VERSION ""

NS_ :

BS_:

BU_: SVB1 Tester Gateway CDS1 CDS2 ADV IRC AVP AVM PDC ADB1 ADB2 HDMAP DSM Fradar LCDA1 LCDA2

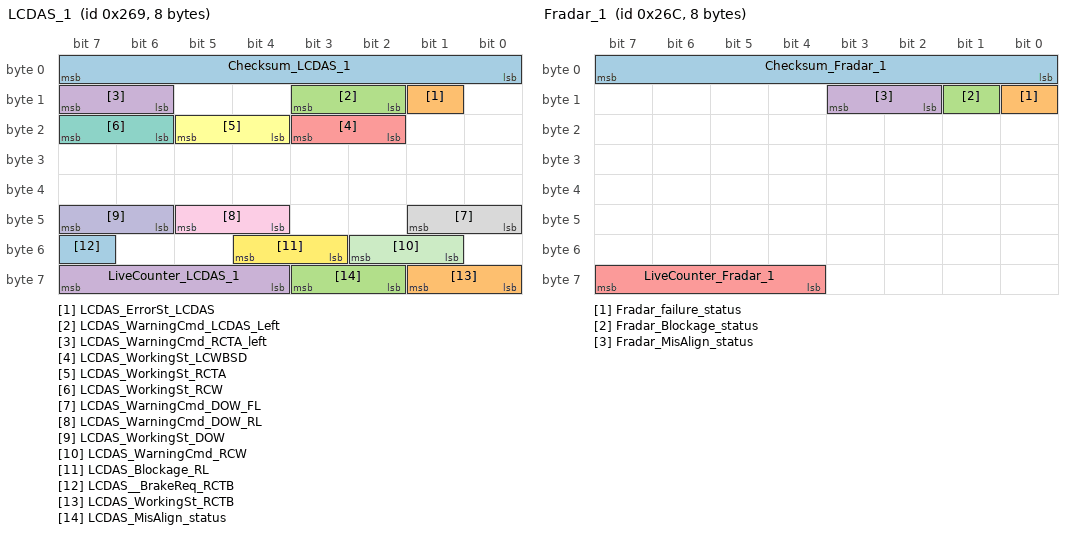
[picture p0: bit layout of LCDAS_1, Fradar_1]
BO_ 617 LCDAS_1: 8 CDS1
 SG_ Checksum_LCDAS_1 : 0|8@1+ (1,0) [0|255] ""  Gateway,ADV,LCDA1
 SG_ LCDAS_ErrorSt_LCDAS : 9|1@1+ (1,0) [0|1] ""  ADV
 SG_ LCDAS_WarningCmd_LCDAS_Left : 10|2@1+ (1,0) [0|3] ""  LCDA1
 SG_ LCDAS_WarningCmd_RCTA_left : 14|2@1+ (1,0) [0|3] ""  LCDA1
 SG_ LCDAS_WorkingSt_LCWBSD : 18|2@1+ (1,0) [0|3] ""  LCDA1
 SG_ LCDAS_WorkingSt_RCTA : 20|2@1+ (1,0) [0|3] ""  LCDA1
 SG_ LCDAS_WorkingSt_RCW : 22|2@1+ (1,0) [0|3] ""  LCDA1
 SG_ LCDAS_WarningCmd_DOW_FL : 40|2@1+ (1,0) [0|3] ""  LCDA1
 SG_ LCDAS_WarningCmd_DOW_RL : 44|2@1+ (1,0) [0|3] ""  LCDA1
 SG_ LCDAS_WorkingSt_DOW : 46|2@1+ (1,0) [0|3] ""  LCDA1
 SG_ LCDAS_WarningCmd_RCW : 49|2@1+ (1,0) [0|3] ""  LCDA1
 SG_ LCDAS_Blockage_RL : 51|2@1+ (1,0) [0|1] ""  Gateway,ADV
 SG_ LCDAS__BrakeReq_RCTB : 55|1@1+ (1,0) [0|1] ""  ADV,LCDA1
 SG_ LCDAS_WorkingSt_RCTB : 56|2@1+ (1,0) [0|3] ""  LCDA1
 SG_ LCDAS_MisAlign_status : 58|2@1+ (1,0) [0|3] ""  ADV
 SG_ LiveCounter_LCDAS_1 : 60|4@1+ (1,0) [0|15] "Pulse"  Gateway,ADV,LCDA1

BO_ 620 Fradar_1: 8 Fradar
 SG_ Checksum_Fradar_1 : 0|8@1+ (1,0) [0|255] ""  Gateway,AVP
 SG_ Fradar_failure_status : 8|1@1+ (1,0) [0|1] ""  AVP
 SG_ Fradar_Blockage_status : 9|1@1+ (1,0) [0|1] ""  Gateway,AVP
 SG_ Fradar_MisAlign_status : 10|2@1+ (1,0) [0|3] ""  AVP
 SG_ LiveCounter_Fradar_1 : 60|4@1+ (1,0) [0|15] ""  Gateway,AVP

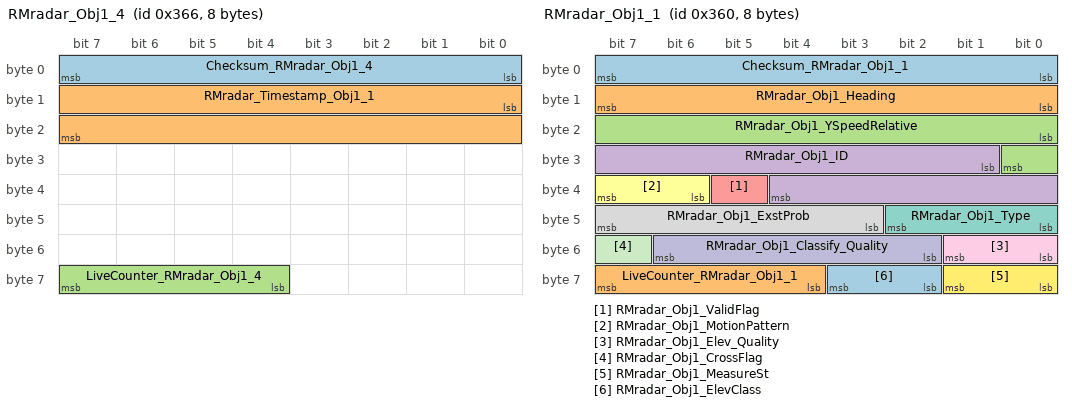
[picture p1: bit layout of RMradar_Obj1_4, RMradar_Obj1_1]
BO_ 870 RMradar_Obj1_4: 8 LCDA1
 SG_ Checksum_RMradar_Obj1_4 : 0|8@1+ (1,0) [0|255] ""  ADV
 SG_ RMradar_Timestamp_Obj1_1 : 8|16@1+ (0.1,0) [0|6553.5] "ms"  ADV
 SG_ LiveCounter_RMradar_Obj1_4 : 60|4@1+ (1,0) [0|15] ""  ADV

BO_ 864 RMradar_Obj1_1: 8 LCDA1
 SG_ Checksum_RMradar_Obj1_1 : 0|8@1+ (1,0) [0|255] ""  ADV
 SG_ RMradar_Obj1_Heading : 8|8@1+ (2.88,-180) [-180|554.4] "°„"  ADV
 SG_ RMradar_Obj1_YSpeedRelative : 16|9@1+ (0.2,-50) [-50|52.2] "m/s"  ADV
 SG_ RMradar_Obj1_ID : 25|12@1+ (1,0) [0|4095] ""  ADV
 SG_ RMradar_Obj1_ValidFlag : 37|1@1+ (1,0) [0|1] ""  ADV
 SG_ RMradar_Obj1_MotionPattern : 38|2@1+ (1,0) [0|3] ""  ADV
 SG_ RMradar_Obj1_Type : 40|3@1+ (1,0) [0|7] ""  ADV
 SG_ RMradar_Obj1_ExstProb : 43|5@1+ (5,0) [0|155] "%"  ADV
 SG_ RMradar_Obj1_Elev_Quality : 48|2@1+ (1,0) [0|3] ""  ADV
 SG_ RMradar_Obj1_Classify_Quality : 50|5@1+ (5,0) [0|155] "%"  ADV
 SG_ RMradar_Obj1_CrossFlag : 55|1@1+ (1,0) [0|1] ""  ADV
 SG_ RMradar_Obj1_MeasureSt : 56|2@1+ (1,0) [0|3] ""  ADV
 SG_ RMradar_Obj1_ElevClass : 58|2@1+ (1,0) [0|3] ""  ADV
 SG_ LiveCounter_RMradar_Obj1_1 : 60|4@1+ (1,0) [0|15] ""  ADV

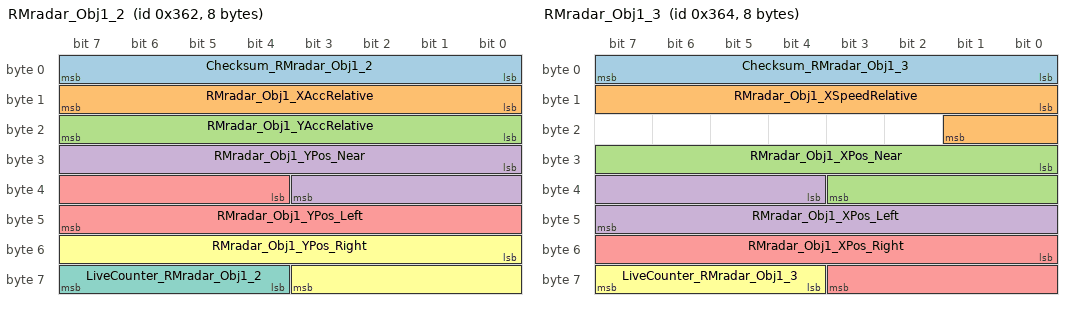
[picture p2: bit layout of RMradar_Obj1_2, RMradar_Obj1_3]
BO_ 866 RMradar_Obj1_2: 8 LCDA1
 SG_ Checksum_RMradar_Obj1_2 : 0|8@1+ (1,0) [0|255] ""  ADV
 SG_ RMradar_Obj1_XAccRelative : 8|8@1+ (0.2,-25.3) [-25.3|25.7] "m/s2"  ADV
 SG_ RMradar_Obj1_YAccRelative : 16|8@1+ (0.2,-25.3) [-25.3|25.7] "m/s2"  ADV
 SG_ RMradar_Obj1_YPos_Near : 24|12@1+ (0.05,-100) [-100|104.75] "m"  ADV
 SG_ RMradar_Obj1_YPos_Left : 36|12@1+ (0.05,-100) [-100|104.75] "m"  ADV
 SG_ RMradar_Obj1_YPos_Right : 48|12@1+ (0.05,-100) [-100|104.75] "m"  ADV
 SG_ LiveCounter_RMradar_Obj1_2 : 60|4@1+ (1,0) [0|15] ""  ADV

BO_ 868 RMradar_Obj1_3: 8 LCDA1
 SG_ Checksum_RMradar_Obj1_3 : 0|8@1+ (1,0) [0|255] ""  ADV
 SG_ RMradar_Obj1_XSpeedRelative : 8|10@1+ (0.2,-80) [-80|124.6] "m/s"  ADV
 SG_ RMradar_Obj1_XPos_Near : 24|12@1+ (0.05,-100) [-100|104.75] "m"  ADV
 SG_ RMradar_Obj1_XPos_Left : 36|12@1+ (0.05,-100) [-100|104.75] "m"  ADV
 SG_ RMradar_Obj1_XPos_Right : 48|12@1+ (0.05,-100) [-100|104.75] "m"  ADV
 SG_ LiveCounter_RMradar_Obj1_3 : 60|4@1+ (1,0) [0|15] ""  ADV

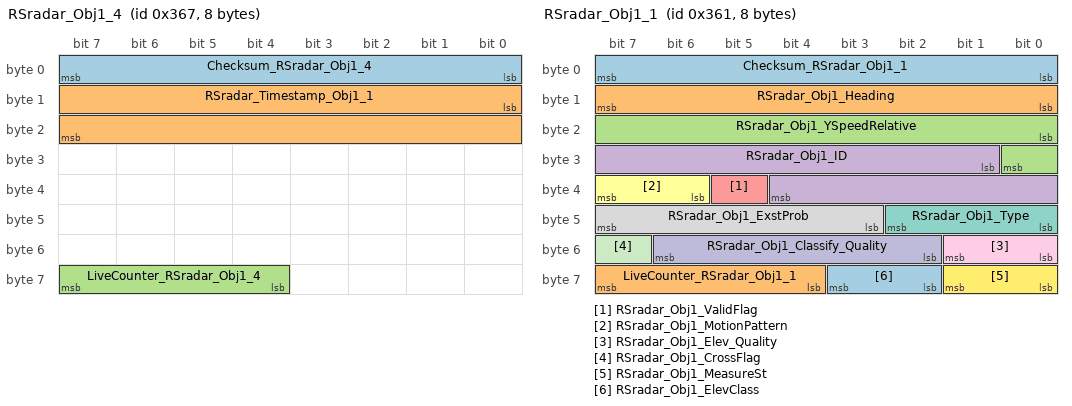
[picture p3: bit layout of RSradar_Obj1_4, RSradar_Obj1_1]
BO_ 871 RSradar_Obj1_4: 8 LCDA2
 SG_ Checksum_RSradar_Obj1_4 : 0|8@1+ (1,0) [0|255] ""  ADV
 SG_ RSradar_Timestamp_Obj1_1 : 8|16@1+ (0.1,0) [0|6553.5] "ms"  ADV
 SG_ LiveCounter_RSradar_Obj1_4 : 60|4@1+ (1,0) [0|15] ""  ADV

BO_ 865 RSradar_Obj1_1: 8 LCDA2
 SG_ Checksum_RSradar_Obj1_1 : 0|8@1+ (1,0) [0|255] ""  ADV
 SG_ RSradar_Obj1_Heading : 8|8@1+ (2.88,-180) [-180|554.4] "°„"  ADV
 SG_ RSradar_Obj1_YSpeedRelative : 16|9@1+ (0.2,-50) [-50|52.2] "m/s"  ADV
 SG_ RSradar_Obj1_ID : 25|12@1+ (1,0) [0|4095] ""  ADV
 SG_ RSradar_Obj1_ValidFlag : 37|1@1+ (1,0) [0|1] ""  ADV
 SG_ RSradar_Obj1_MotionPattern : 38|2@1+ (1,0) [0|3] ""  ADV
 SG_ RSradar_Obj1_Type : 40|3@1+ (1,0) [0|7] ""  ADV
 SG_ RSradar_Obj1_ExstProb : 43|5@1+ (5,0) [0|155] "%"  ADV
 SG_ RSradar_Obj1_Elev_Quality : 48|2@1+ (1,0) [0|3] ""  ADV
 SG_ RSradar_Obj1_Classify_Quality : 50|5@1+ (5,0) [0|155] "%"  ADV
 SG_ RSradar_Obj1_CrossFlag : 55|1@1+ (1,0) [0|1] ""  ADV
 SG_ RSradar_Obj1_MeasureSt : 56|2@1+ (1,0) [0|3] ""  ADV
 SG_ RSradar_Obj1_ElevClass : 58|2@1+ (1,0) [0|3] ""  ADV
 SG_ LiveCounter_RSradar_Obj1_1 : 60|4@1+ (1,0) [0|15] ""  ADV

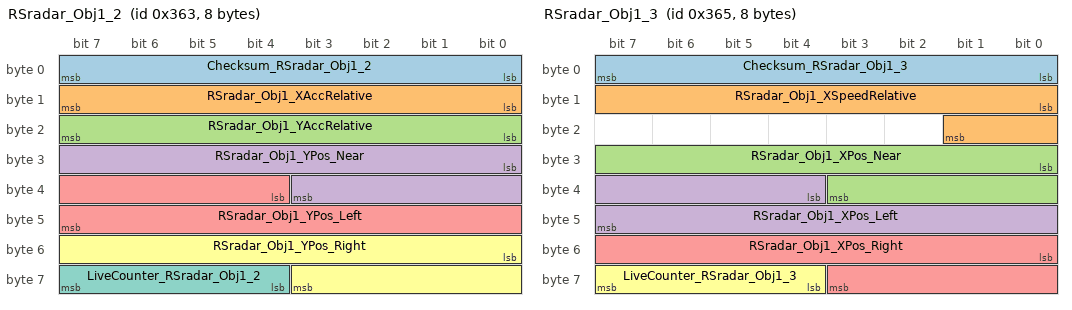
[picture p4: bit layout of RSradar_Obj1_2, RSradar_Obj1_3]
BO_ 867 RSradar_Obj1_2: 8 LCDA2
 SG_ Checksum_RSradar_Obj1_2 : 0|8@1+ (1,0) [0|255] ""  ADV
 SG_ RSradar_Obj1_XAccRelative : 8|8@1+ (0.2,-25.3) [-25.3|25.7] "m/s2"  ADV
 SG_ RSradar_Obj1_YAccRelative : 16|8@1+ (0.2,-25.3) [-25.3|25.7] "m/s2"  ADV
 SG_ RSradar_Obj1_YPos_Near : 24|12@1+ (0.05,-100) [-100|104.75] "m"  ADV
 SG_ RSradar_Obj1_YPos_Left : 36|12@1+ (0.05,-100) [-100|104.75] "m"  ADV
 SG_ RSradar_Obj1_YPos_Right : 48|12@1+ (0.05,-100) [-100|104.75] "m"  ADV
 SG_ LiveCounter_RSradar_Obj1_2 : 60|4@1+ (1,0) [0|15] ""  ADV

BO_ 869 RSradar_Obj1_3: 8 LCDA2
 SG_ Checksum_RSradar_Obj1_3 : 0|8@1+ (1,0) [0|255] ""  ADV
 SG_ RSradar_Obj1_XSpeedRelative : 8|10@1+ (0.2,-80) [-80|124.6] "m/s"  ADV
 SG_ RSradar_Obj1_XPos_Near : 24|12@1+ (0.05,-100) [-100|104.75] "m"  ADV
 SG_ RSradar_Obj1_XPos_Left : 36|12@1+ (0.05,-100) [-100|104.75] "m"  ADV
 SG_ RSradar_Obj1_XPos_Right : 48|12@1+ (0.05,-100) [-100|104.75] "m"  ADV
 SG_ LiveCounter_RSradar_Obj1_3 : 60|4@1+ (1,0) [0|15] ""  ADV

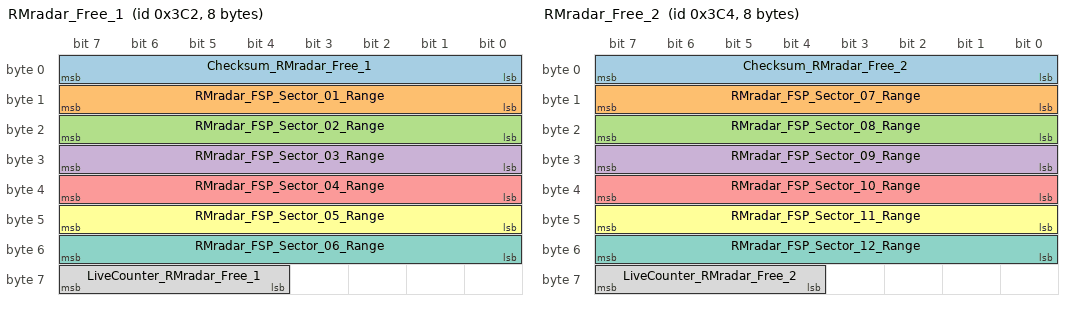
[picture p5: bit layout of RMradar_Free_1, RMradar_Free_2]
BO_ 962 RMradar_Free_1: 8 LCDA1
 SG_ Checksum_RMradar_Free_1 : 0|8@1+ (1,0) [0|255] ""  ADV
 SG_ RMradar_FSP_Sector_01_Range : 8|8@1+ (0.2,0) [0|51] "m"  ADV
 SG_ RMradar_FSP_Sector_02_Range : 16|8@1+ (0.2,0) [0|51] "m"  ADV
 SG_ RMradar_FSP_Sector_03_Range : 24|8@1+ (0.2,0) [0|51] "m"  ADV
 SG_ RMradar_FSP_Sector_04_Range : 32|8@1+ (0.2,0) [0|51] "m"  ADV
 SG_ RMradar_FSP_Sector_05_Range : 40|8@1+ (0.2,0) [0|51] "m"  ADV
 SG_ RMradar_FSP_Sector_06_Range : 48|8@1+ (0.2,0) [0|51] "m"  ADV
 SG_ LiveCounter_RMradar_Free_1 : 60|4@1+ (1,0) [0|15] ""  ADV

BO_ 964 RMradar_Free_2: 8 LCDA1
 SG_ Checksum_RMradar_Free_2 : 0|8@1+ (1,0) [0|255] ""  ADV
 SG_ RMradar_FSP_Sector_07_Range : 8|8@1+ (0.2,0) [0|51] "m"  ADV
 SG_ RMradar_FSP_Sector_08_Range : 16|8@1+ (0.2,0) [0|51] "m"  ADV
 SG_ RMradar_FSP_Sector_09_Range : 24|8@1+ (0.2,0) [0|51] "m"  ADV
 SG_ RMradar_FSP_Sector_10_Range : 32|8@1+ (0.2,0) [0|51] "m"  ADV
 SG_ RMradar_FSP_Sector_11_Range : 40|8@1+ (0.2,0) [0|51] "m"  ADV
 SG_ RMradar_FSP_Sector_12_Range : 48|8@1+ (0.2,0) [0|51] "m"  ADV
 SG_ LiveCounter_RMradar_Free_2 : 60|4@1+ (1,0) [0|15] ""  ADV

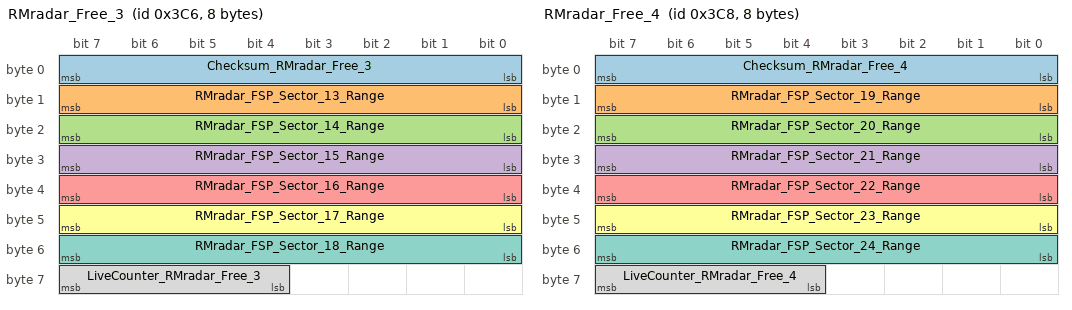
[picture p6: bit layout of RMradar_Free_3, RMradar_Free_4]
BO_ 966 RMradar_Free_3: 8 LCDA1
 SG_ Checksum_RMradar_Free_3 : 0|8@1+ (1,0) [0|255] ""  ADV
 SG_ RMradar_FSP_Sector_13_Range : 8|8@1+ (0.2,0) [0|51] "m"  ADV
 SG_ RMradar_FSP_Sector_14_Range : 16|8@1+ (0.2,0) [0|51] "m"  ADV
 SG_ RMradar_FSP_Sector_15_Range : 24|8@1+ (0.2,0) [0|51] "m"  ADV
 SG_ RMradar_FSP_Sector_16_Range : 32|8@1+ (0.2,0) [0|51] "m"  ADV
 SG_ RMradar_FSP_Sector_17_Range : 40|8@1+ (0.2,0) [0|51] "m"  ADV
 SG_ RMradar_FSP_Sector_18_Range : 48|8@1+ (0.2,0) [0|51] "m"  ADV
 SG_ LiveCounter_RMradar_Free_3 : 60|4@1+ (1,0) [0|15] ""  ADV

BO_ 968 RMradar_Free_4: 8 LCDA1
 SG_ Checksum_RMradar_Free_4 : 0|8@1+ (1,0) [0|255] ""  ADV
 SG_ RMradar_FSP_Sector_19_Range : 8|8@1+ (0.2,0) [0|51] "m"  ADV
 SG_ RMradar_FSP_Sector_20_Range : 16|8@1+ (0.2,0) [0|51] "m"  ADV
 SG_ RMradar_FSP_Sector_21_Range : 24|8@1+ (0.2,0) [0|51] "m"  ADV
 SG_ RMradar_FSP_Sector_22_Range : 32|8@1+ (0.2,0) [0|51] "m"  ADV
 SG_ RMradar_FSP_Sector_23_Range : 40|8@1+ (0.2,0) [0|51] "m"  ADV
 SG_ RMradar_FSP_Sector_24_Range : 48|8@1+ (0.2,0) [0|51] "m"  ADV
 SG_ LiveCounter_RMradar_Free_4 : 60|4@1+ (1,0) [0|15] ""  ADV

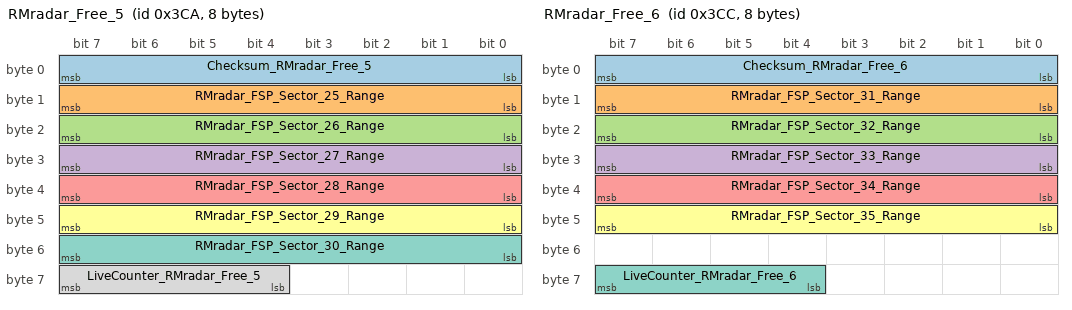
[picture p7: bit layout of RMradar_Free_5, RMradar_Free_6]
BO_ 970 RMradar_Free_5: 8 LCDA1
 SG_ Checksum_RMradar_Free_5 : 0|8@1+ (1,0) [0|255] ""  ADV
 SG_ RMradar_FSP_Sector_25_Range : 8|8@1+ (0.2,0) [0|51] "m"  ADV
 SG_ RMradar_FSP_Sector_26_Range : 16|8@1+ (0.2,0) [0|51] "m"  ADV
 SG_ RMradar_FSP_Sector_27_Range : 24|8@1+ (0.2,0) [0|51] "m"  ADV
 SG_ RMradar_FSP_Sector_28_Range : 32|8@1+ (0.2,0) [0|51] "m"  ADV
 SG_ RMradar_FSP_Sector_29_Range : 40|8@1+ (0.2,0) [0|51] "m"  ADV
 SG_ RMradar_FSP_Sector_30_Range : 48|8@1+ (0.2,0) [0|51] "m"  ADV
 SG_ LiveCounter_RMradar_Free_5 : 60|4@1+ (1,0) [0|15] ""  ADV

BO_ 972 RMradar_Free_6: 8 LCDA1
 SG_ Checksum_RMradar_Free_6 : 0|8@1+ (1,0) [0|255] ""  ADV
 SG_ RMradar_FSP_Sector_31_Range : 8|8@1+ (0.2,0) [0|51] "m"  ADV
 SG_ RMradar_FSP_Sector_32_Range : 16|8@1+ (0.2,0) [0|51] "m"  ADV
 SG_ RMradar_FSP_Sector_33_Range : 24|8@1+ (0.2,0) [0|51] "m"  ADV
 SG_ RMradar_FSP_Sector_34_Range : 32|8@1+ (0.2,0) [0|51] "m"  ADV
 SG_ RMradar_FSP_Sector_35_Range : 40|8@1+ (0.2,0) [0|51] "m"  ADV
 SG_ LiveCounter_RMradar_Free_6 : 60|4@1+ (1,0) [0|15] ""  ADV

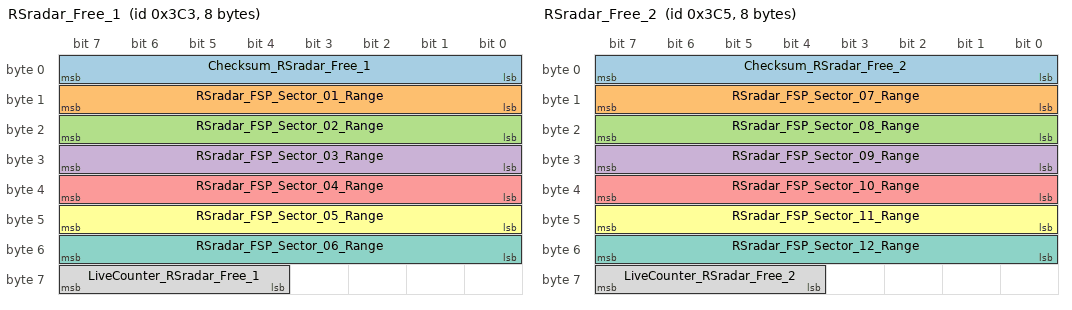
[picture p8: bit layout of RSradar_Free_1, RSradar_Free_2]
BO_ 963 RSradar_Free_1: 8 LCDA2
 SG_ Checksum_RSradar_Free_1 : 0|8@1+ (1,0) [0|255] ""  ADV
 SG_ RSradar_FSP_Sector_01_Range : 8|8@1+ (0.2,0) [0|51] "m"  ADV
 SG_ RSradar_FSP_Sector_02_Range : 16|8@1+ (0.2,0) [0|51] "m"  ADV
 SG_ RSradar_FSP_Sector_03_Range : 24|8@1+ (0.2,0) [0|51] "m"  ADV
 SG_ RSradar_FSP_Sector_04_Range : 32|8@1+ (0.2,0) [0|51] "m"  ADV
 SG_ RSradar_FSP_Sector_05_Range : 40|8@1+ (0.2,0) [0|51] "m"  ADV
 SG_ RSradar_FSP_Sector_06_Range : 48|8@1+ (0.2,0) [0|51] "m"  ADV
 SG_ LiveCounter_RSradar_Free_1 : 60|4@1+ (1,0) [0|15] ""  ADV

BO_ 965 RSradar_Free_2: 8 LCDA2
 SG_ Checksum_RSradar_Free_2 : 0|8@1+ (1,0) [0|255] ""  ADV
 SG_ RSradar_FSP_Sector_07_Range : 8|8@1+ (0.2,0) [0|51] "m"  ADV
 SG_ RSradar_FSP_Sector_08_Range : 16|8@1+ (0.2,0) [0|51] "m"  ADV
 SG_ RSradar_FSP_Sector_09_Range : 24|8@1+ (0.2,0) [0|51] "m"  ADV
 SG_ RSradar_FSP_Sector_10_Range : 32|8@1+ (0.2,0) [0|51] "m"  ADV
 SG_ RSradar_FSP_Sector_11_Range : 40|8@1+ (0.2,0) [0|51] "m"  ADV
 SG_ RSradar_FSP_Sector_12_Range : 48|8@1+ (0.2,0) [0|51] "m"  ADV
 SG_ LiveCounter_RSradar_Free_2 : 60|4@1+ (1,0) [0|15] ""  ADV

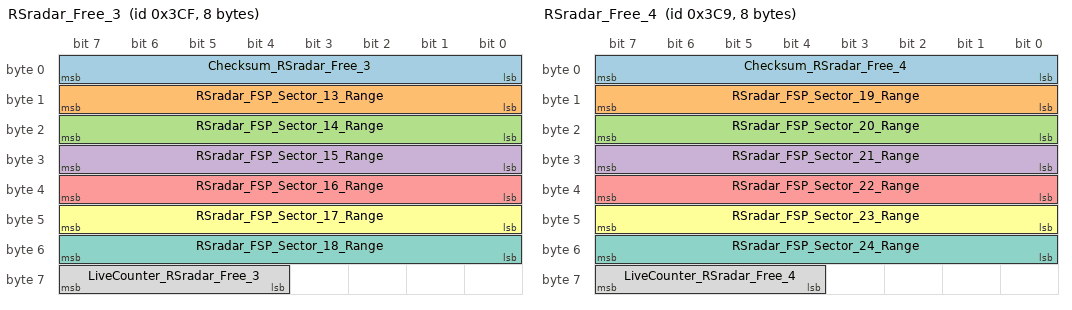
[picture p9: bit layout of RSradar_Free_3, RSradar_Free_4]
BO_ 975 RSradar_Free_3: 8 LCDA2
 SG_ Checksum_RSradar_Free_3 : 0|8@1+ (1,0) [0|255] ""  ADV
 SG_ RSradar_FSP_Sector_13_Range : 8|8@1+ (0.2,0) [0|51] "m"  ADV
 SG_ RSradar_FSP_Sector_14_Range : 16|8@1+ (0.2,0) [0|51] "m"  ADV
 SG_ RSradar_FSP_Sector_15_Range : 24|8@1+ (0.2,0) [0|51] "m"  ADV
 SG_ RSradar_FSP_Sector_16_Range : 32|8@1+ (0.2,0) [0|51] "m"  ADV
 SG_ RSradar_FSP_Sector_17_Range : 40|8@1+ (0.2,0) [0|51] "m"  ADV
 SG_ RSradar_FSP_Sector_18_Range : 48|8@1+ (0.2,0) [0|51] "m"  ADV
 SG_ LiveCounter_RSradar_Free_3 : 60|4@1+ (1,0) [0|15] ""  ADV

BO_ 969 RSradar_Free_4: 8 LCDA2
 SG_ Checksum_RSradar_Free_4 : 0|8@1+ (1,0) [0|255] ""  ADV
 SG_ RSradar_FSP_Sector_19_Range : 8|8@1+ (0.2,0) [0|51] "m"  ADV
 SG_ RSradar_FSP_Sector_20_Range : 16|8@1+ (0.2,0) [0|51] "m"  ADV
 SG_ RSradar_FSP_Sector_21_Range : 24|8@1+ (0.2,0) [0|51] "m"  ADV
 SG_ RSradar_FSP_Sector_22_Range : 32|8@1+ (0.2,0) [0|51] "m"  ADV
 SG_ RSradar_FSP_Sector_23_Range : 40|8@1+ (0.2,0) [0|51] "m"  ADV
 SG_ RSradar_FSP_Sector_24_Range : 48|8@1+ (0.2,0) [0|51] "m"  ADV
 SG_ LiveCounter_RSradar_Free_4 : 60|4@1+ (1,0) [0|15] ""  ADV

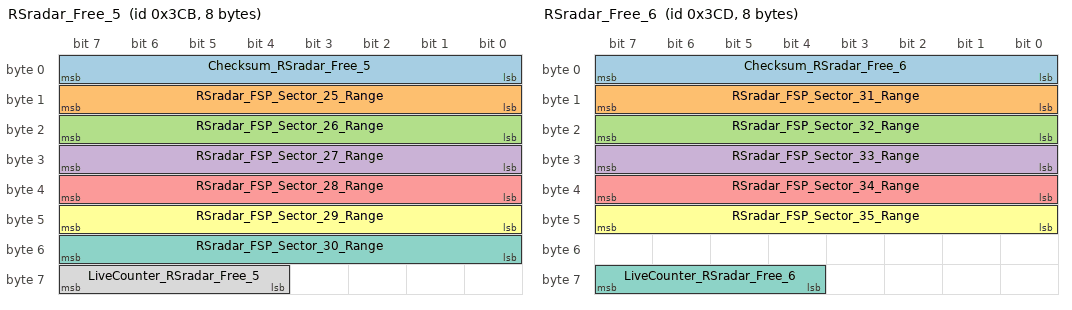
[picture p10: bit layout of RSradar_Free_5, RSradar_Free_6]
BO_ 971 RSradar_Free_5: 8 LCDA2
 SG_ Checksum_RSradar_Free_5 : 0|8@1+ (1,0) [0|255] ""  ADV
 SG_ RSradar_FSP_Sector_25_Range : 8|8@1+ (0.2,0) [0|51] "m"  ADV
 SG_ RSradar_FSP_Sector_26_Range : 16|8@1+ (0.2,0) [0|51] "m"  ADV
 SG_ RSradar_FSP_Sector_27_Range : 24|8@1+ (0.2,0) [0|51] "m"  ADV
 SG_ RSradar_FSP_Sector_28_Range : 32|8@1+ (0.2,0) [0|51] "m"  ADV
 SG_ RSradar_FSP_Sector_29_Range : 40|8@1+ (0.2,0) [0|51] "m"  ADV
 SG_ RSradar_FSP_Sector_30_Range : 48|8@1+ (0.2,0) [0|51] "m"  ADV
 SG_ LiveCounter_RSradar_Free_5 : 60|4@1+ (1,0) [0|15] ""  ADV

BO_ 973 RSradar_Free_6: 8 LCDA2
 SG_ Checksum_RSradar_Free_6 : 0|8@1+ (1,0) [0|255] ""  ADV
 SG_ RSradar_FSP_Sector_31_Range : 8|8@1+ (0.2,0) [0|51] "m"  ADV
 SG_ RSradar_FSP_Sector_32_Range : 16|8@1+ (0.2,0) [0|51] "m"  ADV
 SG_ RSradar_FSP_Sector_33_Range : 24|8@1+ (0.2,0) [0|51] "m"  ADV
 SG_ RSradar_FSP_Sector_34_Range : 32|8@1+ (0.2,0) [0|51] "m"  ADV
 SG_ RSradar_FSP_Sector_35_Range : 40|8@1+ (0.2,0) [0|51] "m"  ADV
 SG_ LiveCounter_RSradar_Free_6 : 60|4@1+ (1,0) [0|15] ""  ADV

BO_ 602 HAD_7: 8 CDS1
 SG_ Checksum_HAD_7 : 0|8@1+ (1,0) [0|255] ""  Gateway
 SG_ HAD_SetMaxVehcleSpeedFunSt : 8|1@1+ (1,0) [0|1] ""  Gateway
 SG_ HAD_MaxVehcleSpeedSetted : 9|5@1+ (5,0) [0|155] "Km/h"  Gateway
 SG_ HAD_ChangeLaneAuto_Feedback : 16|3@1+ (1,0) [0|7] ""  Gateway
 SG_ HAD_RampSt_FR : 23|1@1+ (1,0) [0|1] ""  Gateway
 SG_ HAD_RampSt_FL : 24|1@1+ (1,0) [0|1] ""  Gateway
 SG_ HAD_GeoFenceAway : 25|1@1+ (1,0) [0|1] ""  Gateway
 SG_ HAD_TunnelSt_Ahead : 26|1@1+ (1,0) [0|1] ""  Gateway
 SG_ HAD_TollGateSt_Ahead : 27|1@1+ (1,0) [0|1] ""  Gateway
 SG_ HAD_RoadEnd_Ahead : 28|1@1+ (1,0) [0|1] ""  Gateway
 SG_ HAD_LaneEnd_Ahead : 29|1@1+ (1,0) [0|1] ""  Gateway
 SG_ HAD_Merge_Ahead : 30|1@1+ (1,0) [0|1] ""  Gateway
 SG_ HAD_AccidentsPotencial_Ahead : 31|1@1+ (1,0) [0|1] ""  Gateway
 SG_ HAD_RoadWork_Ahead : 32|1@1+ (1,0) [0|1] ""  Gateway
 SG_ HAD_LaneLineFade_Ahead : 33|1@1+ (1,0) [0|1] ""  Gateway
 SG_ HAD_RockfallPotencial_Ahead : 34|1@1+ (1,0) [0|1] ""  Gateway
 SG_ HAD_LaneLineCaptured_LL : 35|1@1+ (1,0) [0|1] ""  Gateway
 SG_ HAD_LaneLineCaptured_L : 36|1@1+ (1,0) [0|1] ""  Gateway
 SG_ HAD_LaneLineCaptured_RR : 37|1@1+ (1,0) [0|1] ""  Gateway
 SG_ HAD_LaneLineCaptured_R : 38|1@1+ (1,0) [0|1] ""  Gateway
 SG_ HAD_LaneLineType_LL : 40|3@1+ (1,0) [0|7] ""  Gateway
 SG_ HAD_LaneLineType_L : 43|3@1+ (1,0) [0|7] ""  Gateway
 SG_ HAD_LaneLineType_RR : 48|3@1+ (1,0) [0|7] ""  Gateway
 SG_ HAD_LaneLineType_R : 51|3@1+ (1,0) [0|7] ""  Gateway
 SG_ HAD_VehcleStatus_Ego : 56|4@1+ (1,0) [0|15] ""  Gateway
 SG_ LiveCounter_HAD_7 : 60|4@1+ (1,0) [0|15] "Pulse"  Gateway

BO_ 603 HAD_8: 8 CDS1
 SG_ Checksum_HAD_8 : 0|8@1+ (1,0) [0|255] ""  Gateway
 SG_ HAD_VehcleStatus_Front : 8|3@1+ (1,0) [0|7] ""  Gateway
 SG_ HAD_VehcleStatus_Left : 11|3@1+ (1,0) [0|7] ""  Gateway
 SG_ HAD_VehcleStatus_Right : 16|3@1+ (1,0) [0|7] ""  Gateway
 SG_ HAD_VehcleStatus_FR : 19|3@1+ (1,0) [0|7] ""  Gateway
 SG_ HAD_VehcleStatus_FL : 24|3@1+ (1,0) [0|7] ""  Gateway
 SG_ HAD_VehcleStatus_RR : 27|3@1+ (1,0) [0|7] ""  Gateway
 SG_ HAD_VRU_FL : 30|2@1+ (1,0) [0|3] ""  Gateway
 SG_ HAD_VehcleStatus_RL : 32|3@1+ (1,0) [0|7] ""  Gateway
 SG_ HAD_LateralPosition_FrontVehcle : 35|3@1+ (1,0) [0|7] ""  Gateway
 SG_ HAD_VRU_FR : 38|2@1+ (1,0) [0|3] ""  Gateway
 SG_ HAD_LongitudinalPosition_FrontVe : 40|3@1+ (1,0) [0|7] ""  Gateway
 SG_ HAD_LateralPosition_FRVehcle : 43|3@1+ (1,0) [0|7] ""  Gateway
 SG_ HAD_VRU_Front : 46|2@1+ (1,0) [0|3] ""  Gateway
 SG_ HAD_LateralPosition_FLVehcle : 48|3@1+ (1,0) [0|7] ""  Gateway
 SG_ HAD_LateralPosition_LeftVehcle : 51|3@1+ (1,0) [0|7] ""  Gateway
 SG_ HAD_LateralPosition_RightVehcle : 56|3@1+ (1,0) [0|7] ""  Gateway
 SG_ LiveCounter_HAD_8 : 60|4@1+ (1,0) [0|15] "Pulse"  Gateway

BO_ 606 HAD_9: 8 CDS1
 SG_ Checksum_HAD_9 : 0|8@1+ (1,0) [0|255] ""  Gateway
 SG_ HAD_LateralPosition_RLVehcle : 8|3@1+ (1,0) [0|7] ""  Gateway
 SG_ HAD_LateralPosition_RRVehcle : 11|3@1+ (1,0) [0|7] ""  Gateway
 SG_ HAD_FrontVehcle_CIPV : 14|1@1+ (1,0) [0|1] ""  Gateway
 SG_ HAD_FRVehcle_CIPV : 15|1@1+ (1,0) [0|1] ""  Gateway
 SG_ HAD_FLVehcle_CIPV : 16|1@1+ (1,0) [0|1] ""  Gateway
 SG_ HAD_LeftVehcle_CIPV : 17|1@1+ (1,0) [0|1] ""  Gateway
 SG_ HAD_RightVehcle_CIPV : 18|1@1+ (1,0) [0|1] ""  Gateway
 SG_ HAD_RRVehcle_CIPV : 19|1@1+ (1,0) [0|1] ""  Gateway
 SG_ HAD_RLVehcle_CIPV : 20|1@1+ (1,0) [0|1] ""  Gateway
 SG_ HAD_ErrorSt : 21|1@1+ (1,0) [0|1] ""  Gateway
 SG_ HAD_BrakeLightCtrlCmd : 22|1@1+ (1,0) [0|1] ""  Gateway
 SG_ HAD_LaneShap_Ego : 24|3@1+ (1,0) [0|7] ""  Gateway
 SG_ HAD_LaneShap_Left : 27|3@1+ (1,0) [0|7] ""  Gateway
 SG_ HAD_LowBeamReq : 30|2@1+ (1,0) [0|3] ""  Gateway
 SG_ HAD_LaneShap_Right : 32|3@1+ (1,0) [0|7] ""  Gateway
 SG_ HAD_LaneWidth_Ego : 35|3@1+ (1,0) [0|7] ""  Gateway
 SG_ HAD_HighBeamReq : 38|2@1+ (1,0) [0|3] ""  Gateway
 SG_ HAD_LaneWidth_Left : 40|3@1+ (1,0) [0|7] ""  Gateway
 SG_ HAD_LaneWidth_Right : 43|3@1+ (1,0) [0|7] ""  Gateway
 SG_ HAD_AbnormalRoadAttention : 48|4@1+ (1,0) [0|15] ""  Gateway
 SG_ HAD_KeepHandsOnTip : 52|3@1+ (1,0) [0|7] ""  Gateway
 SG_ HAD_ChangeLaneFunctionForbidden : 55|1@1+ (1,0) [0|1] ""  Gateway
 SG_ HAD_ChangeLaneAuto_ConfirmFuncSt : 56|1@1+ (1,0) [0|1] ""  Gateway
 SG_ HAD_DriverViewStatus_L3 : 57|1@1+ (1,0) [0|1] ""  Gateway
 SG_ HAD_DriverHandsOnTip_L3 : 58|1@1+ (1,0) [0|1] ""  Gateway
 SG_ HAD_AccelerationPedalApplied : 59|1@1+ (1,0) [0|1] ""  Gateway
 SG_ LiveCounter_HAD_9 : 60|4@1+ (1,0) [0|15] "Pulse"  Gateway

BO_ 667 HU_10: 8 Gateway
 SG_ Checksum_HU_10 : 0|8@1+ (1,0) [0|255] ""  CDS2,SVB1,CDS1,ADV,PDC,LCDA1,LCDA2
 SG_ HU_HWPTJPReq : 8|2@1+ (1,0) [0|3] ""  CDS2,SVB1,CDS1
 SG_ HU_AVPFunctionReq : 10|2@1+ (1,0) [0|3] ""  CDS2,SVB1,CDS1
 SG_ HU_ChangeLaneAuto_ConfirmFuncReq : 12|2@1+ (1,0) [0|3] ""  CDS2,SVB1,CDS1
 SG_ FCWModeSet : 14|2@1+ (1,0) [0|3] ""  SVB1,CDS1,CDS2
 SG_ HU_ChangeLaneManualFuncReq : 16|2@1+ (1,0) [0|3] ""  CDS2,SVB1,CDS1
 SG_ HU_ChangeLaneAutoFuncReq : 18|2@1+ (1,0) [0|3] ""  CDS2,SVB1,CDS1
 SG_ HU_SetMaxVehcleSpeedFuncReq : 20|2@1+ (1,0) [0|3] ""  CDS2,SVB1,CDS1
 SG_ HU_PDCBuzzerReq : 22|2@1+ (1,0) [0|3] ""  CDS2,CDS1,SVB1,PDC
 SG_ HU_MaxVehcleSpeed_Set : 24|5@1+ (5,40) [40|195] "Km/h"  CDS2,SVB1,CDS1
 SG_ HU_LCDAFunctionReq : 30|2@1+ (1,0) [0|3] ""  CDS2,SVB1,CDS1,ADV,LCDA1,LCDA2
 SG_ HU_RCWFunctionReq : 32|2@1+ (1,0) [0|3] ""  CDS2,SVB1,CDS1,ADV,LCDA1,LCDA2
 SG_ HU_FCTAFunctionReq : 34|2@1+ (1,0) [0|3] ""  CDS2,SVB1,CDS1
 SG_ HU_RCTAFunctionReq : 36|2@1+ (1,0) [0|3] ""  CDS2,SVB1,CDS1,ADV,LCDA1,LCDA2
 SG_ HU_RCTABuzzerWarningFunReq : 38|2@1+ (1,0) [0|3] ""  CDS2,SVB1,CDS1,ADV,LCDA1
 SG_ HU_DOWFunctionReq : 40|2@1+ (1,0) [0|3] ""  CDS2,SVB1,CDS1,ADV,LCDA1,LCDA2
 SG_ HU_FCTBFunctionReq : 42|2@1+ (1,0) [0|3] ""  CDS2,SVB1,CDS1
 SG_ HU_RCTBFunctionReq : 44|2@1+ (1,0) [0|3] ""  CDS2,SVB1,CDS1,ADV,LCDA1,LCDA2
 SG_ HU_DestinationtipReq : 46|2@1+ (1,0) [0|3] ""  CDS2,SVB1,CDS1
 SG_ HU_AEBSensitivitySet : 56|2@1+ (1,0) [0|3] ""  SVB1,CDS1,CDS2
 SG_ HU_SetDestinationFunReq : 58|2@1+ (1,0) [0|3] ""  CDS2,SVB1,CDS1
 SG_ Livecounter_HU_10 : 60|4@1+ (1,0) [0|15] ""  CDS2,SVB1,CDS1,ADV,PDC,LCDA1,LCDA2

BO_ 576 BCM2_1: 8 Gateway
 SG_ PositionLightSt_RL : 0|1@1+ (1,0) [0|1] ""  SVB1,CDS2,CDS1,IRC
 SG_ PositionLightSt_RR : 1|1@1+ (1,0) [0|1] ""  SVB1,CDS2,CDS1,IRC
 SG_ FogLightSt_Rear : 2|1@1+ (1,0) [0|1] ""  SVB1,CDS2,CDS1,IRC
 SG_ FogLightSt_RL : 3|1@1+ (1,0) [0|1] ""  SVB1,CDS2,CDS1,IRC
 SG_ FogLightSt_RR : 4|1@1+ (1,0) [0|1] ""  SVB1,CDS2,CDS1,IRC
 SG_ FoglightFaultSt_Rear : 5|1@1+ (1,0) [0|1] ""  SVB1,CDS2,CDS1,IRC
 SG_ ReverseLightSt : 6|1@1+ (1,0) [0|1] ""  CDS1,SVB1,CDS2,IRC
 SG_ ReverseLightFaultSt : 7|1@1+ (1,0) [0|1] ""  CDS1,SVB1,CDS2,IRC
 SG_ LicenseLightSt : 8|1@1+ (1,0) [0|1] ""  CDS1,SVB1,CDS2,IRC
 SG_ LicenseLightFaultSt : 9|1@1+ (1,0) [0|1] ""  CDS1,SVB1,CDS2,IRC
 SG_ BrakeLightFaultSt_RL : 10|1@1+ (1,0) [0|1] ""  CDS1,SVB1,CDS2,IRC
 SG_ BrakeLightFaultSt_RR : 11|1@1+ (1,0) [0|1] ""  CDS1,SVB1,CDS2,IRC
 SG_ TurnLightFaultSt_RL : 12|1@1+ (1,0) [0|1] ""  SVB1,CDS2,CDS1,IRC
 SG_ TurnLightFaultSt_RR : 13|1@1+ (1,0) [0|1] ""  SVB1,CDS2,CDS1,IRC
 SG_ WashSysSt_Rear : 14|1@1+ (1,0) [0|1] ""  CDS1,SVB1,CDS2
 SG_ RearWindowHeatingStatus : 15|1@1+ (1,0) [0|1] ""  CDS1,SVB1,CDS2
 SG_ WiperSt_Rear : 16|1@1+ (1,0) [0|1] ""  SVB1,CDS2,CDS1,IRC
 SG_ PositionLightFaultSt_Rear : 17|1@1+ (1,0) [0|1] ""  SVB1,CDS2,CDS1,IRC
 SG_ BrakeLightSt_RL : 18|1@1+ (1,0) [0|1] ""  SVB1,CDS2,CDS1,IRC
 SG_ BrakeLightSt_RR : 19|1@1+ (1,0) [0|1] ""  SVB1,CDS2,CDS1,IRC

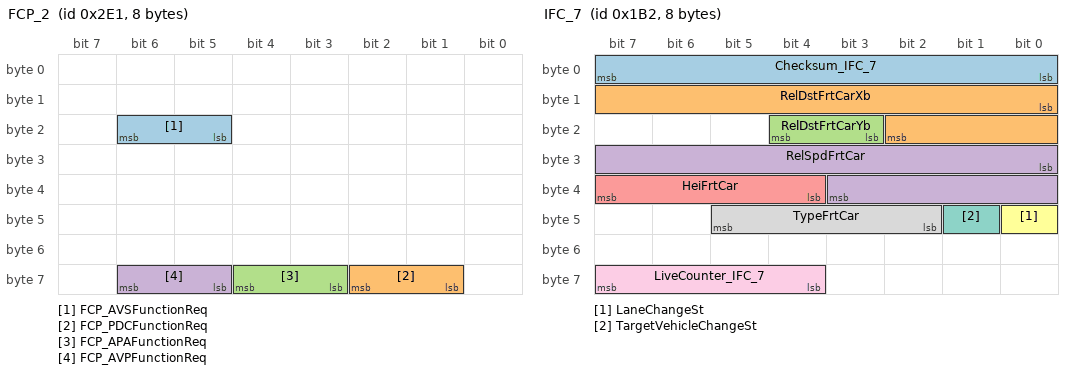
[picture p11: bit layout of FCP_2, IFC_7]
BO_ 737 FCP_2: 8 Gateway
 SG_ FCP_AVSFunctionReq : 21|2@1+ (1,0) [0|3] ""  AVP,AVM
 SG_ FCP_PDCFunctionReq : 57|2@1+ (1,0) [0|3] ""  PDC
 SG_ FCP_APAFunctionReq : 59|2@1+ (1,0) [0|3] ""  ADV
 SG_ FCP_AVPFunctionReq : 61|2@1+ (1,0) [0|3] ""  ADV

BO_ 434 IFC_7: 8 CDS2
 SG_ Checksum_IFC_7 : 0|8@1+ (1,0) [0|255] ""  Gateway
 SG_ RelDstFrtCarXb : 8|11@1+ (0.1,0) [0|204.7] "m"  Gateway
 SG_ RelDstFrtCarYb : 19|2@1+ (0.5,0) [0|1.5] "m"  Gateway
 SG_ RelSpdFrtCar : 24|12@1+ (0.0625,-128) [-128|127.938] "km/h"  Gateway
 SG_ HeiFrtCar : 36|4@1+ (0.5,0) [0|7.5] "m"  Gateway
 SG_ LaneChangeSt : 40|1@1+ (1,0) [0|1] ""  Gateway
 SG_ TargetVehicleChangeSt : 41|1@1+ (1,0) [0|1] ""  Gateway
 SG_ TypeFrtCar : 42|4@1+ (1,0) [0|15] ""  Gateway
 SG_ LiveCounter_IFC_7 : 60|4@1+ (1,0) [0|15] ""  Gateway

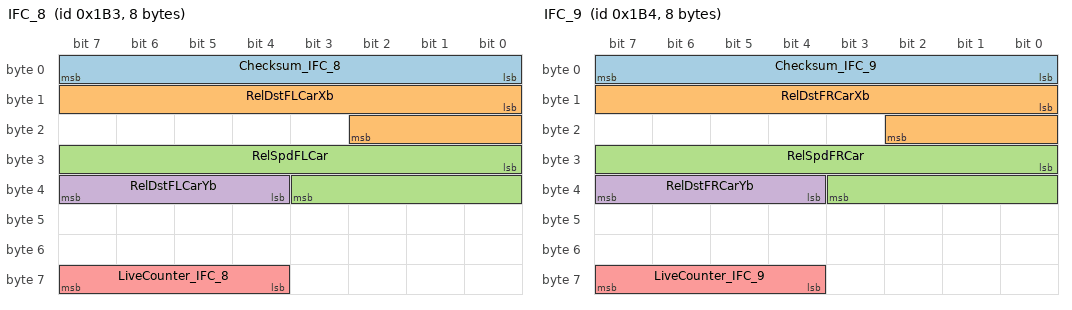
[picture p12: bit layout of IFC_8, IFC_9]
BO_ 435 IFC_8: 8 CDS2
 SG_ Checksum_IFC_8 : 0|8@1+ (1,0) [0|255] ""  Gateway
 SG_ RelDstFLCarXb : 8|11@1+ (0.1,0) [0|204.7] "m"  Gateway
 SG_ RelSpdFLCar : 24|12@1+ (0.0625,-128) [-128|127.938] "km/h"  Gateway
 SG_ RelDstFLCarYb : 36|4@1+ (0.5,0) [0|7.5] "m"  Gateway
 SG_ LiveCounter_IFC_8 : 60|4@1+ (1,0) [0|15] ""  Gateway

BO_ 436 IFC_9: 8 CDS2
 SG_ Checksum_IFC_9 : 0|8@1+ (1,0) [0|255] ""  Gateway
 SG_ RelDstFRCarXb : 8|11@1+ (0.1,0) [0|204.7] "m"  Gateway
 SG_ RelSpdFRCar : 24|12@1+ (0.0625,-128) [-128|127.938] "km/h"  Gateway
 SG_ RelDstFRCarYb : 36|4@1+ (0.5,0) [0|7.5] "m"  Gateway
 SG_ LiveCounter_IFC_9 : 60|4@1+ (1,0) [0|15] ""  Gateway

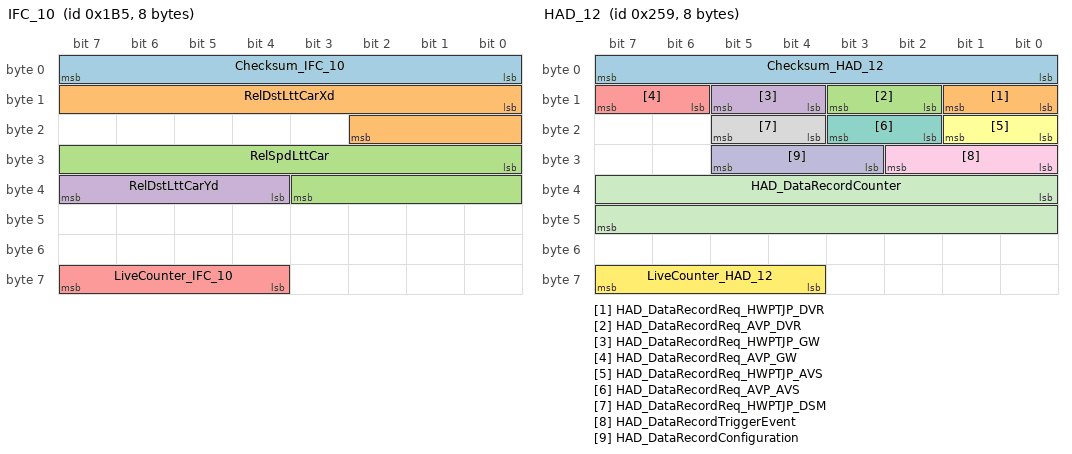
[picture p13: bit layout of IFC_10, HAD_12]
BO_ 437 IFC_10: 8 CDS2
 SG_ Checksum_IFC_10 : 0|8@1+ (1,0) [0|255] ""  Gateway
 SG_ RelDstLttCarXd : 8|11@1+ (0.1,0) [0|204.7] "m"  Gateway
 SG_ RelSpdLttCar : 24|12@1+ (0.0625,-128) [-128|127.938] "km/h"  Gateway
 SG_ RelDstLttCarYd : 36|4@1+ (0.5,0) [0|7.5] "m"  Gateway
 SG_ LiveCounter_IFC_10 : 60|4@1+ (1,0) [0|15] ""  Gateway

BO_ 601 HAD_12: 8 CDS1
 SG_ Checksum_HAD_12 : 0|8@1+ (1,0) [0|255] ""  Gateway,AVP,DSM
 SG_ HAD_DataRecordReq_HWPTJP_DVR : 8|2@1+ (1,0) [0|3] ""  Gateway
 SG_ HAD_DataRecordReq_AVP_DVR : 10|2@1+ (1,0) [0|3] ""  Gateway
 SG_ HAD_DataRecordReq_HWPTJP_GW : 12|2@1+ (1,0) [0|3] ""  Gateway
 SG_ HAD_DataRecordReq_AVP_GW : 14|2@1+ (1,0) [0|3] ""  Gateway
 SG_ HAD_DataRecordReq_HWPTJP_AVS : 16|2@1+ (1,0) [0|3] ""  AVP
 SG_ HAD_DataRecordReq_AVP_AVS : 18|2@1+ (1,0) [0|3] ""  AVP
 SG_ HAD_DataRecordReq_HWPTJP_DSM : 20|2@1+ (1,0) [0|3] ""  DSM
 SG_ HAD_DataRecordTriggerEvent : 24|3@1+ (1,0) [0|7] ""  Gateway,AVP,DSM
 SG_ HAD_DataRecordConfiguration : 27|3@1+ (1,0) [0|7] ""  Gateway
 SG_ HAD_DataRecordCounter : 32|16@1+ (1,0) [0|65535] ""  Gateway,AVP,DSM
 SG_ LiveCounter_HAD_12 : 60|4@1+ (1,0) [0|15] ""  Gateway,AVP,DSM

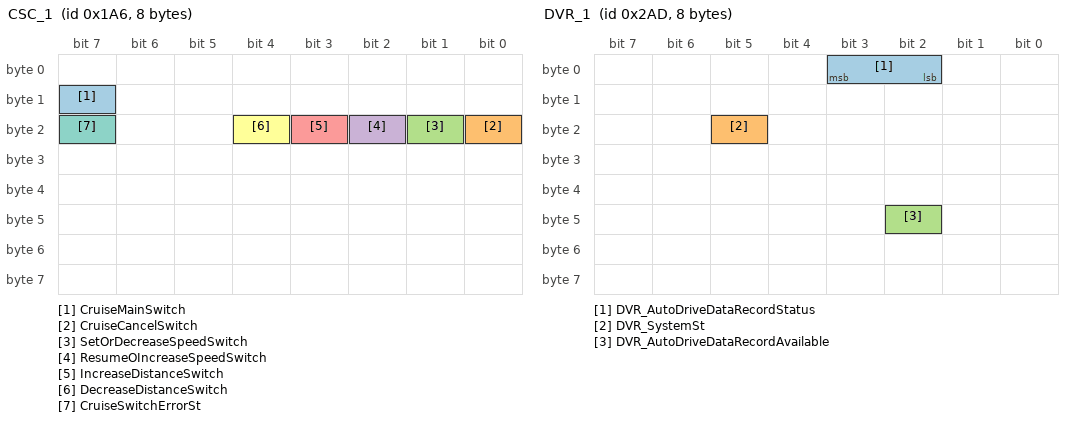
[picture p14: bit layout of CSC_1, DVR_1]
BO_ 422 CSC_1: 8 Gateway
 SG_ CruiseMainSwitch : 15|1@1+ (1,0) [0|1] ""  SVB1,CDS1,CDS2,ADV
 SG_ CruiseCancelSwitch : 16|1@1+ (1,0) [0|1] ""  SVB1,CDS1,CDS2,ADV
 SG_ SetOrDecreaseSpeedSwitch : 17|1@1+ (1,0) [0|1] ""  SVB1,CDS1,CDS2,ADV
 SG_ ResumeOIncreaseSpeedSwitch : 18|1@1+ (1,0) [0|1] ""  SVB1,CDS1,CDS2,ADV
 SG_ IncreaseDistanceSwitch : 19|1@1+ (1,0) [0|1] ""  SVB1,CDS1,CDS2,ADV
 SG_ DecreaseDistanceSwitch : 20|1@1+ (1,0) [0|1] ""  SVB1,CDS1,CDS2,ADV
 SG_ CruiseSwitchErrorSt : 23|1@1+ (1,0) [0|1] ""  SVB1,CDS1,CDS2,ADV

BO_ 520 HCU_2_9: 8 Gateway
 SG_ HCU_BatteryPackSOC : 16|8@1+ (1,0) [0|255] "%"  SVB1,CDS2,CDS1

BO_ 755 BLE_1: 8 Gateway
 SG_ BLEKeyLocation : 24|4@1+ (1,0) [0|15] ""  ADV
 SG_ Livecounter_BLE_1 : 60|4@1+ (1,0) [0|15] "pulse"  ADV

BO_ 685 DVR_1: 8 Gateway
 SG_ DVR_AutoDriveDataRecordStatus : 2|2@1+ (1,0) [0|3] "" Vector__XXX
 SG_ DVR_SystemSt : 21|1@1+ (1,0) [0|1] "" Vector__XXX
 SG_ DVR_AutoDriveDataRecordAvailable : 42|1@1+ (1,0) [0|1] "" Vector__XXX

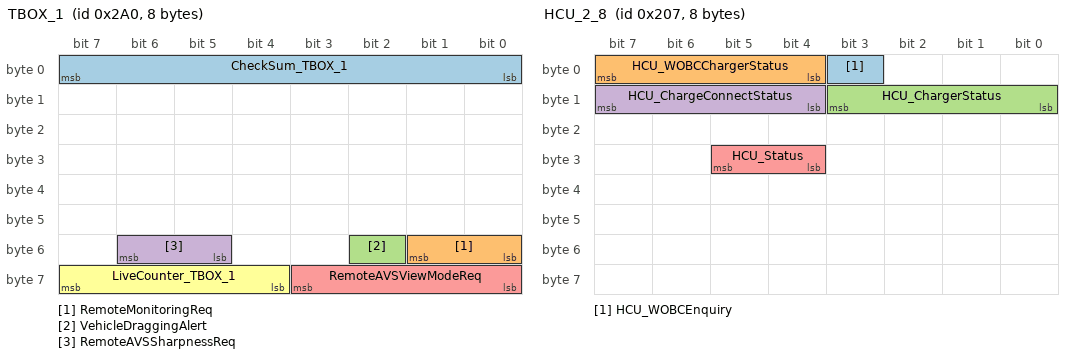
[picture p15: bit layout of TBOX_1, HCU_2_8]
BO_ 672 TBOX_1: 8 Gateway
 SG_ CheckSum_TBOX_1 : 0|8@1+ (1,0) [0|255] ""  AVP,AVM
 SG_ RemoteMonitoringReq : 48|2@1+ (1,0) [0|3] ""  AVP,AVM
 SG_ VehicleDraggingAlert : 50|1@1+ (1,0) [0|1] ""  AVP
 SG_ RemoteAVSSharpnessReq : 53|2@1+ (1,0) [0|3] ""  AVP,AVM
 SG_ RemoteAVSViewModeReq : 56|4@1+ (1,0) [0|15] ""  AVP,AVM
 SG_ LiveCounter_TBOX_1 : 60|4@1+ (1,0) [0|15] "pulse"  AVP,AVM

BO_ 519 HCU_2_8: 8 Gateway
 SG_ HCU_WOBCEnquiry : 3|1@1+ (1,0) [0|1] ""  SVB1,CDS2,CDS1,ADV
 SG_ HCU_WOBCChargerStatus : 4|4@1+ (1,0) [0|15] ""  SVB1,CDS2,CDS1,ADV,PDC
 SG_ HCU_ChargerStatus : 8|4@1+ (1,0) [0|15] ""  SVB1,CDS2,CDS1,ADV
 SG_ HCU_ChargeConnectStatus : 12|4@1+ (1,0) [0|15] ""  SVB1,CDS2,CDS1,ADV
 SG_ HCU_Status : 28|2@1+ (1,0) [0|3] ""  SVB1,CDS2,CDS1,ADV

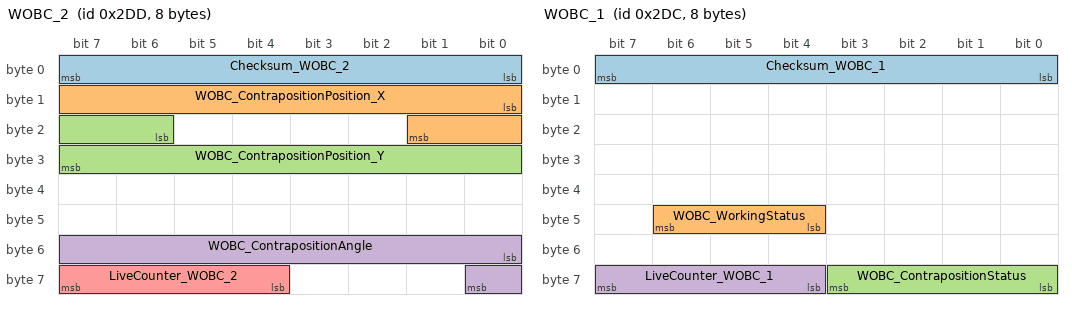
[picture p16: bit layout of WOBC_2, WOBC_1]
BO_ 733 WOBC_2: 8 Gateway
 SG_ Checksum_WOBC_2 : 0|8@1+ (1,0) [0|255] ""  ADV
 SG_ WOBC_ContrapositionPosition_X : 8|10@1+ (1,-500) [-500|523] "mm"  ADV
 SG_ WOBC_ContrapositionPosition_Y : 22|10@1+ (1,-500) [-500|523] "mm"  ADV
 SG_ WOBC_ContrapositionAngle : 48|9@1+ (1,-180) [-180|331] "°„"  ADV
 SG_ LiveCounter_WOBC_2 : 60|4@1+ (1,0) [0|15] "Pulse"  ADV

BO_ 732 WOBC_1: 8 Gateway
 SG_ Checksum_WOBC_1 : 0|8@1+ (1,0) [0|255] ""  ADV
 SG_ WOBC_WorkingStatus : 44|3@1+ (1,0) [0|7] ""  AVP,AVM
 SG_ WOBC_ContrapositionStatus : 56|4@1+ (1,0) [0|15] ""  ADV
 SG_ LiveCounter_WOBC_1 : 60|4@1+ (1,0) [0|15] "Pulse"  ADV

BO_ 566 BCM1_4: 8 Gateway
 SG_ CeremonyModeInd : 33|3@1+ (1,0) [0|7] ""  CDS2,CDS1,SVB1,ADB1,ADB2

BO_ 644 HU_3: 8 Gateway
 SG_ AccountID_IVI : 24|4@1+ (1,0) [0|15] ""  DSM
 SG_ AccountBindFaceReq : 30|2@1+ (1,0) [0|3] ""  DSM

BO_ 657 HU_14: 8 Gateway
 SG_ DisplayTheme : 24|3@1+ (1,0) [0|7] ""  ADV,AVP,AVM
 SG_ HU_ValetModeFuncSet : 60|2@1+ (1,0) [0|3] "" Vector__XXX

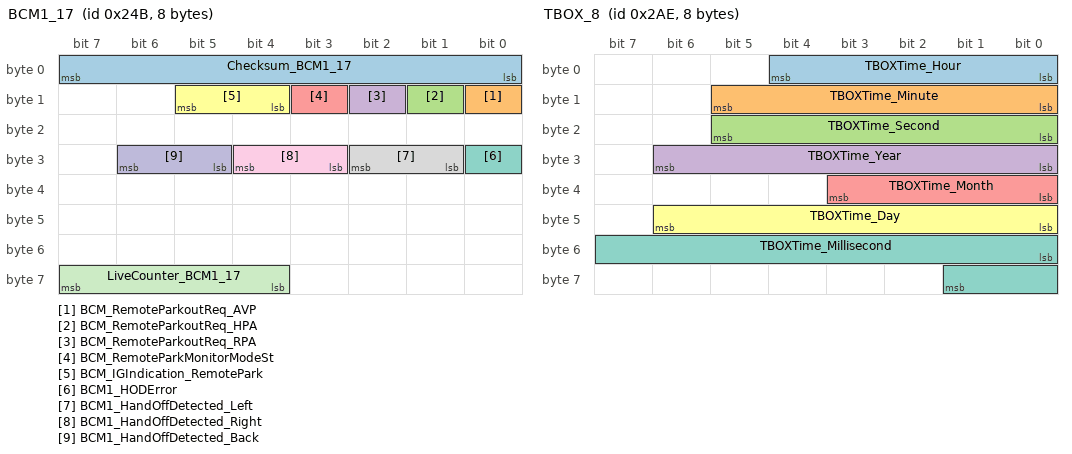
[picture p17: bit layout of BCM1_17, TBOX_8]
BO_ 587 BCM1_17: 8 Gateway
 SG_ Checksum_BCM1_17 : 0|8@1+ (1,0) [0|255] ""  CDS2,SVB1,CDS1,ADV
 SG_ BCM_RemoteParkoutReq_AVP : 8|1@1+ (1,0) [0|1] ""  CDS2,SVB1,CDS1,ADV
 SG_ BCM_RemoteParkoutReq_HPA : 9|1@1+ (1,0) [0|1] ""  CDS2,SVB1,CDS1,ADV
 SG_ BCM_RemoteParkoutReq_RPA : 10|1@1+ (1,0) [0|1] ""  CDS2,SVB1,CDS1,ADV
 SG_ BCM_RemoteParkMonitorModeSt : 11|1@1+ (1,0) [0|1] ""  CDS2,SVB1,CDS1,ADV
 SG_ BCM_IGIndication_RemotePark : 12|2@1+ (1,0) [0|3] ""  CDS2,SVB1,CDS1,ADV
 SG_ BCM1_HODError : 24|1@1+ (1,0) [0|1] ""  SVB1,CDS1,CDS2
 SG_ BCM1_HandOffDetected_Left : 25|2@1+ (1,0) [0|3] ""  SVB1,CDS1,CDS2
 SG_ BCM1_HandOffDetected_Right : 27|2@1+ (1,0) [0|3] ""  SVB1,CDS1,CDS2
 SG_ BCM1_HandOffDetected_Back : 29|2@1+ (1,0) [0|3] ""  SVB1,CDS1,CDS2
 SG_ LiveCounter_BCM1_17 : 60|4@1+ (1,0) [0|15] "Pulse"  CDS2,SVB1,CDS1,ADV

BO_ 686 TBOX_8: 8 Gateway
 SG_ TBOXTime_Hour : 0|5@1+ (1,0) [0|31] "hour"  AVP,DSM
 SG_ TBOXTime_Minute : 8|6@1+ (1,0) [0|63] "minute"  AVP,DSM
 SG_ TBOXTime_Second : 16|6@1+ (1,0) [0|63] "minute"  AVP,DSM
 SG_ TBOXTime_Year : 24|7@1+ (1,2011) [2011|2138] "year"  AVP,DSM
 SG_ TBOXTime_Month : 32|4@1+ (1,1) [1|16] "month"  AVP,DSM
 SG_ TBOXTime_Day : 40|7@1+ (1,1) [1|128] "day"  AVP,DSM
 SG_ TBOXTime_Millisecond : 48|10@1+ (1,0) [0|1023] "ms"  AVP,DSM

BO_TX_BU_ 617 : LCDA2,CDS1;
CM_ SG_ 617 Checksum_LCDAS_1 "The checksum is used to check whether the data from the CPU buffer are shifted without transmission errors to the CAN communication controller buffer and vice versa.";
CM_ SG_ 617 LCDAS_ErrorSt_LCDAS "This signal indicates the LCDA system error status.";
CM_ SG_ 617 LCDAS_WarningCmd_LCDAS_Left "The signal is warning command for BSD/LCDAS from left side. ";
CM_ SG_ 617 LCDAS_WarningCmd_RCTA_left "This signal is warning command for  RCTA from left side. ";
CM_ SG_ 617 LCDAS_WorkingSt_LCWBSD "This signal indicates LCDAS(LCW+BSD) function working status.";
CM_ SG_ 617 LCDAS_WorkingSt_RCTA "This signal indicates RCTA function working status.";
CM_ SG_ 617 LCDAS_WorkingSt_RCW "This signal indicates RCW function working status.";
CM_ SG_ 617 LCDAS_WarningCmd_DOW_FL "The signal nidicates warning command for DOW when front left side object is detected.";
CM_ SG_ 617 LCDAS_WarningCmd_DOW_RL "The signal nidicates warning command for DOW when rear left side object is detected.";
CM_ SG_ 617 LCDAS_WorkingSt_DOW "This signal indicates DOW function working status.";
CM_ SG_ 617 LCDAS_WarningCmd_RCW "The signal is warning command for RCW. ";
CM_ SG_ 617 LCDAS_Blockage_RL "The rear left sensor is blocked or not.";
CM_ SG_ 617 LCDAS__BrakeReq_RCTB "Rear corner radar request to brake the car in RCTB function.";
CM_ SG_ 617 LCDAS_WorkingSt_RCTB "This signal indicates the RCTB working status,Signal Initial=last value";
CM_ SG_ 617 LCDAS_MisAlign_status "Rear corner radar sensor status.";
CM_ SG_ 617 LiveCounter_LCDAS_1 "The Livecounter is used to check the signal consistency of the messages . If the signals are consecutive, the LiveCounter should also be sequential in the way 0, 1, 2 °≠15, 0, 1 °≠";
CM_ SG_ 620 Checksum_Fradar_1 "The checksum is used to check whether the data from the CPU buffer are shifted without transmission errors to the CAN communication controller buffer and vice versa.";
CM_ SG_ 620 Fradar_failure_status "Front radar failure status";
CM_ SG_ 620 Fradar_Blockage_status "Front radar sensor is blocked or not";
CM_ SG_ 620 Fradar_MisAlign_status "Front radar sensor status.";
CM_ SG_ 620 LiveCounter_Fradar_1 "The Livecounter is used to check the signal consistency of the messages . If the signals are consecutive, the LiveCounter should also be sequential in the way 0, 1, 2 °≠15, 0, 1 °≠";
CM_ SG_ 870 Checksum_RMradar_Obj1_4 "The checksum is used to check whether the data from the CPU buffer are shifted without transmission errors to the CAN communication controller buffer and vice versa.";
CM_ SG_ 870 RMradar_Timestamp_Obj1_1 "The time stamp";
CM_ SG_ 870 LiveCounter_RMradar_Obj1_4 "The Livecounter is used to check the signal consistency of the messages . If the signals are consecutive, the LiveCounter should also be sequential in the way 0, 1, 2 °≠15, 0, 1 °≠";
CM_ SG_ 864 Checksum_RMradar_Obj1_1 "The checksum is used to check whether the data from the CPU buffer are shifted without transmission errors to the CAN communication controller buffer and vice versa.";
CM_ SG_ 864 RMradar_Obj1_Heading "The heading angle of object.";
CM_ SG_ 864 RMradar_Obj1_YSpeedRelative "Y relative speed of object.";
CM_ SG_ 864 RMradar_Obj1_ID "The idenfication of object.";
CM_ SG_ 864 RMradar_Obj1_ValidFlag "object is valid or not.";
CM_ SG_ 864 RMradar_Obj1_MotionPattern "Motion pattern of object.";
CM_ SG_ 864 RMradar_Obj1_Type "object type";
CM_ SG_ 864 RMradar_Obj1_ExstProb "The existing probability of object.";
CM_ SG_ 864 RMradar_Obj1_Elev_Quality "The quality of object elevation class.
This signal is reserved for future,not used in E115 project,so the value will be 0x0 all the time.";
CM_ SG_ 864 RMradar_Obj1_Classify_Quality "The quality of object classification.";
CM_ SG_ 864 RMradar_Obj1_CrossFlag "The object is crossing or not.
This signal is reserved for future,not used in E115 project,so the value will be 0x0 all the time.";
CM_ SG_ 864 RMradar_Obj1_MeasureSt "The object is the real detected object or speculative object.";
CM_ SG_ 864 RMradar_Obj1_ElevClass "The object elevation class.
This signal is reserved for future,not used in E115 project,so the value will be 0x0 all the time.";
CM_ SG_ 864 LiveCounter_RMradar_Obj1_1 "The Livecounter is used to check the signal consistency of the messages . If the signals are consecutive, the LiveCounter should also be sequential in the way 0, 1, 2 °≠15, 0, 1 °≠";
CM_ SG_ 866 Checksum_RMradar_Obj1_2 "The checksum is used to check whether the data from the CPU buffer are shifted without transmission errors to the CAN communication controller buffer and vice versa.";
CM_ SG_ 866 RMradar_Obj1_XAccRelative "X relative acceleration of object.";
CM_ SG_ 866 RMradar_Obj1_YAccRelative "Y relative acceleration of object.";
CM_ SG_ 866 RMradar_Obj1_YPos_Near "nearest point Y position of object.";
CM_ SG_ 866 RMradar_Obj1_YPos_Left "Left point Y position of object.";
CM_ SG_ 866 RMradar_Obj1_YPos_Right "Right point Y position of object.";
CM_ SG_ 866 LiveCounter_RMradar_Obj1_2 "The Livecounter is used to check the signal consistency of the messages . If the signals are consecutive, the LiveCounter should also be sequential in the way 0, 1, 2 °≠15, 0, 1 °≠";
CM_ SG_ 868 Checksum_RMradar_Obj1_3 "The checksum is used to check whether the data from the CPU buffer are shifted without transmission errors to the CAN communication controller buffer and vice versa.";
CM_ SG_ 868 RMradar_Obj1_XSpeedRelative "X relative speed of object.";
CM_ SG_ 868 RMradar_Obj1_XPos_Near "nearest point X position of object.";
CM_ SG_ 868 RMradar_Obj1_XPos_Left "Left point X position of object.";
CM_ SG_ 868 RMradar_Obj1_XPos_Right "Right point X position of object.";
CM_ SG_ 868 LiveCounter_RMradar_Obj1_3 "The Livecounter is used to check the signal consistency of the messages . If the signals are consecutive, the LiveCounter should also be sequential in the way 0, 1, 2 °≠15, 0, 1 °≠";
CM_ SG_ 871 Checksum_RSradar_Obj1_4 "The checksum is used to check whether the data from the CPU buffer are shifted without transmission errors to the CAN communication controller buffer and vice versa.";
CM_ SG_ 871 RSradar_Timestamp_Obj1_1 "The time stamp";
CM_ SG_ 871 LiveCounter_RSradar_Obj1_4 "The Livecounter is used to check the signal consistency of the messages . If the signals are consecutive, the LiveCounter should also be sequential in the way 0, 1, 2 °≠15, 0, 1 °≠";
CM_ SG_ 865 Checksum_RSradar_Obj1_1 "The checksum is used to check whether the data from the CPU buffer are shifted without transmission errors to the CAN communication controller buffer and vice versa.";
CM_ SG_ 865 RSradar_Obj1_Heading "The heading angle of object.";
CM_ SG_ 865 RSradar_Obj1_YSpeedRelative "Y relative speed of object.";
CM_ SG_ 865 RSradar_Obj1_ID "The idenfication of object.";
CM_ SG_ 865 RSradar_Obj1_ValidFlag "object is valid or not.";
CM_ SG_ 865 RSradar_Obj1_MotionPattern "Motion pattern of object.";
CM_ SG_ 865 RSradar_Obj1_Type "object type";
CM_ SG_ 865 RSradar_Obj1_ExstProb "The existing probability of object.";
CM_ SG_ 865 RSradar_Obj1_Elev_Quality "The quality of object elevation class.
This signal is reserved for future,not used in E115 project,so the value will be 0x0 all the time.";
CM_ SG_ 865 RSradar_Obj1_Classify_Quality "The quality of object classification.";
CM_ SG_ 865 RSradar_Obj1_CrossFlag "The object is crossing or not.
This signal is reserved for future,not used in E115 project,so the value will be 0x0 all the time.";
CM_ SG_ 865 RSradar_Obj1_MeasureSt "The object is the real detected object or speculative object.";
CM_ SG_ 865 RSradar_Obj1_ElevClass "The object elevation class.
This signal is reserved for future,not used in E115 project,so the value will be 0x0 all the time.";
CM_ SG_ 865 LiveCounter_RSradar_Obj1_1 "The Livecounter is used to check the signal consistency of the messages . If the signals are consecutive, the LiveCounter should also be sequential in the way 0, 1, 2 °≠15, 0, 1 °≠";
CM_ SG_ 867 Checksum_RSradar_Obj1_2 "The checksum is used to check whether the data from the CPU buffer are shifted without transmission errors to the CAN communication controller buffer and vice versa.";
CM_ SG_ 867 RSradar_Obj1_XAccRelative "X relative acceleration of object.";
CM_ SG_ 867 RSradar_Obj1_YAccRelative "Y relative acceleration of object.";
CM_ SG_ 867 RSradar_Obj1_YPos_Near "nearest point Y position of object.";
CM_ SG_ 867 RSradar_Obj1_YPos_Left "Left point Y position of object.";
CM_ SG_ 867 RSradar_Obj1_YPos_Right "Right point Y position of object.";
CM_ SG_ 867 LiveCounter_RSradar_Obj1_2 "The Livecounter is used to check the signal consistency of the messages . If the signals are consecutive, the LiveCounter should also be sequential in the way 0, 1, 2 °≠15, 0, 1 °≠";
CM_ SG_ 869 Checksum_RSradar_Obj1_3 "The checksum is used to check whether the data from the CPU buffer are shifted without transmission errors to the CAN communication controller buffer and vice versa.";
CM_ SG_ 869 RSradar_Obj1_XSpeedRelative "X relative speed of object.";
CM_ SG_ 869 RSradar_Obj1_XPos_Near "nearest point X position of object.";
CM_ SG_ 869 RSradar_Obj1_XPos_Left "Left point X position of object.";
CM_ SG_ 869 RSradar_Obj1_XPos_Right "Right point X position of object.";
CM_ SG_ 869 LiveCounter_RSradar_Obj1_3 "The Livecounter is used to check the signal consistency of the messages . If the signals are consecutive, the LiveCounter should also be sequential in the way 0, 1, 2 °≠15, 0, 1 °≠";
CM_ SG_ 962 Checksum_RMradar_Free_1 "The checksum is used to check whether the data from the CPU buffer are shifted without transmission errors to the CAN communication controller buffer and vice versa.";
CM_ SG_ 962 RMradar_FSP_Sector_01_Range "Range of free space 1.";
CM_ SG_ 962 RMradar_FSP_Sector_02_Range "Range of free space 2.";
CM_ SG_ 962 RMradar_FSP_Sector_03_Range "Range of free space 3.";
CM_ SG_ 962 RMradar_FSP_Sector_04_Range "Range of free space 4.";
CM_ SG_ 962 RMradar_FSP_Sector_05_Range "Range of free space 5.";
CM_ SG_ 962 RMradar_FSP_Sector_06_Range "Range of free space 6.";
CM_ SG_ 962 LiveCounter_RMradar_Free_1 "The Livecounter is used to check the signal consistency of the messages . If the signals are consecutive, the LiveCounter should also be sequential in the way 0, 1, 2 °≠15, 0, 1 °≠";
CM_ SG_ 964 Checksum_RMradar_Free_2 "The checksum is used to check whether the data from the CPU buffer are shifted without transmission errors to the CAN communication controller buffer and vice versa.";
CM_ SG_ 964 RMradar_FSP_Sector_07_Range "Range of free space 7.";
CM_ SG_ 964 RMradar_FSP_Sector_08_Range "Range of free space 8.";
CM_ SG_ 964 RMradar_FSP_Sector_09_Range "Range of free space 9.";
CM_ SG_ 964 RMradar_FSP_Sector_10_Range "Range of free space 10.";
CM_ SG_ 964 RMradar_FSP_Sector_11_Range "Range of free space 11.";
CM_ SG_ 964 RMradar_FSP_Sector_12_Range "Range of free space 12.";
CM_ SG_ 964 LiveCounter_RMradar_Free_2 "The Livecounter is used to check the signal consistency of the messages . If the signals are consecutive, the LiveCounter should also be sequential in the way 0, 1, 2 °≠15, 0, 1 °≠";
CM_ SG_ 966 Checksum_RMradar_Free_3 "The checksum is used to check whether the data from the CPU buffer are shifted without transmission errors to the CAN communication controller buffer and vice versa.";
CM_ SG_ 966 RMradar_FSP_Sector_13_Range "Range of free space 13.";
CM_ SG_ 966 RMradar_FSP_Sector_14_Range "Range of free space 14.";
CM_ SG_ 966 RMradar_FSP_Sector_15_Range "Range of free space 15.";
CM_ SG_ 966 RMradar_FSP_Sector_16_Range "Range of free space 16.";
CM_ SG_ 966 RMradar_FSP_Sector_17_Range "Range of free space 17.";
CM_ SG_ 966 RMradar_FSP_Sector_18_Range "Range of free space 18.";
CM_ SG_ 966 LiveCounter_RMradar_Free_3 "The Livecounter is used to check the signal consistency of the messages . If the signals are consecutive, the LiveCounter should also be sequential in the way 0, 1, 2 °≠15, 0, 1 °≠";
CM_ SG_ 968 Checksum_RMradar_Free_4 "The checksum is used to check whether the data from the CPU buffer are shifted without transmission errors to the CAN communication controller buffer and vice versa.";
CM_ SG_ 968 RMradar_FSP_Sector_19_Range "Range of free space 19.";
CM_ SG_ 968 RMradar_FSP_Sector_20_Range "Range of free space 20.";
CM_ SG_ 968 RMradar_FSP_Sector_21_Range "Range of free space 21.";
CM_ SG_ 968 RMradar_FSP_Sector_22_Range "Range of free space 22.";
CM_ SG_ 968 RMradar_FSP_Sector_23_Range "Range of free space 23.";
CM_ SG_ 968 RMradar_FSP_Sector_24_Range "Range of free space 24.";
CM_ SG_ 968 LiveCounter_RMradar_Free_4 "The Livecounter is used to check the signal consistency of the messages . If the signals are consecutive, the LiveCounter should also be sequential in the way 0, 1, 2 °≠15, 0, 1 °≠";
CM_ SG_ 970 Checksum_RMradar_Free_5 "The checksum is used to check whether the data from the CPU buffer are shifted without transmission errors to the CAN communication controller buffer and vice versa.";
CM_ SG_ 970 RMradar_FSP_Sector_25_Range "Range of free space 25.";
CM_ SG_ 970 RMradar_FSP_Sector_26_Range "Range of free space 26.";
CM_ SG_ 970 RMradar_FSP_Sector_27_Range "Range of free space 27.";
CM_ SG_ 970 RMradar_FSP_Sector_28_Range "Range of free space 28.";
CM_ SG_ 970 RMradar_FSP_Sector_29_Range "Range of free space 29.";
CM_ SG_ 970 RMradar_FSP_Sector_30_Range "Range of free space 30.";
CM_ SG_ 970 LiveCounter_RMradar_Free_5 "The Livecounter is used to check the signal consistency of the messages . If the signals are consecutive, the LiveCounter should also be sequential in the way 0, 1, 2 °≠15, 0, 1 °≠";
CM_ SG_ 972 Checksum_RMradar_Free_6 "The checksum is used to check whether the data from the CPU buffer are shifted without transmission errors to the CAN communication controller buffer and vice versa.";
CM_ SG_ 972 RMradar_FSP_Sector_31_Range "Range of free space 31.";
CM_ SG_ 972 RMradar_FSP_Sector_32_Range "Range of free space 32.";
CM_ SG_ 972 RMradar_FSP_Sector_33_Range "Range of free space 33.";
CM_ SG_ 972 RMradar_FSP_Sector_34_Range "Range of free space 34.";
CM_ SG_ 972 RMradar_FSP_Sector_35_Range "Range of free space 35.";
CM_ SG_ 972 LiveCounter_RMradar_Free_6 "The Livecounter is used to check the signal consistency of the messages . If the signals are consecutive, the LiveCounter should also be sequential in the way 0, 1, 2 °≠15, 0, 1 °≠";
CM_ SG_ 963 Checksum_RSradar_Free_1 "The checksum is used to check whether the data from the CPU buffer are shifted without transmission errors to the CAN communication controller buffer and vice versa.";
CM_ SG_ 963 RSradar_FSP_Sector_01_Range "Range of free space 1.";
CM_ SG_ 963 RSradar_FSP_Sector_02_Range "Range of free space 2.";
CM_ SG_ 963 RSradar_FSP_Sector_03_Range "Range of free space 3.";
CM_ SG_ 963 RSradar_FSP_Sector_04_Range "Range of free space 4.";
CM_ SG_ 963 RSradar_FSP_Sector_05_Range "Range of free space 5.";
CM_ SG_ 963 RSradar_FSP_Sector_06_Range "Range of free space 6.";
CM_ SG_ 963 LiveCounter_RSradar_Free_1 "The Livecounter is used to check the signal consistency of the messages . If the signals are consecutive, the LiveCounter should also be sequential in the way 0, 1, 2 °≠15, 0, 1 °≠";
CM_ SG_ 965 Checksum_RSradar_Free_2 "The checksum is used to check whether the data from the CPU buffer are shifted without transmission errors to the CAN communication controller buffer and vice versa.";
CM_ SG_ 965 RSradar_FSP_Sector_07_Range "Range of free space 7.";
CM_ SG_ 965 RSradar_FSP_Sector_08_Range "Range of free space 8.";
CM_ SG_ 965 RSradar_FSP_Sector_09_Range "Range of free space 9.";
CM_ SG_ 965 RSradar_FSP_Sector_10_Range "Range of free space 10.";
CM_ SG_ 965 RSradar_FSP_Sector_11_Range "Range of free space 11.";
CM_ SG_ 965 RSradar_FSP_Sector_12_Range "Range of free space 12.";
CM_ SG_ 965 LiveCounter_RSradar_Free_2 "The Livecounter is used to check the signal consistency of the messages . If the signals are consecutive, the LiveCounter should also be sequential in the way 0, 1, 2 °≠15, 0, 1 °≠";
CM_ SG_ 975 Checksum_RSradar_Free_3 "The checksum is used to check whether the data from the CPU buffer are shifted without transmission errors to the CAN communication controller buffer and vice versa.";
CM_ SG_ 975 RSradar_FSP_Sector_13_Range "Range of free space 13.";
CM_ SG_ 975 RSradar_FSP_Sector_14_Range "Range of free space 14.";
CM_ SG_ 975 RSradar_FSP_Sector_15_Range "Range of free space 15.";
CM_ SG_ 975 RSradar_FSP_Sector_16_Range "Range of free space 16.";
CM_ SG_ 975 RSradar_FSP_Sector_17_Range "Range of free space 17.";
CM_ SG_ 975 RSradar_FSP_Sector_18_Range "Range of free space 18.";
CM_ SG_ 975 LiveCounter_RSradar_Free_3 "The Livecounter is used to check the signal consistency of the messages . If the signals are consecutive, the LiveCounter should also be sequential in the way 0, 1, 2 °≠15, 0, 1 °≠";
CM_ SG_ 969 Checksum_RSradar_Free_4 "The checksum is used to check whether the data from the CPU buffer are shifted without transmission errors to the CAN communication controller buffer and vice versa.";
CM_ SG_ 969 RSradar_FSP_Sector_19_Range "Range of free space 19.";
CM_ SG_ 969 RSradar_FSP_Sector_20_Range "Range of free space 20.";
CM_ SG_ 969 RSradar_FSP_Sector_21_Range "Range of free space 21.";
CM_ SG_ 969 RSradar_FSP_Sector_22_Range "Range of free space 22.";
CM_ SG_ 969 RSradar_FSP_Sector_23_Range "Range of free space 23.";
CM_ SG_ 969 RSradar_FSP_Sector_24_Range "Range of free space 24.";
CM_ SG_ 969 LiveCounter_RSradar_Free_4 "The Livecounter is used to check the signal consistency of the messages . If the signals are consecutive, the LiveCounter should also be sequential in the way 0, 1, 2 °≠15, 0, 1 °≠";
CM_ SG_ 971 Checksum_RSradar_Free_5 "The checksum is used to check whether the data from the CPU buffer are shifted without transmission errors to the CAN communication controller buffer and vice versa.";
CM_ SG_ 971 RSradar_FSP_Sector_25_Range "Range of free space 25.";
CM_ SG_ 971 RSradar_FSP_Sector_26_Range "Range of free space 26.";
CM_ SG_ 971 RSradar_FSP_Sector_27_Range "Range of free space 27.";
CM_ SG_ 971 RSradar_FSP_Sector_28_Range "Range of free space 28.";
CM_ SG_ 971 RSradar_FSP_Sector_29_Range "Range of free space 29.";
CM_ SG_ 971 RSradar_FSP_Sector_30_Range "Range of free space 30.";
CM_ SG_ 971 LiveCounter_RSradar_Free_5 "The Livecounter is used to check the signal consistency of the messages . If the signals are consecutive, the LiveCounter should also be sequential in the way 0, 1, 2 °≠15, 0, 1 °≠";
CM_ SG_ 973 Checksum_RSradar_Free_6 "The checksum is used to check whether the data from the CPU buffer are shifted without transmission errors to the CAN communication controller buffer and vice versa.";
CM_ SG_ 973 RSradar_FSP_Sector_31_Range "Range of free space 31.";
CM_ SG_ 973 RSradar_FSP_Sector_32_Range "Range of free space 32.";
CM_ SG_ 973 RSradar_FSP_Sector_33_Range "Range of free space 33.";
CM_ SG_ 973 RSradar_FSP_Sector_34_Range "Range of free space 34.";
CM_ SG_ 973 RSradar_FSP_Sector_35_Range "Range of free space 35.";
CM_ SG_ 973 LiveCounter_RSradar_Free_6 "The Livecounter is used to check the signal consistency of the messages . If the signals are consecutive, the LiveCounter should also be sequential in the way 0, 1, 2 °≠15, 0, 1 °≠";
CM_ SG_ 602 HAD_SetMaxVehcleSpeedFunSt "Th status of maximum vehcle speed setting function,Signal Initial=last value";
CM_ SG_ 602 HAD_MaxVehcleSpeedSetted "The setted maximum autodriving speed,Signal Initial=last value";
CM_ SG_ 602 HAD_ChangeLaneAuto_Feedback "The feedback of changing the lane automatically.";
CM_ SG_ 602 HAD_RampSt_FR "If there is ramp on the right front ahead";
CM_ SG_ 602 HAD_RampSt_FL "If there is ramp on the left front ahead";
CM_ SG_ 602 HAD_GeoFenceAway "If the car will drive away the Geographical fence";
CM_ SG_ 602 HAD_TunnelSt_Ahead "If there is a tunnel ahead";
CM_ SG_ 602 HAD_TollGateSt_Ahead "If there is a toll gate  ahead";
CM_ SG_ 602 HAD_RoadEnd_Ahead "If the road is end ahead.";
CM_ SG_ 602 HAD_LaneEnd_Ahead "If the ego lane is end ahead.";
CM_ SG_ 602 HAD_Merge_Ahead "If there is a car merging point ahead ";
CM_ SG_ 602 HAD_AccidentsPotencial_Ahead "If there is a accidents potencial road section ahead";
CM_ SG_ 602 HAD_RoadWork_Ahead "If there has road work ahead";
CM_ SG_ 602 HAD_LaneLineFade_Ahead "The lane line is fading ahead";
CM_ SG_ 602 HAD_RockfallPotencial_Ahead "If there is a rockfall potencial road section ahead";
CM_ SG_ 602 HAD_LaneLineCaptured_LL "If the left-left lane linde is captured or not";
CM_ SG_ 602 HAD_LaneLineCaptured_L "If the left lane linde is captured or not";
CM_ SG_ 602 HAD_LaneLineCaptured_RR "If the right-right lane linde is captured or not";
CM_ SG_ 602 HAD_LaneLineCaptured_R "If the right lane linde is captured or not";
CM_ SG_ 602 HAD_LaneLineType_LL "The left-left lane line type";
CM_ SG_ 602 HAD_LaneLineType_L "The left lane line type";
CM_ SG_ 602 HAD_LaneLineType_RR "The right-right lane line type";
CM_ SG_ 602 HAD_LaneLineType_R "The right lane line type";
CM_ SG_ 602 HAD_VehcleStatus_Ego "The ego car moving status.";
CM_ SG_ 602 LiveCounter_HAD_7 "The Livecounter is used to check the signal consistency of the messages . If the signals are consecutive, the LiveCounter should also be sequential in the way 0, 1, 2 °≠15, 0, 1 °≠";
CM_ SG_ 603 HAD_VehcleStatus_Front "The front vehcle status";
CM_ SG_ 603 HAD_VehcleStatus_Left "The left vehcle status";
CM_ SG_ 603 HAD_VehcleStatus_Right "The right vehcle status";
CM_ SG_ 603 HAD_VehcleStatus_FR "The front right vehcle status";
CM_ SG_ 603 HAD_VehcleStatus_FL "The front left vehcle status";
CM_ SG_ 603 HAD_VehcleStatus_RR "The rear right vehcle status";
CM_ SG_ 603 HAD_VRU_FL "The front left VRU status";
CM_ SG_ 603 HAD_VehcleStatus_RL "The rear left vehcle status";
CM_ SG_ 603 HAD_LateralPosition_FrontVehcle "The front vehcle position";
CM_ SG_ 603 HAD_VRU_FR "The front right VRU status";
CM_ SG_ 603 HAD_LongitudinalPosition_FrontVe "The front vehcle longitudinal position(longitudinal ditance with ego vehcle)";
CM_ SG_ 603 HAD_LateralPosition_FRVehcle "The front right vehcle lateral position";
CM_ SG_ 603 HAD_VRU_Front "The front VRU status";
CM_ SG_ 603 HAD_LateralPosition_FLVehcle "The front left vehcle lateral position";
CM_ SG_ 603 HAD_LateralPosition_LeftVehcle "The left vehcle lateral position";
CM_ SG_ 603 HAD_LateralPosition_RightVehcle "The right vehcle lateral position";
CM_ SG_ 603 LiveCounter_HAD_8 "The Livecounter is used to check the signal consistency of the messages . If the signals are consecutive, the LiveCounter should also be sequential in the way 0, 1, 2 °≠15, 0, 1 °≠";
CM_ SG_ 606 HAD_LateralPosition_RLVehcle "The rear left vehcle lateral position";
CM_ SG_ 606 HAD_LateralPosition_RRVehcle "The rear right vehcle lateral position";
CM_ SG_ 606 HAD_FrontVehcle_CIPV "The front vehcle is CIPV or not";
CM_ SG_ 606 HAD_FRVehcle_CIPV "The front right vehcle is CIPV or not";
CM_ SG_ 606 HAD_FLVehcle_CIPV "The front left vehcle is CIPV or not";
CM_ SG_ 606 HAD_LeftVehcle_CIPV "The left vehcle is CIPV or not";
CM_ SG_ 606 HAD_RightVehcle_CIPV "The right vehcle is CIPV or not";
CM_ SG_ 606 HAD_RRVehcle_CIPV "The rear right vehcle is CIPV or not";
CM_ SG_ 606 HAD_RLVehcle_CIPV "The rear left vehcle is CIPV or not";
CM_ SG_ 606 HAD_ErrorSt "The HAD controller is error or not";
CM_ SG_ 606 HAD_BrakeLightCtrlCmd "The signal indicates the brake light control command from HWP or TJP.";
CM_ SG_ 606 HAD_LaneShap_Ego "The lane shap of ego lane";
CM_ SG_ 606 HAD_LaneShap_Left "The lane shap of left lane";
CM_ SG_ 606 HAD_LowBeamReq "This signal indicates the request of low beam from HWP or TJP.";
CM_ SG_ 606 HAD_LaneShap_Right "The lane shap of right lane";
CM_ SG_ 606 HAD_LaneWidth_Ego "The lanewidth of ego lane";
CM_ SG_ 606 HAD_HighBeamReq "This signal indicates the request of high beam from HWP or TJP.";
CM_ SG_ 606 HAD_LaneWidth_Left "The lanewidth of left lane";
CM_ SG_ 606 HAD_LaneWidth_Right "The lanewidth of right lane";
CM_ SG_ 606 HAD_AbnormalRoadAttention "remind driver to watch the road ahead while auto pilot.";
CM_ SG_ 606 HAD_KeepHandsOnTip "remind driver to take hands on the steering wheel on some condition while auto pilot.";
CM_ SG_ 606 HAD_ChangeLaneFunctionForbidden "remind driver that the lane change funtion is inhibit now.";
CM_ SG_ 606 HAD_ChangeLaneAuto_ConfirmFuncSt "The function status of HAD request driver confirm change the lane automatically or not";
CM_ SG_ 606 HAD_DriverViewStatus_L3 "This signal indicates the driver view status in L3 auto driving mode.";
CM_ SG_ 606 HAD_DriverHandsOnTip_L3 "This signal indicates the driver holding the steering wheel or not";
CM_ SG_ 606 HAD_AccelerationPedalApplied "This signal indicates the acceleration pedal is applied by driver or not";
CM_ SG_ 606 LiveCounter_HAD_9 "The Livecounter is used to check the signal consistency of the messages . If the signals are consecutive, the LiveCounter should also be sequential in the way 0, 1, 2 °≠15, 0, 1 °≠";
CM_ SG_ 667 HU_HWPTJPReq "Turn HWP/TJP function on or off by IVI";
CM_ SG_ 667 HU_AVPFunctionReq "Turn AVP function on or off by IVI";
CM_ SG_ 667 HU_ChangeLaneAuto_ConfirmFuncReq "The function that HAD request driver confirm change lane oe not can be turned on or off by IVI";
CM_ SG_ 667 FCWModeSet "This signal is used to modify the configuration of FCW function.";
CM_ SG_ 667 HU_ChangeLaneManualFuncReq "The function of driver change the lane manually by operate the turning switch can be turned or off by IVI";
CM_ SG_ 667 HU_ChangeLaneAutoFuncReq "The function that HAD can change the lane automatically can be turned on or off by IVI";
CM_ SG_ 667 HU_SetMaxVehcleSpeedFuncReq "The function that driver can set the limited maximum autodriving speed can be turned on or off by IVI";
CM_ SG_ 667 HU_PDCBuzzerReq "This signal is used to request PDC buzzer on or off.";
CM_ SG_ 667 HU_MaxVehcleSpeed_Set "The setted maximum autodriving speed";
CM_ SG_ 667 HU_LCDAFunctionReq "This signal is used to request LCW&BSD function on or off.";
CM_ SG_ 667 HU_RCWFunctionReq "This signal is used to request RCW function on or off.";
CM_ SG_ 667 HU_FCTAFunctionReq "This signal is used to request FCTA function on or off.";
CM_ SG_ 667 HU_RCTAFunctionReq "This signal is used to request RCTA function on or off.";
CM_ SG_ 667 HU_RCTABuzzerWarningFunReq "This signal is used to request RCTA  buzzer warning function on or off";
CM_ SG_ 667 HU_DOWFunctionReq "This signal is used to request DOW function on or off.";
CM_ SG_ 667 HU_FCTBFunctionReq "This signal is used to request BSD function on or off.";
CM_ SG_ 667 HU_RCTBFunctionReq "This signal is used to request BSD function on or off.";
CM_ SG_ 667 HU_DestinationtipReq "Turn HWP/TJP Destinatong tip function on or off by IVI";
CM_ SG_ 667 HU_AEBSensitivitySet "This signal is used for AEB sensitivity Setting.";
CM_ SG_ 667 Livecounter_HU_10 "The Livecounter is used to check the signal consistency of the messages . If the signals are consecutive, the LiveCounter should also be sequential in the way 0, 1, 2 °≠15, 0, 1 °≠";
CM_ SG_ 576 PositionLightSt_RL "The signal indicates the status of rear left position light.";
CM_ SG_ 576 PositionLightSt_RR "The signal indicates the status of rear right position light.";
CM_ SG_ 576 FogLightSt_Rear "The signal is indicates the status of rear fog indicator.";
CM_ SG_ 576 FogLightSt_RL "The signal is indicates the status of rear left fog indicator.";
CM_ SG_ 576 FogLightSt_RR "This signal shows rear fog light light fault status. ";
CM_ SG_ 576 FoglightFaultSt_Rear "This signal shows rear fog light light fault status. ";
CM_ SG_ 576 ReverseLightSt "indicates the reverse light status";
CM_ SG_ 576 ReverseLightFaultSt "This signal shows reverse light fault status. ";
CM_ SG_ 576 LicenseLightSt "indicates the License light status";
CM_ SG_ 576 LicenseLightFaultSt "This signal shows licenselight fault status. ";
CM_ SG_ 576 BrakeLightFaultSt_RL "The signal indicates the fault status of rear left brake light.";
CM_ SG_ 576 BrakeLightFaultSt_RR "The signal indicates the fault status of rear right brake light.";
CM_ SG_ 576 TurnLightFaultSt_RL "The signal indicates the fault status of rear left turn light.";
CM_ SG_ 576 TurnLightFaultSt_RR "The signal indicates the fault status of rear right turn light.";
CM_ SG_ 576 WashSysSt_Rear "This signal shows rear wash system status. ";
CM_ SG_ 576 RearWindowHeatingStatus "Indicates the rear window heating status";
CM_ SG_ 576 WiperSt_Rear "This signal shows rear wiper status. ";
CM_ SG_ 576 PositionLightFaultSt_Rear "This signal shows rear position light light fault status. ";
CM_ SG_ 576 BrakeLightSt_RL "indicates the rear left brake light status";
CM_ SG_ 576 BrakeLightSt_RR "indicates the rear right brake light status";
CM_ SG_ 737 FCP_AVSFunctionReq "This signal is used to request AVS function on or off.";
CM_ SG_ 737 FCP_PDCFunctionReq "This signal is used to request PDC function on or off.";
CM_ SG_ 737 FCP_APAFunctionReq "This signal is used to request APA function on or off.";
CM_ SG_ 737 FCP_AVPFunctionReq "This signal is used to request AVP function on or off.";
CM_ SG_ 434 Checksum_IFC_7 "The checksum is used to check whether the data from the CPU buffer are shifted without transmission errors to the CAN communication controller buffer and vice versa.";
CM_ SG_ 434 RelDstFrtCarXb "This signal  indicates the relative  longitudinal distance of front car.";
CM_ SG_ 434 RelDstFrtCarYb "This signal  indicates the relative lateral distance of front car.";
CM_ SG_ 434 RelSpdFrtCar "This signal Indicates the relative speed of front car.";
CM_ SG_ 434 HeiFrtCar "This signal  indicates the height of front car.";
CM_ SG_ 434 LaneChangeSt "This signal indicates the lane change status.";
CM_ SG_ 434 TargetVehicleChangeSt "This signal indicates the front target vehicle change status.";
CM_ SG_ 434 TypeFrtCar "This signal indicates the type of front car.";
CM_ SG_ 434 LiveCounter_IFC_7 "The Livecounter is used to check the signal consistency of the messages . If the signals are consecutive, the LiveCounter should also be sequential in the way 0, 1, 2 °≠15, 0, 1 °≠";
CM_ SG_ 435 Checksum_IFC_8 "The checksum is used to check whether the data from the CPU buffer are shifted without transmission errors to the CAN communication controller buffer and vice versa.";
CM_ SG_ 435 RelDstFLCarXb "This signal  indicates the relative  longitudinal distance of front left car.";
CM_ SG_ 435 RelSpdFLCar "This signal Indicates the relative speed of front left car.";
CM_ SG_ 435 RelDstFLCarYb "This signal  indicates the relative lateral distance of front left car.";
CM_ SG_ 435 LiveCounter_IFC_8 "The Livecounter is used to check the signal consistency of the messages . If the signals are consecutive, the LiveCounter should also be sequential in the way 0, 1, 2 °≠15, 0, 1 °≠";
CM_ SG_ 436 Checksum_IFC_9 "The checksum is used to check whether the data from the CPU buffer are shifted without transmission errors to the CAN communication controller buffer and vice versa.";
CM_ SG_ 436 RelDstFRCarXb "This signal  indicates the relative  longitudinal distance of front right car.";
CM_ SG_ 436 RelSpdFRCar "This signal Indicates the relative speed of front left car.";
CM_ SG_ 436 RelDstFRCarYb "This signal  indicates the relative lateral distance of front left car.";
CM_ SG_ 436 LiveCounter_IFC_9 "The Livecounter is used to check the signal consistency of the messages . If the signals are consecutive, the LiveCounter should also be sequential in the way 0, 1, 2 °≠15, 0, 1 °≠";
CM_ SG_ 437 Checksum_IFC_10 "The checksum is used to check whether the data from the CPU buffer are shifted without transmission errors to the CAN communication controller buffer and vice versa.";
CM_ SG_ 437 RelDstLttCarXd "This signal  indicates the relative  longitudinal distance of front latency car.";
CM_ SG_ 437 RelSpdLttCar "This signal Indicates the relative speed of front latency car.";
CM_ SG_ 437 RelDstLttCarYd "This signal  indicates the relative lateral distance of front latency car.";
CM_ SG_ 437 LiveCounter_IFC_10 "The Livecounter is used to check the signal consistency of the messages . If the signals are consecutive, the LiveCounter should also be sequential in the way 0, 1, 2 °≠15, 0, 1 °≠";
CM_ SG_ 601 Checksum_HAD_12 "The checksum is used to check whether the data from the CPU buffer are shifted without transmission errors to the CAN communication controller buffer and vice versa.";
CM_ SG_ 601 HAD_DataRecordReq_HWPTJP_DVR "HAD request DVR to record relative data on HWP/TJP condition";
CM_ SG_ 601 HAD_DataRecordReq_AVP_DVR "HAD request DVR to record relative data on AVP condition.";
CM_ SG_ 601 HAD_DataRecordReq_HWPTJP_GW "HAD request GW to record relative data on HWP/TJP condition";
CM_ SG_ 601 HAD_DataRecordReq_AVP_GW "HAD request GW to record relative data on AVP condition.";
CM_ SG_ 601 HAD_DataRecordReq_HWPTJP_AVS "HAD request AVS to record relative data on HWP/TJP condition";
CM_ SG_ 601 HAD_DataRecordReq_AVP_AVS "HAD request AVS to record relative data on AVP condition.";
CM_ SG_ 601 HAD_DataRecordReq_HWPTJP_DSM "HAD request DSM to record relative data on HWP/TJP condition";
CM_ SG_ 601 HAD_DataRecordTriggerEvent "The trriger event of recording data.";
CM_ SG_ 601 HAD_DataRecordConfiguration "Data Record Configuration";
CM_ SG_ 601 HAD_DataRecordCounter "Data Record Counter";
CM_ SG_ 601 LiveCounter_HAD_12 "The Livecounter is used to check the signal consistency of the messages . If the signals are consecutive, the LiveCounter should also be sequential in the way 0, 1, 2 °≠15, 0, 1 °≠";
CM_ SG_ 422 CruiseMainSwitch "The signal indicates if the  ON/OFF cruise control switch is actived or not.";
CM_ SG_ 422 CruiseCancelSwitch "The signal indicates if the cancel cruise control switch is actived or not";
CM_ SG_ 422 SetOrDecreaseSpeedSwitch "The signal indicates if the set or decrease speed switch is actived or not.";
CM_ SG_ 422 ResumeOIncreaseSpeedSwitch "The signal indicates if the resume or increase speed switch is actived or not";
CM_ SG_ 422 IncreaseDistanceSwitch "The signal indicates if  increase distance switch is actived or not";
CM_ SG_ 422 DecreaseDistanceSwitch "The signal indicates if decrease distance switch is actived or not";
CM_ SG_ 422 CruiseSwitchErrorSt "This signal indicates the cruise switch error status.";
CM_ SG_ 520 HCU_BatteryPackSOC "Battery SOC(signal resolution is not as BMS_BatteryPackSOC in EVCAN)";
CM_ SG_ 755 BLEKeyLocation "This signal indicates the location of BLE phone.";
CM_ SG_ 755 Livecounter_BLE_1 "The Livecounter is used to check the signal consistency of the messages . If the signals are consecutive, the LiveCounter should also be sequential in the way 0, 1, 2 °≠15, 0, 1 °≠";
CM_ SG_ 685 DVR_AutoDriveDataRecordStatus "DVR automotive drive data recode status";
CM_ SG_ 685 DVR_SystemSt "Indicates the DVR is in fault status or not";
CM_ SG_ 685 DVR_AutoDriveDataRecordAvailable "Indicates DVR automotive drive data record available or not";
CM_ SG_ 672 CheckSum_TBOX_1 "The checksum is used to check whether the data from the CPU buffer are shifted without transmission errors to the CAN communication controller buffer and vice versa.";
CM_ SG_ 672 RemoteMonitoringReq "This signal indicates the remote monitoring request.";
CM_ SG_ 672 VehicleDraggingAlert "This signal indicates the vehicle dragging alert.";
CM_ SG_ 672 RemoteAVSSharpnessReq "This signal indicates the remote AVM sharpness request.";
CM_ SG_ 672 RemoteAVSViewModeReq "The signals indicates the view mode changing request by remote monitoring.";
CM_ SG_ 672 LiveCounter_TBOX_1 "The Livecounter is used to check the signal consistency of the messages . If the signals are consecutive, the LiveCounter should also be sequential in the way 0, 1, 2 °≠15, 0, 1 °≠";
CM_ SG_ 519 HCU_WOBCEnquiry "This signal indicates HCU  enquire driver if start wireless on borad charging when WOBC mode in enquiry mode.";
CM_ SG_ 519 HCU_WOBCChargerStatus "This signal indicate the wirless on board charging status.";
CM_ SG_ 519 HCU_ChargerStatus "HCU considers signal BMS_ChargeStatus and BMS_ChargeStationStatus from BMS and signal Charger_Status from Charger together. This signal is not a routing signal.";
CM_ SG_ 519 HCU_ChargeConnectStatus "The total of Charge Connect Status";
CM_ SG_ 519 HCU_Status "This signal indicates HCU  Status";
CM_ SG_ 733 WOBC_ContrapositionPosition_X "This signal indicates the contraposiiton X position relative to the vehicle.";
CM_ SG_ 733 WOBC_ContrapositionPosition_Y "This signal indicates the contraposiiton Y position relative to the vehicle.";
CM_ SG_ 733 WOBC_ContrapositionAngle "This signal indicates the contraposiiton angle relative to the vehicle.";
CM_ SG_ 732 WOBC_WorkingStatus "WOBC  working Status";
CM_ SG_ 732 WOBC_ContrapositionStatus "WOBC Contraposition status";
CM_ SG_ 566 CeremonyModeInd "This signal indicates setting result of the ceremony mode.";
CM_ SG_ 644 AccountID_IVI "This signal indicates the account ID.
0:Initial/No account identified 1~14:Account ID 15:Invalid value";
CM_ SG_ 644 AccountBindFaceReq "This signal is used to bind or unbind the face to user account.";
CM_ SG_ 657 DisplayTheme "This signal indicates the display theme of the IVI.";
CM_ SG_ 657 HU_ValetModeFuncSet "This signal indicates the Valet mode function setting.";
CM_ SG_ 587 BCM_RemoteParkoutReq_AVP "AVP remote park out request";
CM_ SG_ 587 BCM_RemoteParkoutReq_HPA "HPA remote park out request";
CM_ SG_ 587 BCM_RemoteParkoutReq_RPA "RPA park out request";
CM_ SG_ 587 BCM_RemoteParkMonitorModeSt "This signal indicates BCM is in remote AVP/HPA.RPA mode or not";
CM_ SG_ 587 BCM_IGIndication_RemotePark "This signal indicates the ignition status when BCM receive the remote park request from TSP or BLE.";
CM_ SG_ 587 BCM1_HODError "Indicates the error status of HOD function.";
CM_ SG_ 587 BCM1_HandOffDetected_Left "Indicates the detected hand off status of the steering left side area.";
CM_ SG_ 587 BCM1_HandOffDetected_Right "Indicates the detected hand off status of the steering right side area.";
CM_ SG_ 587 BCM1_HandOffDetected_Back "Indicates the detected hand off status of the steering back side area.";
CM_ SG_ 587 LiveCounter_BCM1_17 "The Livecounter is used to check the signal consistency of the messages . If the signals are consecutive, the LiveCounter should also be sequential in the way 0, 1, 2 °≠15, 0, 1 °≠";
CM_ SG_ 686 TBOXTime_Hour "Indicates the TBOX system hour sent by TBOX";
CM_ SG_ 686 TBOXTime_Minute "Indicates the TBOX system minute  sent by TBOX ";
CM_ SG_ 686 TBOXTime_Second "Indicates the TBOX system second sent by TBOX ";
CM_ SG_ 686 TBOXTime_Year "Indicates the TBOX system year sent by TBOX ";
CM_ SG_ 686 TBOXTime_Month "Indicates the TBOX system month sent by TBOX ";
CM_ SG_ 686 TBOXTime_Day "Indicates the TBOX system day sent by TBOX ";
CM_ SG_ 686 TBOXTime_Millisecond "Indicates the TBOX system day sent by TBOX ";
BA_DEF_ SG_  "GenSigStartValue" INT 0 1000000000;
BA_DEF_ BO_  "GenMsgILSupport" ENUM  "No","Yes";
BA_DEF_ BO_  "CanTpSTmin" INT 0 0;
BA_DEF_ BO_  "CanTpFcFrameId" HEX 0 2147483647;
BA_DEF_ SG_  "GenSigSendType" ENUM  "Cyclic","OnWrite","OnWriteWithRepetition","OnChange","OnChangeWithRepetition","IfActive","IfActiveWithRepetition","NoSigSendType";
BA_DEF_ BO_  "GenMsgCycleTime" INT 0 50000;
BA_DEF_ BO_  "GenMsgSendType" ENUM  "Cyclic","not_used","not_used","not_used","not_used","Cyclic","not_used","IfActive","NoMsgSendType","Spontaneous","CyclicAndSpontaneous","NoMsgSendType";
BA_DEF_ SG_  "GenSigInvalidValue" INT 0 0;
BA_DEF_ SG_  "GenSigStartRemark" STRING ;
BA_DEF_ SG_  "GenSigInvalidRemark" STRING ;
BA_DEF_ SG_  "GenSigEvent" STRING ;
BA_DEF_ SG_  "SystemSignalLongSymbol" STRING ;
BA_DEF_REL_ BU_SG_REL_  "GenSigTimeoutTime" INT 0 5000;
BA_DEF_DEF_  "GenSigStartValue" 0;
BA_DEF_DEF_  "GenMsgILSupport" "Yes";
BA_DEF_DEF_  "CanTpSTmin" 1;
BA_DEF_DEF_  "CanTpFcFrameId" 2147483647;
BA_DEF_DEF_  "GenSigSendType" "NoSigSendType";
BA_DEF_DEF_  "GenMsgCycleTime" 0;
BA_DEF_DEF_  "GenMsgSendType" "NoMsgSendType";
BA_DEF_DEF_  "GenSigInvalidValue" 0;
BA_DEF_DEF_  "GenSigStartRemark" "";
BA_DEF_DEF_  "GenSigInvalidRemark" "";
BA_DEF_DEF_  "GenSigEvent" "";
BA_DEF_DEF_REL_ "GenSigTimeoutTime" 0;
BA_DEF_DEF_  "SystemSignalLongSymbol" "";
BA_ "GenMsgSendType" BO_ 617 0;
BA_ "GenMsgCycleTime" BO_ 617 100;
BA_ "GenMsgSendType" BO_ 620 0;
BA_ "GenMsgCycleTime" BO_ 620 100;
BA_ "GenMsgSendType" BO_ 870 0;
BA_ "GenMsgCycleTime" BO_ 870 50;
BA_ "GenMsgSendType" BO_ 864 0;
BA_ "GenMsgCycleTime" BO_ 864 50;
BA_ "GenMsgSendType" BO_ 866 0;
BA_ "GenMsgCycleTime" BO_ 866 50;
BA_ "GenMsgSendType" BO_ 868 0;
BA_ "GenMsgCycleTime" BO_ 868 50;
BA_ "GenMsgSendType" BO_ 871 0;
BA_ "GenMsgCycleTime" BO_ 871 50;
BA_ "GenMsgSendType" BO_ 865 0;
BA_ "GenMsgCycleTime" BO_ 865 50;
BA_ "GenMsgSendType" BO_ 867 0;
BA_ "GenMsgCycleTime" BO_ 867 50;
BA_ "GenMsgSendType" BO_ 869 0;
BA_ "GenMsgCycleTime" BO_ 869 50;
BA_ "GenMsgSendType" BO_ 962 0;
BA_ "GenMsgCycleTime" BO_ 962 50;
BA_ "GenMsgSendType" BO_ 964 0;
BA_ "GenMsgCycleTime" BO_ 964 50;
BA_ "GenMsgSendType" BO_ 966 0;
BA_ "GenMsgCycleTime" BO_ 966 50;
BA_ "GenMsgSendType" BO_ 968 0;
BA_ "GenMsgCycleTime" BO_ 968 50;
BA_ "GenMsgSendType" BO_ 970 0;
BA_ "GenMsgCycleTime" BO_ 970 50;
BA_ "GenMsgSendType" BO_ 972 0;
BA_ "GenMsgCycleTime" BO_ 972 50;
BA_ "GenMsgSendType" BO_ 963 0;
BA_ "GenMsgCycleTime" BO_ 963 50;
BA_ "GenMsgSendType" BO_ 965 0;
BA_ "GenMsgCycleTime" BO_ 965 50;
BA_ "GenMsgSendType" BO_ 975 0;
BA_ "GenMsgCycleTime" BO_ 975 50;
BA_ "GenMsgSendType" BO_ 969 0;
BA_ "GenMsgCycleTime" BO_ 969 50;
BA_ "GenMsgSendType" BO_ 971 0;
BA_ "GenMsgCycleTime" BO_ 971 50;
BA_ "GenMsgSendType" BO_ 973 0;
BA_ "GenMsgCycleTime" BO_ 973 50;
BA_ "GenMsgSendType" BO_ 602 0;
BA_ "GenMsgCycleTime" BO_ 602 100;
BA_ "GenMsgSendType" BO_ 603 0;
BA_ "GenMsgCycleTime" BO_ 603 100;
BA_ "GenMsgSendType" BO_ 606 0;
BA_ "GenMsgCycleTime" BO_ 606 100;
BA_ "GenMsgSendType" BO_ 667 0;
BA_ "GenMsgCycleTime" BO_ 667 100;
BA_ "GenMsgSendType" BO_ 576 0;
BA_ "GenMsgCycleTime" BO_ 576 100;
BA_ "GenMsgCycleTime" BO_ 737 100;
BA_ "GenMsgSendType" BO_ 737 0;
BA_ "GenMsgSendType" BO_ 434 0;
BA_ "GenMsgCycleTime" BO_ 434 100;
BA_ "GenMsgSendType" BO_ 435 0;
BA_ "GenMsgCycleTime" BO_ 435 100;
BA_ "GenMsgSendType" BO_ 436 0;
BA_ "GenMsgCycleTime" BO_ 436 100;
BA_ "GenMsgSendType" BO_ 437 0;
BA_ "GenMsgCycleTime" BO_ 437 100;
BA_ "GenMsgSendType" BO_ 601 0;
BA_ "GenMsgCycleTime" BO_ 601 100;
BA_ "GenMsgSendType" BO_ 422 0;
BA_ "GenMsgCycleTime" BO_ 422 50;
BA_ "GenMsgSendType" BO_ 520 0;
BA_ "GenMsgCycleTime" BO_ 520 100;
BA_ "GenMsgSendType" BO_ 755 0;
BA_ "GenMsgCycleTime" BO_ 755 100;
BA_ "GenMsgCycleTime" BO_ 685 100;
BA_ "GenMsgSendType" BO_ 685 0;
BA_ "GenMsgSendType" BO_ 672 0;
BA_ "GenMsgCycleTime" BO_ 672 100;
BA_ "GenMsgSendType" BO_ 519 0;
BA_ "GenMsgCycleTime" BO_ 519 100;
BA_ "GenMsgSendType" BO_ 733 0;
BA_ "GenMsgCycleTime" BO_ 733 100;
BA_ "GenMsgSendType" BO_ 732 0;
BA_ "GenMsgCycleTime" BO_ 732 100;
BA_ "GenMsgSendType" BO_ 566 0;
BA_ "GenMsgCycleTime" BO_ 566 100;
BA_ "GenMsgCycleTime" BO_ 644 100;
BA_ "GenMsgSendType" BO_ 644 0;
BA_ "GenMsgCycleTime" BO_ 657 100;
BA_ "GenMsgSendType" BO_ 657 0;
BA_ "GenMsgSendType" BO_ 587 0;
BA_ "GenMsgCycleTime" BO_ 587 100;
BA_ "GenMsgSendType" BO_ 686 0;
BA_ "GenMsgCycleTime" BO_ 686 100;
BA_ "GenSigStartRemark" SG_ 617 Checksum_LCDAS_1 "V";
BA_ "GenSigStartRemark" SG_ 617 LCDAS_WorkingSt_RCTB "L";
BA_ "GenSigStartRemark" SG_ 620 Checksum_Fradar_1 "V";
BA_ "GenSigStartRemark" SG_ 870 Checksum_RMradar_Obj1_4 "V";
BA_ "GenSigInvalidRemark" SG_ 870 RMradar_Timestamp_Obj1_1 "O";
BA_ "GenSigStartRemark" SG_ 870 RMradar_Timestamp_Obj1_1 "O";
BA_ "GenSigInvalidValue" SG_ 870 RMradar_Timestamp_Obj1_1 65535;
BA_ "GenSigStartValue" SG_ 870 RMradar_Timestamp_Obj1_1 65534;
BA_ "GenSigStartRemark" SG_ 864 Checksum_RMradar_Obj1_1 "V";
BA_ "GenSigInvalidRemark" SG_ 864 RMradar_Obj1_Heading "125";
BA_ "GenSigStartRemark" SG_ 864 RMradar_Obj1_Heading "125";
BA_ "GenSigInvalidValue" SG_ 864 RMradar_Obj1_Heading 255;
BA_ "GenSigStartValue" SG_ 864 RMradar_Obj1_Heading 254;
BA_ "GenSigInvalidRemark" SG_ 864 RMradar_Obj1_YSpeedRelative "500";
BA_ "GenSigStartRemark" SG_ 864 RMradar_Obj1_YSpeedRelative "500";
BA_ "GenSigInvalidValue" SG_ 864 RMradar_Obj1_YSpeedRelative 511;
BA_ "GenSigStartValue" SG_ 864 RMradar_Obj1_YSpeedRelative 510;
BA_ "GenSigStartRemark" SG_ 864 RMradar_Obj1_ID "O";
BA_ "GenSigStartValue" SG_ 864 RMradar_Obj1_ID 4095;
BA_ "GenSigInvalidRemark" SG_ 864 RMradar_Obj1_ExstProb "20";
BA_ "GenSigStartRemark" SG_ 864 RMradar_Obj1_ExstProb "20";
BA_ "GenSigInvalidValue" SG_ 864 RMradar_Obj1_ExstProb 31;
BA_ "GenSigStartValue" SG_ 864 RMradar_Obj1_ExstProb 30;
BA_ "GenSigInvalidRemark" SG_ 864 RMradar_Obj1_Classify_Quality "20";
BA_ "GenSigStartRemark" SG_ 864 RMradar_Obj1_Classify_Quality "20";
BA_ "GenSigInvalidValue" SG_ 864 RMradar_Obj1_Classify_Quality 31;
BA_ "GenSigStartValue" SG_ 864 RMradar_Obj1_Classify_Quality 30;
BA_ "GenSigStartRemark" SG_ 866 Checksum_RMradar_Obj1_2 "V";
BA_ "GenSigInvalidRemark" SG_ 866 RMradar_Obj1_XAccRelative "O";
BA_ "GenSigStartRemark" SG_ 866 RMradar_Obj1_XAccRelative "O";
BA_ "GenSigInvalidValue" SG_ 866 RMradar_Obj1_XAccRelative 255;
BA_ "GenSigStartValue" SG_ 866 RMradar_Obj1_XAccRelative 254;
BA_ "GenSigInvalidRemark" SG_ 866 RMradar_Obj1_YAccRelative "O";
BA_ "GenSigStartRemark" SG_ 866 RMradar_Obj1_YAccRelative "O";
BA_ "GenSigInvalidValue" SG_ 866 RMradar_Obj1_YAccRelative 255;
BA_ "GenSigStartValue" SG_ 866 RMradar_Obj1_YAccRelative 254;
BA_ "GenSigInvalidRemark" SG_ 866 RMradar_Obj1_YPos_Near "4000";
BA_ "GenSigStartRemark" SG_ 866 RMradar_Obj1_YPos_Near "4000";
BA_ "GenSigInvalidValue" SG_ 866 RMradar_Obj1_YPos_Near 4095;
BA_ "GenSigStartValue" SG_ 866 RMradar_Obj1_YPos_Near 4094;
BA_ "GenSigInvalidRemark" SG_ 866 RMradar_Obj1_YPos_Left "4000";
BA_ "GenSigStartRemark" SG_ 866 RMradar_Obj1_YPos_Left "4000";
BA_ "GenSigInvalidValue" SG_ 866 RMradar_Obj1_YPos_Left 4095;
BA_ "GenSigStartValue" SG_ 866 RMradar_Obj1_YPos_Left 4094;
BA_ "GenSigInvalidRemark" SG_ 866 RMradar_Obj1_YPos_Right "4000";
BA_ "GenSigStartRemark" SG_ 866 RMradar_Obj1_YPos_Right "4000";
BA_ "GenSigInvalidValue" SG_ 866 RMradar_Obj1_YPos_Right 4095;
BA_ "GenSigStartValue" SG_ 866 RMradar_Obj1_YPos_Right 4094;
BA_ "GenSigStartRemark" SG_ 868 Checksum_RMradar_Obj1_3 "V";
BA_ "GenSigInvalidRemark" SG_ 868 RMradar_Obj1_XSpeedRelative "800";
BA_ "GenSigStartRemark" SG_ 868 RMradar_Obj1_XSpeedRelative "800";
BA_ "GenSigInvalidValue" SG_ 868 RMradar_Obj1_XSpeedRelative 1023;
BA_ "GenSigStartValue" SG_ 868 RMradar_Obj1_XSpeedRelative 1022;
BA_ "GenSigInvalidRemark" SG_ 868 RMradar_Obj1_XPos_Near "4000";
BA_ "GenSigStartRemark" SG_ 868 RMradar_Obj1_XPos_Near "4000";
BA_ "GenSigInvalidValue" SG_ 868 RMradar_Obj1_XPos_Near 4095;
BA_ "GenSigStartValue" SG_ 868 RMradar_Obj1_XPos_Near 4094;
BA_ "GenSigInvalidRemark" SG_ 868 RMradar_Obj1_XPos_Left "4000";
BA_ "GenSigStartRemark" SG_ 868 RMradar_Obj1_XPos_Left "4000";
BA_ "GenSigInvalidValue" SG_ 868 RMradar_Obj1_XPos_Left 4095;
BA_ "GenSigStartValue" SG_ 868 RMradar_Obj1_XPos_Left 4094;
BA_ "GenSigInvalidRemark" SG_ 868 RMradar_Obj1_XPos_Right "4000";
BA_ "GenSigStartRemark" SG_ 868 RMradar_Obj1_XPos_Right "4000";
BA_ "GenSigInvalidValue" SG_ 868 RMradar_Obj1_XPos_Right 4095;
BA_ "GenSigStartValue" SG_ 868 RMradar_Obj1_XPos_Right 4094;
BA_ "GenSigStartRemark" SG_ 871 Checksum_RSradar_Obj1_4 "V";
BA_ "GenSigInvalidRemark" SG_ 871 RSradar_Timestamp_Obj1_1 "O";
BA_ "GenSigStartRemark" SG_ 871 RSradar_Timestamp_Obj1_1 "O";
BA_ "GenSigInvalidValue" SG_ 871 RSradar_Timestamp_Obj1_1 65535;
BA_ "GenSigStartValue" SG_ 871 RSradar_Timestamp_Obj1_1 65534;
BA_ "GenSigStartRemark" SG_ 865 Checksum_RSradar_Obj1_1 "V";
BA_ "GenSigInvalidRemark" SG_ 865 RSradar_Obj1_Heading "125";
BA_ "GenSigStartRemark" SG_ 865 RSradar_Obj1_Heading "125";
BA_ "GenSigInvalidValue" SG_ 865 RSradar_Obj1_Heading 255;
BA_ "GenSigStartValue" SG_ 865 RSradar_Obj1_Heading 254;
BA_ "GenSigInvalidRemark" SG_ 865 RSradar_Obj1_YSpeedRelative "500";
BA_ "GenSigStartRemark" SG_ 865 RSradar_Obj1_YSpeedRelative "500";
BA_ "GenSigInvalidValue" SG_ 865 RSradar_Obj1_YSpeedRelative 511;
BA_ "GenSigStartValue" SG_ 865 RSradar_Obj1_YSpeedRelative 510;
BA_ "GenSigStartRemark" SG_ 865 RSradar_Obj1_ID "O";
BA_ "GenSigStartValue" SG_ 865 RSradar_Obj1_ID 4095;
BA_ "GenSigInvalidRemark" SG_ 865 RSradar_Obj1_ExstProb "20";
BA_ "GenSigStartRemark" SG_ 865 RSradar_Obj1_ExstProb "20";
BA_ "GenSigInvalidValue" SG_ 865 RSradar_Obj1_ExstProb 31;
BA_ "GenSigStartValue" SG_ 865 RSradar_Obj1_ExstProb 30;
BA_ "GenSigInvalidRemark" SG_ 865 RSradar_Obj1_Classify_Quality "20";
BA_ "GenSigStartRemark" SG_ 865 RSradar_Obj1_Classify_Quality "20";
BA_ "GenSigInvalidValue" SG_ 865 RSradar_Obj1_Classify_Quality 31;
BA_ "GenSigStartValue" SG_ 865 RSradar_Obj1_Classify_Quality 30;
BA_ "GenSigStartRemark" SG_ 867 Checksum_RSradar_Obj1_2 "V";
BA_ "GenSigInvalidRemark" SG_ 867 RSradar_Obj1_XAccRelative "O";
BA_ "GenSigStartRemark" SG_ 867 RSradar_Obj1_XAccRelative "O";
BA_ "GenSigInvalidValue" SG_ 867 RSradar_Obj1_XAccRelative 255;
BA_ "GenSigStartValue" SG_ 867 RSradar_Obj1_XAccRelative 254;
BA_ "GenSigInvalidRemark" SG_ 867 RSradar_Obj1_YAccRelative "O";
BA_ "GenSigStartRemark" SG_ 867 RSradar_Obj1_YAccRelative "O";
BA_ "GenSigInvalidValue" SG_ 867 RSradar_Obj1_YAccRelative 255;
BA_ "GenSigStartValue" SG_ 867 RSradar_Obj1_YAccRelative 254;
BA_ "GenSigInvalidRemark" SG_ 867 RSradar_Obj1_YPos_Near "4000";
BA_ "GenSigStartRemark" SG_ 867 RSradar_Obj1_YPos_Near "4000";
BA_ "GenSigInvalidValue" SG_ 867 RSradar_Obj1_YPos_Near 4095;
BA_ "GenSigStartValue" SG_ 867 RSradar_Obj1_YPos_Near 4094;
BA_ "GenSigInvalidRemark" SG_ 867 RSradar_Obj1_YPos_Left "4000";
BA_ "GenSigStartRemark" SG_ 867 RSradar_Obj1_YPos_Left "4000";
BA_ "GenSigInvalidValue" SG_ 867 RSradar_Obj1_YPos_Left 4095;
BA_ "GenSigStartValue" SG_ 867 RSradar_Obj1_YPos_Left 4094;
BA_ "GenSigInvalidRemark" SG_ 867 RSradar_Obj1_YPos_Right "4000";
BA_ "GenSigStartRemark" SG_ 867 RSradar_Obj1_YPos_Right "4000";
BA_ "GenSigInvalidValue" SG_ 867 RSradar_Obj1_YPos_Right 4095;
BA_ "GenSigStartValue" SG_ 867 RSradar_Obj1_YPos_Right 4094;
BA_ "GenSigStartRemark" SG_ 869 Checksum_RSradar_Obj1_3 "V";
BA_ "GenSigInvalidRemark" SG_ 869 RSradar_Obj1_XSpeedRelative "800";
BA_ "GenSigStartRemark" SG_ 869 RSradar_Obj1_XSpeedRelative "800";
BA_ "GenSigInvalidValue" SG_ 869 RSradar_Obj1_XSpeedRelative 1023;
BA_ "GenSigStartValue" SG_ 869 RSradar_Obj1_XSpeedRelative 1022;
BA_ "GenSigInvalidRemark" SG_ 869 RSradar_Obj1_XPos_Near "4000";
BA_ "GenSigStartRemark" SG_ 869 RSradar_Obj1_XPos_Near "4000";
BA_ "GenSigInvalidValue" SG_ 869 RSradar_Obj1_XPos_Near 4095;
BA_ "GenSigStartValue" SG_ 869 RSradar_Obj1_XPos_Near 4094;
BA_ "GenSigInvalidRemark" SG_ 869 RSradar_Obj1_XPos_Left "4000";
BA_ "GenSigStartRemark" SG_ 869 RSradar_Obj1_XPos_Left "4000";
BA_ "GenSigInvalidValue" SG_ 869 RSradar_Obj1_XPos_Left 4095;
BA_ "GenSigStartValue" SG_ 869 RSradar_Obj1_XPos_Left 4094;
BA_ "GenSigInvalidRemark" SG_ 869 RSradar_Obj1_XPos_Right "4000";
BA_ "GenSigStartRemark" SG_ 869 RSradar_Obj1_XPos_Right "4000";
BA_ "GenSigInvalidValue" SG_ 869 RSradar_Obj1_XPos_Right 4095;
BA_ "GenSigStartValue" SG_ 869 RSradar_Obj1_XPos_Right 4094;
BA_ "GenSigStartRemark" SG_ 962 Checksum_RMradar_Free_1 "V";
BA_ "GenSigInvalidRemark" SG_ 962 RMradar_FSP_Sector_01_Range "250";
BA_ "GenSigStartRemark" SG_ 962 RMradar_FSP_Sector_01_Range "250";
BA_ "GenSigInvalidValue" SG_ 962 RMradar_FSP_Sector_01_Range 255;
BA_ "GenSigStartValue" SG_ 962 RMradar_FSP_Sector_01_Range 254;
BA_ "GenSigInvalidRemark" SG_ 962 RMradar_FSP_Sector_02_Range "250";
BA_ "GenSigStartRemark" SG_ 962 RMradar_FSP_Sector_02_Range "250";
BA_ "GenSigInvalidValue" SG_ 962 RMradar_FSP_Sector_02_Range 255;
BA_ "GenSigStartValue" SG_ 962 RMradar_FSP_Sector_02_Range 254;
BA_ "GenSigInvalidRemark" SG_ 962 RMradar_FSP_Sector_03_Range "250";
BA_ "GenSigStartRemark" SG_ 962 RMradar_FSP_Sector_03_Range "250";
BA_ "GenSigInvalidValue" SG_ 962 RMradar_FSP_Sector_03_Range 255;
BA_ "GenSigStartValue" SG_ 962 RMradar_FSP_Sector_03_Range 254;
BA_ "GenSigInvalidRemark" SG_ 962 RMradar_FSP_Sector_04_Range "250";
BA_ "GenSigStartRemark" SG_ 962 RMradar_FSP_Sector_04_Range "250";
BA_ "GenSigInvalidValue" SG_ 962 RMradar_FSP_Sector_04_Range 255;
BA_ "GenSigStartValue" SG_ 962 RMradar_FSP_Sector_04_Range 254;
BA_ "GenSigInvalidRemark" SG_ 962 RMradar_FSP_Sector_05_Range "250";
BA_ "GenSigStartRemark" SG_ 962 RMradar_FSP_Sector_05_Range "250";
BA_ "GenSigInvalidValue" SG_ 962 RMradar_FSP_Sector_05_Range 255;
BA_ "GenSigStartValue" SG_ 962 RMradar_FSP_Sector_05_Range 254;
BA_ "GenSigInvalidRemark" SG_ 962 RMradar_FSP_Sector_06_Range "250";
BA_ "GenSigStartRemark" SG_ 962 RMradar_FSP_Sector_06_Range "250";
BA_ "GenSigInvalidValue" SG_ 962 RMradar_FSP_Sector_06_Range 255;
BA_ "GenSigStartValue" SG_ 962 RMradar_FSP_Sector_06_Range 254;
BA_ "GenSigStartRemark" SG_ 964 Checksum_RMradar_Free_2 "V";
BA_ "GenSigInvalidRemark" SG_ 964 RMradar_FSP_Sector_07_Range "250";
BA_ "GenSigStartRemark" SG_ 964 RMradar_FSP_Sector_07_Range "250";
BA_ "GenSigInvalidValue" SG_ 964 RMradar_FSP_Sector_07_Range 255;
BA_ "GenSigStartValue" SG_ 964 RMradar_FSP_Sector_07_Range 254;
BA_ "GenSigInvalidRemark" SG_ 964 RMradar_FSP_Sector_08_Range "250";
BA_ "GenSigStartRemark" SG_ 964 RMradar_FSP_Sector_08_Range "250";
BA_ "GenSigInvalidValue" SG_ 964 RMradar_FSP_Sector_08_Range 255;
BA_ "GenSigStartValue" SG_ 964 RMradar_FSP_Sector_08_Range 254;
BA_ "GenSigInvalidRemark" SG_ 964 RMradar_FSP_Sector_09_Range "250";
BA_ "GenSigStartRemark" SG_ 964 RMradar_FSP_Sector_09_Range "250";
BA_ "GenSigInvalidValue" SG_ 964 RMradar_FSP_Sector_09_Range 255;
BA_ "GenSigStartValue" SG_ 964 RMradar_FSP_Sector_09_Range 254;
BA_ "GenSigInvalidRemark" SG_ 964 RMradar_FSP_Sector_10_Range "250";
BA_ "GenSigStartRemark" SG_ 964 RMradar_FSP_Sector_10_Range "250";
BA_ "GenSigInvalidValue" SG_ 964 RMradar_FSP_Sector_10_Range 255;
BA_ "GenSigStartValue" SG_ 964 RMradar_FSP_Sector_10_Range 254;
BA_ "GenSigInvalidRemark" SG_ 964 RMradar_FSP_Sector_11_Range "250";
BA_ "GenSigStartRemark" SG_ 964 RMradar_FSP_Sector_11_Range "250";
BA_ "GenSigInvalidValue" SG_ 964 RMradar_FSP_Sector_11_Range 255;
BA_ "GenSigStartValue" SG_ 964 RMradar_FSP_Sector_11_Range 254;
BA_ "GenSigInvalidRemark" SG_ 964 RMradar_FSP_Sector_12_Range "250";
BA_ "GenSigStartRemark" SG_ 964 RMradar_FSP_Sector_12_Range "250";
BA_ "GenSigInvalidValue" SG_ 964 RMradar_FSP_Sector_12_Range 255;
BA_ "GenSigStartValue" SG_ 964 RMradar_FSP_Sector_12_Range 254;
BA_ "GenSigStartRemark" SG_ 966 Checksum_RMradar_Free_3 "V";
BA_ "GenSigInvalidRemark" SG_ 966 RMradar_FSP_Sector_13_Range "250";
BA_ "GenSigStartRemark" SG_ 966 RMradar_FSP_Sector_13_Range "250";
BA_ "GenSigInvalidValue" SG_ 966 RMradar_FSP_Sector_13_Range 255;
BA_ "GenSigStartValue" SG_ 966 RMradar_FSP_Sector_13_Range 254;
BA_ "GenSigInvalidRemark" SG_ 966 RMradar_FSP_Sector_14_Range "250";
BA_ "GenSigStartRemark" SG_ 966 RMradar_FSP_Sector_14_Range "250";
BA_ "GenSigInvalidValue" SG_ 966 RMradar_FSP_Sector_14_Range 255;
BA_ "GenSigStartValue" SG_ 966 RMradar_FSP_Sector_14_Range 254;
BA_ "GenSigInvalidRemark" SG_ 966 RMradar_FSP_Sector_15_Range "250";
BA_ "GenSigStartRemark" SG_ 966 RMradar_FSP_Sector_15_Range "250";
BA_ "GenSigInvalidValue" SG_ 966 RMradar_FSP_Sector_15_Range 255;
BA_ "GenSigStartValue" SG_ 966 RMradar_FSP_Sector_15_Range 254;
BA_ "GenSigInvalidRemark" SG_ 966 RMradar_FSP_Sector_16_Range "250";
BA_ "GenSigStartRemark" SG_ 966 RMradar_FSP_Sector_16_Range "250";
BA_ "GenSigInvalidValue" SG_ 966 RMradar_FSP_Sector_16_Range 255;
BA_ "GenSigStartValue" SG_ 966 RMradar_FSP_Sector_16_Range 254;
BA_ "GenSigInvalidRemark" SG_ 966 RMradar_FSP_Sector_17_Range "250";
BA_ "GenSigStartRemark" SG_ 966 RMradar_FSP_Sector_17_Range "250";
BA_ "GenSigInvalidValue" SG_ 966 RMradar_FSP_Sector_17_Range 255;
BA_ "GenSigStartValue" SG_ 966 RMradar_FSP_Sector_17_Range 254;
BA_ "GenSigInvalidRemark" SG_ 966 RMradar_FSP_Sector_18_Range "250";
BA_ "GenSigStartRemark" SG_ 966 RMradar_FSP_Sector_18_Range "250";
BA_ "GenSigInvalidValue" SG_ 966 RMradar_FSP_Sector_18_Range 255;
BA_ "GenSigStartValue" SG_ 966 RMradar_FSP_Sector_18_Range 254;
BA_ "GenSigStartRemark" SG_ 968 Checksum_RMradar_Free_4 "V";
BA_ "GenSigInvalidRemark" SG_ 968 RMradar_FSP_Sector_19_Range "250";
BA_ "GenSigStartRemark" SG_ 968 RMradar_FSP_Sector_19_Range "250";
BA_ "GenSigInvalidValue" SG_ 968 RMradar_FSP_Sector_19_Range 255;
BA_ "GenSigStartValue" SG_ 968 RMradar_FSP_Sector_19_Range 254;
BA_ "GenSigInvalidRemark" SG_ 968 RMradar_FSP_Sector_20_Range "250";
BA_ "GenSigStartRemark" SG_ 968 RMradar_FSP_Sector_20_Range "250";
BA_ "GenSigInvalidValue" SG_ 968 RMradar_FSP_Sector_20_Range 255;
BA_ "GenSigStartValue" SG_ 968 RMradar_FSP_Sector_20_Range 254;
BA_ "GenSigInvalidRemark" SG_ 968 RMradar_FSP_Sector_21_Range "250";
BA_ "GenSigStartRemark" SG_ 968 RMradar_FSP_Sector_21_Range "250";
BA_ "GenSigInvalidValue" SG_ 968 RMradar_FSP_Sector_21_Range 255;
BA_ "GenSigStartValue" SG_ 968 RMradar_FSP_Sector_21_Range 254;
BA_ "GenSigInvalidRemark" SG_ 968 RMradar_FSP_Sector_22_Range "250";
BA_ "GenSigStartRemark" SG_ 968 RMradar_FSP_Sector_22_Range "250";
BA_ "GenSigInvalidValue" SG_ 968 RMradar_FSP_Sector_22_Range 255;
BA_ "GenSigStartValue" SG_ 968 RMradar_FSP_Sector_22_Range 254;
BA_ "GenSigInvalidRemark" SG_ 968 RMradar_FSP_Sector_23_Range "250";
BA_ "GenSigStartRemark" SG_ 968 RMradar_FSP_Sector_23_Range "250";
BA_ "GenSigInvalidValue" SG_ 968 RMradar_FSP_Sector_23_Range 255;
BA_ "GenSigStartValue" SG_ 968 RMradar_FSP_Sector_23_Range 254;
BA_ "GenSigInvalidRemark" SG_ 968 RMradar_FSP_Sector_24_Range "250";
BA_ "GenSigStartRemark" SG_ 968 RMradar_FSP_Sector_24_Range "250";
BA_ "GenSigInvalidValue" SG_ 968 RMradar_FSP_Sector_24_Range 255;
BA_ "GenSigStartValue" SG_ 968 RMradar_FSP_Sector_24_Range 254;
BA_ "GenSigStartRemark" SG_ 970 Checksum_RMradar_Free_5 "V";
BA_ "GenSigInvalidRemark" SG_ 970 RMradar_FSP_Sector_25_Range "250";
BA_ "GenSigStartRemark" SG_ 970 RMradar_FSP_Sector_25_Range "250";
BA_ "GenSigInvalidValue" SG_ 970 RMradar_FSP_Sector_25_Range 255;
BA_ "GenSigStartValue" SG_ 970 RMradar_FSP_Sector_25_Range 254;
BA_ "GenSigInvalidRemark" SG_ 970 RMradar_FSP_Sector_26_Range "250";
BA_ "GenSigStartRemark" SG_ 970 RMradar_FSP_Sector_26_Range "250";
BA_ "GenSigInvalidValue" SG_ 970 RMradar_FSP_Sector_26_Range 255;
BA_ "GenSigStartValue" SG_ 970 RMradar_FSP_Sector_26_Range 254;
BA_ "GenSigInvalidRemark" SG_ 970 RMradar_FSP_Sector_27_Range "250";
BA_ "GenSigStartRemark" SG_ 970 RMradar_FSP_Sector_27_Range "250";
BA_ "GenSigInvalidValue" SG_ 970 RMradar_FSP_Sector_27_Range 255;
BA_ "GenSigStartValue" SG_ 970 RMradar_FSP_Sector_27_Range 254;
BA_ "GenSigInvalidRemark" SG_ 970 RMradar_FSP_Sector_28_Range "250";
BA_ "GenSigStartRemark" SG_ 970 RMradar_FSP_Sector_28_Range "250";
BA_ "GenSigInvalidValue" SG_ 970 RMradar_FSP_Sector_28_Range 255;
BA_ "GenSigStartValue" SG_ 970 RMradar_FSP_Sector_28_Range 254;
BA_ "GenSigInvalidRemark" SG_ 970 RMradar_FSP_Sector_29_Range "250";
BA_ "GenSigStartRemark" SG_ 970 RMradar_FSP_Sector_29_Range "250";
BA_ "GenSigInvalidValue" SG_ 970 RMradar_FSP_Sector_29_Range 255;
BA_ "GenSigStartValue" SG_ 970 RMradar_FSP_Sector_29_Range 254;
BA_ "GenSigInvalidRemark" SG_ 970 RMradar_FSP_Sector_30_Range "250";
BA_ "GenSigStartRemark" SG_ 970 RMradar_FSP_Sector_30_Range "250";
BA_ "GenSigInvalidValue" SG_ 970 RMradar_FSP_Sector_30_Range 255;
BA_ "GenSigStartValue" SG_ 970 RMradar_FSP_Sector_30_Range 254;
BA_ "GenSigStartRemark" SG_ 972 Checksum_RMradar_Free_6 "V";
BA_ "GenSigInvalidRemark" SG_ 972 RMradar_FSP_Sector_31_Range "250";
BA_ "GenSigStartRemark" SG_ 972 RMradar_FSP_Sector_31_Range "250";
BA_ "GenSigInvalidValue" SG_ 972 RMradar_FSP_Sector_31_Range 255;
BA_ "GenSigStartValue" SG_ 972 RMradar_FSP_Sector_31_Range 254;
BA_ "GenSigInvalidRemark" SG_ 972 RMradar_FSP_Sector_32_Range "250";
BA_ "GenSigStartRemark" SG_ 972 RMradar_FSP_Sector_32_Range "250";
BA_ "GenSigInvalidValue" SG_ 972 RMradar_FSP_Sector_32_Range 255;
BA_ "GenSigStartValue" SG_ 972 RMradar_FSP_Sector_32_Range 254;
BA_ "GenSigInvalidRemark" SG_ 972 RMradar_FSP_Sector_33_Range "250";
BA_ "GenSigStartRemark" SG_ 972 RMradar_FSP_Sector_33_Range "250";
BA_ "GenSigInvalidValue" SG_ 972 RMradar_FSP_Sector_33_Range 255;
BA_ "GenSigStartValue" SG_ 972 RMradar_FSP_Sector_33_Range 254;
BA_ "GenSigInvalidRemark" SG_ 972 RMradar_FSP_Sector_34_Range "250";
BA_ "GenSigStartRemark" SG_ 972 RMradar_FSP_Sector_34_Range "250";
BA_ "GenSigInvalidValue" SG_ 972 RMradar_FSP_Sector_34_Range 255;
BA_ "GenSigStartValue" SG_ 972 RMradar_FSP_Sector_34_Range 254;
BA_ "GenSigInvalidRemark" SG_ 972 RMradar_FSP_Sector_35_Range "250";
BA_ "GenSigStartRemark" SG_ 972 RMradar_FSP_Sector_35_Range "250";
BA_ "GenSigInvalidValue" SG_ 972 RMradar_FSP_Sector_35_Range 255;
BA_ "GenSigStartValue" SG_ 972 RMradar_FSP_Sector_35_Range 254;
BA_ "GenSigStartRemark" SG_ 963 Checksum_RSradar_Free_1 "V";
BA_ "GenSigInvalidRemark" SG_ 963 RSradar_FSP_Sector_01_Range "250";
BA_ "GenSigStartRemark" SG_ 963 RSradar_FSP_Sector_01_Range "250";
BA_ "GenSigInvalidValue" SG_ 963 RSradar_FSP_Sector_01_Range 255;
BA_ "GenSigStartValue" SG_ 963 RSradar_FSP_Sector_01_Range 254;
BA_ "GenSigInvalidRemark" SG_ 963 RSradar_FSP_Sector_02_Range "250";
BA_ "GenSigStartRemark" SG_ 963 RSradar_FSP_Sector_02_Range "250";
BA_ "GenSigInvalidValue" SG_ 963 RSradar_FSP_Sector_02_Range 255;
BA_ "GenSigStartValue" SG_ 963 RSradar_FSP_Sector_02_Range 254;
BA_ "GenSigInvalidRemark" SG_ 963 RSradar_FSP_Sector_03_Range "250";
BA_ "GenSigStartRemark" SG_ 963 RSradar_FSP_Sector_03_Range "250";
BA_ "GenSigInvalidValue" SG_ 963 RSradar_FSP_Sector_03_Range 255;
BA_ "GenSigStartValue" SG_ 963 RSradar_FSP_Sector_03_Range 254;
BA_ "GenSigInvalidRemark" SG_ 963 RSradar_FSP_Sector_04_Range "250";
BA_ "GenSigStartRemark" SG_ 963 RSradar_FSP_Sector_04_Range "250";
BA_ "GenSigInvalidValue" SG_ 963 RSradar_FSP_Sector_04_Range 255;
BA_ "GenSigStartValue" SG_ 963 RSradar_FSP_Sector_04_Range 254;
BA_ "GenSigInvalidRemark" SG_ 963 RSradar_FSP_Sector_05_Range "250";
BA_ "GenSigStartRemark" SG_ 963 RSradar_FSP_Sector_05_Range "250";
BA_ "GenSigInvalidValue" SG_ 963 RSradar_FSP_Sector_05_Range 255;
BA_ "GenSigStartValue" SG_ 963 RSradar_FSP_Sector_05_Range 254;
BA_ "GenSigInvalidRemark" SG_ 963 RSradar_FSP_Sector_06_Range "250";
BA_ "GenSigStartRemark" SG_ 963 RSradar_FSP_Sector_06_Range "250";
BA_ "GenSigInvalidValue" SG_ 963 RSradar_FSP_Sector_06_Range 255;
BA_ "GenSigStartValue" SG_ 963 RSradar_FSP_Sector_06_Range 254;
BA_ "GenSigStartRemark" SG_ 965 Checksum_RSradar_Free_2 "V";
BA_ "GenSigInvalidRemark" SG_ 965 RSradar_FSP_Sector_07_Range "250";
BA_ "GenSigStartRemark" SG_ 965 RSradar_FSP_Sector_07_Range "250";
BA_ "GenSigInvalidValue" SG_ 965 RSradar_FSP_Sector_07_Range 255;
BA_ "GenSigStartValue" SG_ 965 RSradar_FSP_Sector_07_Range 254;
BA_ "GenSigInvalidRemark" SG_ 965 RSradar_FSP_Sector_08_Range "250";
BA_ "GenSigStartRemark" SG_ 965 RSradar_FSP_Sector_08_Range "250";
BA_ "GenSigInvalidValue" SG_ 965 RSradar_FSP_Sector_08_Range 255;
BA_ "GenSigStartValue" SG_ 965 RSradar_FSP_Sector_08_Range 254;
BA_ "GenSigInvalidRemark" SG_ 965 RSradar_FSP_Sector_09_Range "250";
BA_ "GenSigStartRemark" SG_ 965 RSradar_FSP_Sector_09_Range "250";
BA_ "GenSigInvalidValue" SG_ 965 RSradar_FSP_Sector_09_Range 255;
BA_ "GenSigStartValue" SG_ 965 RSradar_FSP_Sector_09_Range 254;
BA_ "GenSigInvalidRemark" SG_ 965 RSradar_FSP_Sector_10_Range "250";
BA_ "GenSigStartRemark" SG_ 965 RSradar_FSP_Sector_10_Range "250";
BA_ "GenSigInvalidValue" SG_ 965 RSradar_FSP_Sector_10_Range 255;
BA_ "GenSigStartValue" SG_ 965 RSradar_FSP_Sector_10_Range 254;
BA_ "GenSigInvalidRemark" SG_ 965 RSradar_FSP_Sector_11_Range "250";
BA_ "GenSigStartRemark" SG_ 965 RSradar_FSP_Sector_11_Range "250";
BA_ "GenSigInvalidValue" SG_ 965 RSradar_FSP_Sector_11_Range 255;
BA_ "GenSigStartValue" SG_ 965 RSradar_FSP_Sector_11_Range 254;
BA_ "GenSigInvalidRemark" SG_ 965 RSradar_FSP_Sector_12_Range "250";
BA_ "GenSigStartRemark" SG_ 965 RSradar_FSP_Sector_12_Range "250";
BA_ "GenSigInvalidValue" SG_ 965 RSradar_FSP_Sector_12_Range 255;
BA_ "GenSigStartValue" SG_ 965 RSradar_FSP_Sector_12_Range 254;
BA_ "GenSigStartRemark" SG_ 975 Checksum_RSradar_Free_3 "V";
BA_ "GenSigInvalidRemark" SG_ 975 RSradar_FSP_Sector_13_Range "250";
BA_ "GenSigStartRemark" SG_ 975 RSradar_FSP_Sector_13_Range "250";
BA_ "GenSigInvalidValue" SG_ 975 RSradar_FSP_Sector_13_Range 255;
BA_ "GenSigStartValue" SG_ 975 RSradar_FSP_Sector_13_Range 254;
BA_ "GenSigInvalidRemark" SG_ 975 RSradar_FSP_Sector_14_Range "250";
BA_ "GenSigStartRemark" SG_ 975 RSradar_FSP_Sector_14_Range "250";
BA_ "GenSigInvalidValue" SG_ 975 RSradar_FSP_Sector_14_Range 255;
BA_ "GenSigStartValue" SG_ 975 RSradar_FSP_Sector_14_Range 254;
BA_ "GenSigInvalidRemark" SG_ 975 RSradar_FSP_Sector_15_Range "250";
BA_ "GenSigStartRemark" SG_ 975 RSradar_FSP_Sector_15_Range "250";
BA_ "GenSigInvalidValue" SG_ 975 RSradar_FSP_Sector_15_Range 255;
BA_ "GenSigStartValue" SG_ 975 RSradar_FSP_Sector_15_Range 254;
BA_ "GenSigInvalidRemark" SG_ 975 RSradar_FSP_Sector_16_Range "250";
BA_ "GenSigStartRemark" SG_ 975 RSradar_FSP_Sector_16_Range "250";
BA_ "GenSigInvalidValue" SG_ 975 RSradar_FSP_Sector_16_Range 255;
BA_ "GenSigStartValue" SG_ 975 RSradar_FSP_Sector_16_Range 254;
BA_ "GenSigInvalidRemark" SG_ 975 RSradar_FSP_Sector_17_Range "250";
BA_ "GenSigStartRemark" SG_ 975 RSradar_FSP_Sector_17_Range "250";
BA_ "GenSigInvalidValue" SG_ 975 RSradar_FSP_Sector_17_Range 255;
BA_ "GenSigStartValue" SG_ 975 RSradar_FSP_Sector_17_Range 254;
BA_ "GenSigInvalidRemark" SG_ 975 RSradar_FSP_Sector_18_Range "250";
BA_ "GenSigStartRemark" SG_ 975 RSradar_FSP_Sector_18_Range "250";
BA_ "GenSigInvalidValue" SG_ 975 RSradar_FSP_Sector_18_Range 255;
BA_ "GenSigStartValue" SG_ 975 RSradar_FSP_Sector_18_Range 254;
BA_ "GenSigStartRemark" SG_ 969 Checksum_RSradar_Free_4 "V";
BA_ "GenSigInvalidRemark" SG_ 969 RSradar_FSP_Sector_19_Range "250";
BA_ "GenSigStartRemark" SG_ 969 RSradar_FSP_Sector_19_Range "250";
BA_ "GenSigInvalidValue" SG_ 969 RSradar_FSP_Sector_19_Range 255;
BA_ "GenSigStartValue" SG_ 969 RSradar_FSP_Sector_19_Range 254;
BA_ "GenSigInvalidRemark" SG_ 969 RSradar_FSP_Sector_20_Range "250";
BA_ "GenSigStartRemark" SG_ 969 RSradar_FSP_Sector_20_Range "250";
BA_ "GenSigInvalidValue" SG_ 969 RSradar_FSP_Sector_20_Range 255;
BA_ "GenSigStartValue" SG_ 969 RSradar_FSP_Sector_20_Range 254;
BA_ "GenSigInvalidRemark" SG_ 969 RSradar_FSP_Sector_21_Range "250";
BA_ "GenSigStartRemark" SG_ 969 RSradar_FSP_Sector_21_Range "250";
BA_ "GenSigInvalidValue" SG_ 969 RSradar_FSP_Sector_21_Range 255;
BA_ "GenSigStartValue" SG_ 969 RSradar_FSP_Sector_21_Range 254;
BA_ "GenSigInvalidRemark" SG_ 969 RSradar_FSP_Sector_22_Range "250";
BA_ "GenSigStartRemark" SG_ 969 RSradar_FSP_Sector_22_Range "250";
BA_ "GenSigInvalidValue" SG_ 969 RSradar_FSP_Sector_22_Range 255;
BA_ "GenSigStartValue" SG_ 969 RSradar_FSP_Sector_22_Range 254;
BA_ "GenSigInvalidRemark" SG_ 969 RSradar_FSP_Sector_23_Range "250";
BA_ "GenSigStartRemark" SG_ 969 RSradar_FSP_Sector_23_Range "250";
BA_ "GenSigInvalidValue" SG_ 969 RSradar_FSP_Sector_23_Range 255;
BA_ "GenSigStartValue" SG_ 969 RSradar_FSP_Sector_23_Range 254;
BA_ "GenSigInvalidRemark" SG_ 969 RSradar_FSP_Sector_24_Range "250";
BA_ "GenSigStartRemark" SG_ 969 RSradar_FSP_Sector_24_Range "250";
BA_ "GenSigInvalidValue" SG_ 969 RSradar_FSP_Sector_24_Range 255;
BA_ "GenSigStartValue" SG_ 969 RSradar_FSP_Sector_24_Range 254;
BA_ "GenSigStartRemark" SG_ 971 Checksum_RSradar_Free_5 "V";
BA_ "GenSigInvalidRemark" SG_ 971 RSradar_FSP_Sector_25_Range "250";
BA_ "GenSigStartRemark" SG_ 971 RSradar_FSP_Sector_25_Range "250";
BA_ "GenSigInvalidValue" SG_ 971 RSradar_FSP_Sector_25_Range 255;
BA_ "GenSigStartValue" SG_ 971 RSradar_FSP_Sector_25_Range 254;
BA_ "GenSigInvalidRemark" SG_ 971 RSradar_FSP_Sector_26_Range "250";
BA_ "GenSigStartRemark" SG_ 971 RSradar_FSP_Sector_26_Range "250";
BA_ "GenSigInvalidValue" SG_ 971 RSradar_FSP_Sector_26_Range 255;
BA_ "GenSigStartValue" SG_ 971 RSradar_FSP_Sector_26_Range 254;
BA_ "GenSigInvalidRemark" SG_ 971 RSradar_FSP_Sector_27_Range "250";
BA_ "GenSigStartRemark" SG_ 971 RSradar_FSP_Sector_27_Range "250";
BA_ "GenSigInvalidValue" SG_ 971 RSradar_FSP_Sector_27_Range 255;
BA_ "GenSigStartValue" SG_ 971 RSradar_FSP_Sector_27_Range 254;
BA_ "GenSigInvalidRemark" SG_ 971 RSradar_FSP_Sector_28_Range "250";
BA_ "GenSigStartRemark" SG_ 971 RSradar_FSP_Sector_28_Range "250";
BA_ "GenSigInvalidValue" SG_ 971 RSradar_FSP_Sector_28_Range 255;
BA_ "GenSigStartValue" SG_ 971 RSradar_FSP_Sector_28_Range 254;
BA_ "GenSigInvalidRemark" SG_ 971 RSradar_FSP_Sector_29_Range "250";
BA_ "GenSigStartRemark" SG_ 971 RSradar_FSP_Sector_29_Range "250";
BA_ "GenSigInvalidValue" SG_ 971 RSradar_FSP_Sector_29_Range 255;
BA_ "GenSigStartValue" SG_ 971 RSradar_FSP_Sector_29_Range 254;
BA_ "GenSigInvalidRemark" SG_ 971 RSradar_FSP_Sector_30_Range "250";
BA_ "GenSigStartRemark" SG_ 971 RSradar_FSP_Sector_30_Range "250";
BA_ "GenSigInvalidValue" SG_ 971 RSradar_FSP_Sector_30_Range 255;
BA_ "GenSigStartValue" SG_ 971 RSradar_FSP_Sector_30_Range 254;
BA_ "GenSigStartRemark" SG_ 973 Checksum_RSradar_Free_6 "V";
BA_ "GenSigInvalidRemark" SG_ 973 RSradar_FSP_Sector_31_Range "250";
BA_ "GenSigStartRemark" SG_ 973 RSradar_FSP_Sector_31_Range "250";
BA_ "GenSigInvalidValue" SG_ 973 RSradar_FSP_Sector_31_Range 255;
BA_ "GenSigStartValue" SG_ 973 RSradar_FSP_Sector_31_Range 254;
BA_ "GenSigInvalidRemark" SG_ 973 RSradar_FSP_Sector_32_Range "250";
BA_ "GenSigStartRemark" SG_ 973 RSradar_FSP_Sector_32_Range "250";
BA_ "GenSigInvalidValue" SG_ 973 RSradar_FSP_Sector_32_Range 255;
BA_ "GenSigStartValue" SG_ 973 RSradar_FSP_Sector_32_Range 254;
BA_ "GenSigInvalidRemark" SG_ 973 RSradar_FSP_Sector_33_Range "250";
BA_ "GenSigStartRemark" SG_ 973 RSradar_FSP_Sector_33_Range "250";
BA_ "GenSigInvalidValue" SG_ 973 RSradar_FSP_Sector_33_Range 255;
BA_ "GenSigStartValue" SG_ 973 RSradar_FSP_Sector_33_Range 254;
BA_ "GenSigInvalidRemark" SG_ 973 RSradar_FSP_Sector_34_Range "250";
BA_ "GenSigStartRemark" SG_ 973 RSradar_FSP_Sector_34_Range "250";
BA_ "GenSigInvalidValue" SG_ 973 RSradar_FSP_Sector_34_Range 255;
BA_ "GenSigStartValue" SG_ 973 RSradar_FSP_Sector_34_Range 254;
BA_ "GenSigInvalidRemark" SG_ 973 RSradar_FSP_Sector_35_Range "250";
BA_ "GenSigStartRemark" SG_ 973 RSradar_FSP_Sector_35_Range "250";
BA_ "GenSigInvalidValue" SG_ 973 RSradar_FSP_Sector_35_Range 255;
BA_ "GenSigStartValue" SG_ 973 RSradar_FSP_Sector_35_Range 254;
BA_ "GenSigStartRemark" SG_ 602 Checksum_HAD_7 "V";
BA_ "GenSigStartRemark" SG_ 602 HAD_SetMaxVehcleSpeedFunSt "L";
BA_ "GenSigInvalidRemark" SG_ 602 HAD_MaxVehcleSpeedSetted "26";
BA_ "GenSigStartRemark" SG_ 602 HAD_MaxVehcleSpeedSetted "L";
BA_ "GenSigInvalidValue" SG_ 602 HAD_MaxVehcleSpeedSetted 31;
BA_ "GenSigStartRemark" SG_ 603 Checksum_HAD_8 "V";
BA_ "SystemSignalLongSymbol" SG_ 603 HAD_LongitudinalPosition_FrontVe "HAD_LongitudinalPosition_FrontVehcle";
BA_ "GenSigStartRemark" SG_ 606 Checksum_HAD_9 "V";
BA_ "GenSigStartRemark" SG_ 667 Checksum_HU_10 "V";
BA_ "GenSigInvalidRemark" SG_ 667 HU_MaxVehcleSpeed_Set "18";
BA_ "GenSigStartRemark" SG_ 667 HU_MaxVehcleSpeed_Set "18";
BA_ "GenSigInvalidValue" SG_ 667 HU_MaxVehcleSpeed_Set 31;
BA_ "GenSigStartValue" SG_ 667 HU_MaxVehcleSpeed_Set 30;
BA_ "GenSigEvent" SG_ 737 FCP_AVSFunctionReq "Y";
BA_ "GenSigSendType" SG_ 737 FCP_AVSFunctionReq 1;
BA_ "GenSigEvent" SG_ 737 FCP_PDCFunctionReq "Y";
BA_ "GenSigSendType" SG_ 737 FCP_PDCFunctionReq 1;
BA_ "GenSigEvent" SG_ 737 FCP_APAFunctionReq "Y";
BA_ "GenSigSendType" SG_ 737 FCP_APAFunctionReq 1;
BA_ "GenSigEvent" SG_ 737 FCP_AVPFunctionReq "Y";
BA_ "GenSigSendType" SG_ 737 FCP_AVPFunctionReq 1;
BA_ "GenSigStartRemark" SG_ 434 Checksum_IFC_7 "V";
BA_ "GenSigStartRemark" SG_ 435 Checksum_IFC_8 "V";
BA_ "GenSigStartRemark" SG_ 436 Checksum_IFC_9 "V";
BA_ "GenSigStartRemark" SG_ 437 Checksum_IFC_10 "V";
BA_ "GenSigStartRemark" SG_ 601 Checksum_HAD_12 "V";
BA_ "GenSigInvalidRemark" SG_ 520 HCU_BatteryPackSOC "100";
BA_ "GenSigStartRemark" SG_ 520 HCU_BatteryPackSOC "100";
BA_ "GenSigInvalidValue" SG_ 520 HCU_BatteryPackSOC 255;
BA_ "GenSigStartValue" SG_ 520 HCU_BatteryPackSOC 254;
BA_ "GenSigEvent" SG_ 685 DVR_AutoDriveDataRecordStatus "Y";
BA_ "GenSigSendType" SG_ 685 DVR_AutoDriveDataRecordStatus 1;
BA_ "GenSigEvent" SG_ 685 DVR_SystemSt "Y";
BA_ "GenSigSendType" SG_ 685 DVR_SystemSt 1;
BA_ "GenSigEvent" SG_ 685 DVR_AutoDriveDataRecordAvailable "Y";
BA_ "GenSigSendType" SG_ 685 DVR_AutoDriveDataRecordAvailable 1;
BA_ "GenSigStartRemark" SG_ 672 CheckSum_TBOX_1 "V";
BA_ "GenSigStartRemark" SG_ 733 Checksum_WOBC_2 "V";
BA_ "GenSigInvalidRemark" SG_ 733 WOBC_ContrapositionPosition_X "1000";
BA_ "GenSigStartRemark" SG_ 733 WOBC_ContrapositionPosition_X "1000";
BA_ "GenSigInvalidValue" SG_ 733 WOBC_ContrapositionPosition_X 1023;
BA_ "GenSigStartValue" SG_ 733 WOBC_ContrapositionPosition_X 1022;
BA_ "GenSigInvalidRemark" SG_ 733 WOBC_ContrapositionPosition_Y "1000";
BA_ "GenSigStartRemark" SG_ 733 WOBC_ContrapositionPosition_Y "1000";
BA_ "GenSigInvalidValue" SG_ 733 WOBC_ContrapositionPosition_Y 1023;
BA_ "GenSigStartValue" SG_ 733 WOBC_ContrapositionPosition_Y 1022;
BA_ "GenSigInvalidRemark" SG_ 733 WOBC_ContrapositionAngle "360";
BA_ "GenSigStartRemark" SG_ 733 WOBC_ContrapositionAngle "360";
BA_ "GenSigInvalidValue" SG_ 733 WOBC_ContrapositionAngle 511;
BA_ "GenSigStartValue" SG_ 733 WOBC_ContrapositionAngle 510;
BA_ "GenSigStartRemark" SG_ 732 Checksum_WOBC_1 "V";
BA_ "GenSigInvalidValue" SG_ 732 WOBC_ContrapositionStatus 15;
BA_ "GenSigStartValue" SG_ 732 WOBC_ContrapositionStatus 14;
BA_ "GenSigInvalidRemark" SG_ 644 AccountID_IVI "O";
BA_ "GenSigInvalidValue" SG_ 644 AccountID_IVI 15;
BA_ "GenSigEvent" SG_ 644 AccountBindFaceReq "Y";
BA_ "GenSigSendType" SG_ 644 AccountBindFaceReq 1;
BA_ "GenSigEvent" SG_ 657 DisplayTheme "Y";
BA_ "GenSigSendType" SG_ 657 DisplayTheme 1;
BA_ "GenSigStartRemark" SG_ 587 Checksum_BCM1_17 "V";
BA_ "GenSigInvalidValue" SG_ 587 BCM1_HandOffDetected_Left 3;
BA_ "GenSigInvalidValue" SG_ 587 BCM1_HandOffDetected_Right 3;
BA_ "GenSigInvalidValue" SG_ 587 BCM1_HandOffDetected_Back 3;
BA_ "GenSigInvalidRemark" SG_ 686 TBOXTime_Hour "23";
BA_ "GenSigStartRemark" SG_ 686 TBOXTime_Hour "23";
BA_ "GenSigInvalidValue" SG_ 686 TBOXTime_Hour 31;
BA_ "GenSigStartValue" SG_ 686 TBOXTime_Hour 30;
BA_ "GenSigInvalidRemark" SG_ 686 TBOXTime_Minute "59";
BA_ "GenSigStartRemark" SG_ 686 TBOXTime_Minute "59";
BA_ "GenSigInvalidValue" SG_ 686 TBOXTime_Minute 63;
BA_ "GenSigStartValue" SG_ 686 TBOXTime_Minute 62;
BA_ "GenSigInvalidRemark" SG_ 686 TBOXTime_Second "59";
BA_ "GenSigStartRemark" SG_ 686 TBOXTime_Second "59";
BA_ "GenSigInvalidValue" SG_ 686 TBOXTime_Second 63;
BA_ "GenSigStartValue" SG_ 686 TBOXTime_Second 62;
BA_ "GenSigInvalidRemark" SG_ 686 TBOXTime_Year "O";
BA_ "GenSigStartRemark" SG_ 686 TBOXTime_Year "O";
BA_ "GenSigInvalidValue" SG_ 686 TBOXTime_Year 127;
BA_ "GenSigStartValue" SG_ 686 TBOXTime_Year 126;
BA_ "GenSigInvalidRemark" SG_ 686 TBOXTime_Month "11";
BA_ "GenSigStartRemark" SG_ 686 TBOXTime_Month "11";
BA_ "GenSigInvalidValue" SG_ 686 TBOXTime_Month 15;
BA_ "GenSigStartValue" SG_ 686 TBOXTime_Month 14;
BA_ "GenSigInvalidRemark" SG_ 686 TBOXTime_Day "30";
BA_ "GenSigStartRemark" SG_ 686 TBOXTime_Day "30";
BA_ "GenSigInvalidValue" SG_ 686 TBOXTime_Day 127;
BA_ "GenSigStartValue" SG_ 686 TBOXTime_Day 126;
BA_ "GenSigInvalidRemark" SG_ 686 TBOXTime_Millisecond "1000";
BA_ "GenSigStartRemark" SG_ 686 TBOXTime_Millisecond "1000";
BA_ "GenSigInvalidValue" SG_ 686 TBOXTime_Millisecond 1023;
BA_ "GenSigStartValue" SG_ 686 TBOXTime_Millisecond 1022;
BA_REL_ "GenSigTimeoutTime" BU_SG_REL_ Gateway SG_ 617 Checksum_LCDAS_1 1000;
BA_REL_ "GenSigTimeoutTime" BU_SG_REL_ ADV SG_ 617 Checksum_LCDAS_1 1000;
BA_REL_ "GenSigTimeoutTime" BU_SG_REL_ LCDA1 SG_ 617 Checksum_LCDAS_1 1000;
BA_REL_ "GenSigTimeoutTime" BU_SG_REL_ ADV SG_ 617 LCDAS_ErrorSt_LCDAS 1000;
BA_REL_ "GenSigTimeoutTime" BU_SG_REL_ LCDA1 SG_ 617 LCDAS_WarningCmd_LCDAS_Left 1000;
BA_REL_ "GenSigTimeoutTime" BU_SG_REL_ LCDA1 SG_ 617 LCDAS_WarningCmd_RCTA_left 1000;
BA_REL_ "GenSigTimeoutTime" BU_SG_REL_ LCDA1 SG_ 617 LCDAS_WorkingSt_LCWBSD 1000;
BA_REL_ "GenSigTimeoutTime" BU_SG_REL_ LCDA1 SG_ 617 LCDAS_WorkingSt_RCTA 1000;
BA_REL_ "GenSigTimeoutTime" BU_SG_REL_ LCDA1 SG_ 617 LCDAS_WorkingSt_RCW 1000;
BA_REL_ "GenSigTimeoutTime" BU_SG_REL_ LCDA1 SG_ 617 LCDAS_WarningCmd_DOW_FL 1000;
BA_REL_ "GenSigTimeoutTime" BU_SG_REL_ LCDA1 SG_ 617 LCDAS_WarningCmd_DOW_RL 1000;
BA_REL_ "GenSigTimeoutTime" BU_SG_REL_ LCDA1 SG_ 617 LCDAS_WorkingSt_DOW 1000;
BA_REL_ "GenSigTimeoutTime" BU_SG_REL_ LCDA1 SG_ 617 LCDAS_WarningCmd_RCW 1000;
BA_REL_ "GenSigTimeoutTime" BU_SG_REL_ Gateway SG_ 617 LCDAS_Blockage_RL 1000;
BA_REL_ "GenSigTimeoutTime" BU_SG_REL_ ADV SG_ 617 LCDAS_Blockage_RL 1000;
BA_REL_ "GenSigTimeoutTime" BU_SG_REL_ ADV SG_ 617 LCDAS__BrakeReq_RCTB 1000;
BA_REL_ "GenSigTimeoutTime" BU_SG_REL_ LCDA1 SG_ 617 LCDAS__BrakeReq_RCTB 1000;
BA_REL_ "GenSigTimeoutTime" BU_SG_REL_ LCDA1 SG_ 617 LCDAS_WorkingSt_RCTB 1000;
BA_REL_ "GenSigTimeoutTime" BU_SG_REL_ ADV SG_ 617 LCDAS_MisAlign_status 1000;
BA_REL_ "GenSigTimeoutTime" BU_SG_REL_ Gateway SG_ 617 LiveCounter_LCDAS_1 1000;
BA_REL_ "GenSigTimeoutTime" BU_SG_REL_ ADV SG_ 617 LiveCounter_LCDAS_1 1000;
BA_REL_ "GenSigTimeoutTime" BU_SG_REL_ LCDA1 SG_ 617 LiveCounter_LCDAS_1 1000;
BA_REL_ "GenSigTimeoutTime" BU_SG_REL_ Gateway SG_ 620 Checksum_Fradar_1 1000;
BA_REL_ "GenSigTimeoutTime" BU_SG_REL_ AVP SG_ 620 Checksum_Fradar_1 1000;
BA_REL_ "GenSigTimeoutTime" BU_SG_REL_ AVP SG_ 620 Fradar_failure_status 1000;
BA_REL_ "GenSigTimeoutTime" BU_SG_REL_ Gateway SG_ 620 Fradar_Blockage_status 1000;
BA_REL_ "GenSigTimeoutTime" BU_SG_REL_ AVP SG_ 620 Fradar_Blockage_status 1000;
BA_REL_ "GenSigTimeoutTime" BU_SG_REL_ AVP SG_ 620 Fradar_MisAlign_status 1000;
BA_REL_ "GenSigTimeoutTime" BU_SG_REL_ Gateway SG_ 620 LiveCounter_Fradar_1 1000;
BA_REL_ "GenSigTimeoutTime" BU_SG_REL_ AVP SG_ 620 LiveCounter_Fradar_1 1000;
BA_REL_ "GenSigTimeoutTime" BU_SG_REL_ ADV SG_ 870 Checksum_RMradar_Obj1_4 500;
BA_REL_ "GenSigTimeoutTime" BU_SG_REL_ ADV SG_ 870 RMradar_Timestamp_Obj1_1 500;
BA_REL_ "GenSigTimeoutTime" BU_SG_REL_ ADV SG_ 870 LiveCounter_RMradar_Obj1_4 500;
BA_REL_ "GenSigTimeoutTime" BU_SG_REL_ ADV SG_ 864 Checksum_RMradar_Obj1_1 500;
BA_REL_ "GenSigTimeoutTime" BU_SG_REL_ ADV SG_ 864 RMradar_Obj1_Heading 500;
BA_REL_ "GenSigTimeoutTime" BU_SG_REL_ ADV SG_ 864 RMradar_Obj1_YSpeedRelative 500;
BA_REL_ "GenSigTimeoutTime" BU_SG_REL_ ADV SG_ 864 RMradar_Obj1_ID 500;
BA_REL_ "GenSigTimeoutTime" BU_SG_REL_ ADV SG_ 864 RMradar_Obj1_ValidFlag 500;
BA_REL_ "GenSigTimeoutTime" BU_SG_REL_ ADV SG_ 864 RMradar_Obj1_MotionPattern 500;
BA_REL_ "GenSigTimeoutTime" BU_SG_REL_ ADV SG_ 864 RMradar_Obj1_Type 500;
BA_REL_ "GenSigTimeoutTime" BU_SG_REL_ ADV SG_ 864 RMradar_Obj1_ExstProb 500;
BA_REL_ "GenSigTimeoutTime" BU_SG_REL_ ADV SG_ 864 RMradar_Obj1_Elev_Quality 500;
BA_REL_ "GenSigTimeoutTime" BU_SG_REL_ ADV SG_ 864 RMradar_Obj1_Classify_Quality 500;
BA_REL_ "GenSigTimeoutTime" BU_SG_REL_ ADV SG_ 864 RMradar_Obj1_CrossFlag 500;
BA_REL_ "GenSigTimeoutTime" BU_SG_REL_ ADV SG_ 864 RMradar_Obj1_MeasureSt 500;
BA_REL_ "GenSigTimeoutTime" BU_SG_REL_ ADV SG_ 864 RMradar_Obj1_ElevClass 500;
BA_REL_ "GenSigTimeoutTime" BU_SG_REL_ ADV SG_ 864 LiveCounter_RMradar_Obj1_1 500;
BA_REL_ "GenSigTimeoutTime" BU_SG_REL_ ADV SG_ 866 Checksum_RMradar_Obj1_2 500;
BA_REL_ "GenSigTimeoutTime" BU_SG_REL_ ADV SG_ 866 RMradar_Obj1_XAccRelative 500;
BA_REL_ "GenSigTimeoutTime" BU_SG_REL_ ADV SG_ 866 RMradar_Obj1_YAccRelative 500;
BA_REL_ "GenSigTimeoutTime" BU_SG_REL_ ADV SG_ 866 RMradar_Obj1_YPos_Near 500;
BA_REL_ "GenSigTimeoutTime" BU_SG_REL_ ADV SG_ 866 RMradar_Obj1_YPos_Left 500;
BA_REL_ "GenSigTimeoutTime" BU_SG_REL_ ADV SG_ 866 RMradar_Obj1_YPos_Right 500;
BA_REL_ "GenSigTimeoutTime" BU_SG_REL_ ADV SG_ 866 LiveCounter_RMradar_Obj1_2 500;
BA_REL_ "GenSigTimeoutTime" BU_SG_REL_ ADV SG_ 868 Checksum_RMradar_Obj1_3 500;
BA_REL_ "GenSigTimeoutTime" BU_SG_REL_ ADV SG_ 868 RMradar_Obj1_XSpeedRelative 500;
BA_REL_ "GenSigTimeoutTime" BU_SG_REL_ ADV SG_ 868 RMradar_Obj1_XPos_Near 500;
BA_REL_ "GenSigTimeoutTime" BU_SG_REL_ ADV SG_ 868 RMradar_Obj1_XPos_Left 500;
BA_REL_ "GenSigTimeoutTime" BU_SG_REL_ ADV SG_ 868 RMradar_Obj1_XPos_Right 500;
BA_REL_ "GenSigTimeoutTime" BU_SG_REL_ ADV SG_ 868 LiveCounter_RMradar_Obj1_3 500;
BA_REL_ "GenSigTimeoutTime" BU_SG_REL_ ADV SG_ 871 Checksum_RSradar_Obj1_4 500;
BA_REL_ "GenSigTimeoutTime" BU_SG_REL_ ADV SG_ 871 RSradar_Timestamp_Obj1_1 500;
BA_REL_ "GenSigTimeoutTime" BU_SG_REL_ ADV SG_ 871 LiveCounter_RSradar_Obj1_4 500;
BA_REL_ "GenSigTimeoutTime" BU_SG_REL_ ADV SG_ 865 Checksum_RSradar_Obj1_1 500;
BA_REL_ "GenSigTimeoutTime" BU_SG_REL_ ADV SG_ 865 RSradar_Obj1_Heading 500;
BA_REL_ "GenSigTimeoutTime" BU_SG_REL_ ADV SG_ 865 RSradar_Obj1_YSpeedRelative 500;
BA_REL_ "GenSigTimeoutTime" BU_SG_REL_ ADV SG_ 865 RSradar_Obj1_ID 500;
BA_REL_ "GenSigTimeoutTime" BU_SG_REL_ ADV SG_ 865 RSradar_Obj1_ValidFlag 500;
BA_REL_ "GenSigTimeoutTime" BU_SG_REL_ ADV SG_ 865 RSradar_Obj1_MotionPattern 500;
BA_REL_ "GenSigTimeoutTime" BU_SG_REL_ ADV SG_ 865 RSradar_Obj1_Type 500;
BA_REL_ "GenSigTimeoutTime" BU_SG_REL_ ADV SG_ 865 RSradar_Obj1_ExstProb 500;
BA_REL_ "GenSigTimeoutTime" BU_SG_REL_ ADV SG_ 865 RSradar_Obj1_Elev_Quality 500;
BA_REL_ "GenSigTimeoutTime" BU_SG_REL_ ADV SG_ 865 RSradar_Obj1_Classify_Quality 500;
BA_REL_ "GenSigTimeoutTime" BU_SG_REL_ ADV SG_ 865 RSradar_Obj1_CrossFlag 500;
BA_REL_ "GenSigTimeoutTime" BU_SG_REL_ ADV SG_ 865 RSradar_Obj1_MeasureSt 500;
BA_REL_ "GenSigTimeoutTime" BU_SG_REL_ ADV SG_ 865 RSradar_Obj1_ElevClass 500;
BA_REL_ "GenSigTimeoutTime" BU_SG_REL_ ADV SG_ 865 LiveCounter_RSradar_Obj1_1 500;
BA_REL_ "GenSigTimeoutTime" BU_SG_REL_ ADV SG_ 867 Checksum_RSradar_Obj1_2 500;
BA_REL_ "GenSigTimeoutTime" BU_SG_REL_ ADV SG_ 867 RSradar_Obj1_XAccRelative 500;
BA_REL_ "GenSigTimeoutTime" BU_SG_REL_ ADV SG_ 867 RSradar_Obj1_YAccRelative 500;
BA_REL_ "GenSigTimeoutTime" BU_SG_REL_ ADV SG_ 867 RSradar_Obj1_YPos_Near 500;
BA_REL_ "GenSigTimeoutTime" BU_SG_REL_ ADV SG_ 867 RSradar_Obj1_YPos_Left 500;
BA_REL_ "GenSigTimeoutTime" BU_SG_REL_ ADV SG_ 867 RSradar_Obj1_YPos_Right 500;
BA_REL_ "GenSigTimeoutTime" BU_SG_REL_ ADV SG_ 867 LiveCounter_RSradar_Obj1_2 500;
BA_REL_ "GenSigTimeoutTime" BU_SG_REL_ ADV SG_ 869 Checksum_RSradar_Obj1_3 500;
BA_REL_ "GenSigTimeoutTime" BU_SG_REL_ ADV SG_ 869 RSradar_Obj1_XSpeedRelative 500;
BA_REL_ "GenSigTimeoutTime" BU_SG_REL_ ADV SG_ 869 RSradar_Obj1_XPos_Near 500;
BA_REL_ "GenSigTimeoutTime" BU_SG_REL_ ADV SG_ 869 RSradar_Obj1_XPos_Left 500;
BA_REL_ "GenSigTimeoutTime" BU_SG_REL_ ADV SG_ 869 RSradar_Obj1_XPos_Right 500;
BA_REL_ "GenSigTimeoutTime" BU_SG_REL_ ADV SG_ 869 LiveCounter_RSradar_Obj1_3 500;
BA_REL_ "GenSigTimeoutTime" BU_SG_REL_ ADV SG_ 962 Checksum_RMradar_Free_1 500;
BA_REL_ "GenSigTimeoutTime" BU_SG_REL_ ADV SG_ 962 RMradar_FSP_Sector_01_Range 500;
BA_REL_ "GenSigTimeoutTime" BU_SG_REL_ ADV SG_ 962 RMradar_FSP_Sector_02_Range 500;
BA_REL_ "GenSigTimeoutTime" BU_SG_REL_ ADV SG_ 962 RMradar_FSP_Sector_03_Range 500;
BA_REL_ "GenSigTimeoutTime" BU_SG_REL_ ADV SG_ 962 RMradar_FSP_Sector_04_Range 500;
BA_REL_ "GenSigTimeoutTime" BU_SG_REL_ ADV SG_ 962 RMradar_FSP_Sector_05_Range 500;
BA_REL_ "GenSigTimeoutTime" BU_SG_REL_ ADV SG_ 962 RMradar_FSP_Sector_06_Range 500;
BA_REL_ "GenSigTimeoutTime" BU_SG_REL_ ADV SG_ 962 LiveCounter_RMradar_Free_1 500;
BA_REL_ "GenSigTimeoutTime" BU_SG_REL_ ADV SG_ 964 Checksum_RMradar_Free_2 500;
BA_REL_ "GenSigTimeoutTime" BU_SG_REL_ ADV SG_ 964 RMradar_FSP_Sector_07_Range 500;
BA_REL_ "GenSigTimeoutTime" BU_SG_REL_ ADV SG_ 964 RMradar_FSP_Sector_08_Range 500;
BA_REL_ "GenSigTimeoutTime" BU_SG_REL_ ADV SG_ 964 RMradar_FSP_Sector_09_Range 500;
BA_REL_ "GenSigTimeoutTime" BU_SG_REL_ ADV SG_ 964 RMradar_FSP_Sector_10_Range 500;
BA_REL_ "GenSigTimeoutTime" BU_SG_REL_ ADV SG_ 964 RMradar_FSP_Sector_11_Range 500;
BA_REL_ "GenSigTimeoutTime" BU_SG_REL_ ADV SG_ 964 RMradar_FSP_Sector_12_Range 500;
BA_REL_ "GenSigTimeoutTime" BU_SG_REL_ ADV SG_ 964 LiveCounter_RMradar_Free_2 500;
BA_REL_ "GenSigTimeoutTime" BU_SG_REL_ ADV SG_ 966 Checksum_RMradar_Free_3 500;
BA_REL_ "GenSigTimeoutTime" BU_SG_REL_ ADV SG_ 966 RMradar_FSP_Sector_13_Range 500;
BA_REL_ "GenSigTimeoutTime" BU_SG_REL_ ADV SG_ 966 RMradar_FSP_Sector_14_Range 500;
BA_REL_ "GenSigTimeoutTime" BU_SG_REL_ ADV SG_ 966 RMradar_FSP_Sector_15_Range 500;
BA_REL_ "GenSigTimeoutTime" BU_SG_REL_ ADV SG_ 966 RMradar_FSP_Sector_16_Range 500;
BA_REL_ "GenSigTimeoutTime" BU_SG_REL_ ADV SG_ 966 RMradar_FSP_Sector_17_Range 500;
BA_REL_ "GenSigTimeoutTime" BU_SG_REL_ ADV SG_ 966 RMradar_FSP_Sector_18_Range 500;
BA_REL_ "GenSigTimeoutTime" BU_SG_REL_ ADV SG_ 966 LiveCounter_RMradar_Free_3 500;
BA_REL_ "GenSigTimeoutTime" BU_SG_REL_ ADV SG_ 968 Checksum_RMradar_Free_4 500;
BA_REL_ "GenSigTimeoutTime" BU_SG_REL_ ADV SG_ 968 RMradar_FSP_Sector_19_Range 500;
BA_REL_ "GenSigTimeoutTime" BU_SG_REL_ ADV SG_ 968 RMradar_FSP_Sector_20_Range 500;
BA_REL_ "GenSigTimeoutTime" BU_SG_REL_ ADV SG_ 968 RMradar_FSP_Sector_21_Range 500;
BA_REL_ "GenSigTimeoutTime" BU_SG_REL_ ADV SG_ 968 RMradar_FSP_Sector_22_Range 500;
BA_REL_ "GenSigTimeoutTime" BU_SG_REL_ ADV SG_ 968 RMradar_FSP_Sector_23_Range 500;
BA_REL_ "GenSigTimeoutTime" BU_SG_REL_ ADV SG_ 968 RMradar_FSP_Sector_24_Range 500;
BA_REL_ "GenSigTimeoutTime" BU_SG_REL_ ADV SG_ 968 LiveCounter_RMradar_Free_4 500;
BA_REL_ "GenSigTimeoutTime" BU_SG_REL_ ADV SG_ 970 Checksum_RMradar_Free_5 500;
BA_REL_ "GenSigTimeoutTime" BU_SG_REL_ ADV SG_ 970 RMradar_FSP_Sector_25_Range 500;
BA_REL_ "GenSigTimeoutTime" BU_SG_REL_ ADV SG_ 970 RMradar_FSP_Sector_26_Range 500;
BA_REL_ "GenSigTimeoutTime" BU_SG_REL_ ADV SG_ 970 RMradar_FSP_Sector_27_Range 500;
BA_REL_ "GenSigTimeoutTime" BU_SG_REL_ ADV SG_ 970 RMradar_FSP_Sector_28_Range 500;
BA_REL_ "GenSigTimeoutTime" BU_SG_REL_ ADV SG_ 970 RMradar_FSP_Sector_29_Range 500;
BA_REL_ "GenSigTimeoutTime" BU_SG_REL_ ADV SG_ 970 RMradar_FSP_Sector_30_Range 500;
BA_REL_ "GenSigTimeoutTime" BU_SG_REL_ ADV SG_ 970 LiveCounter_RMradar_Free_5 500;
BA_REL_ "GenSigTimeoutTime" BU_SG_REL_ ADV SG_ 972 Checksum_RMradar_Free_6 500;
BA_REL_ "GenSigTimeoutTime" BU_SG_REL_ ADV SG_ 972 RMradar_FSP_Sector_31_Range 500;
BA_REL_ "GenSigTimeoutTime" BU_SG_REL_ ADV SG_ 972 RMradar_FSP_Sector_32_Range 500;
BA_REL_ "GenSigTimeoutTime" BU_SG_REL_ ADV SG_ 972 RMradar_FSP_Sector_33_Range 500;
BA_REL_ "GenSigTimeoutTime" BU_SG_REL_ ADV SG_ 972 RMradar_FSP_Sector_34_Range 500;
BA_REL_ "GenSigTimeoutTime" BU_SG_REL_ ADV SG_ 972 RMradar_FSP_Sector_35_Range 500;
BA_REL_ "GenSigTimeoutTime" BU_SG_REL_ ADV SG_ 972 LiveCounter_RMradar_Free_6 500;
BA_REL_ "GenSigTimeoutTime" BU_SG_REL_ ADV SG_ 963 Checksum_RSradar_Free_1 500;
BA_REL_ "GenSigTimeoutTime" BU_SG_REL_ ADV SG_ 963 RSradar_FSP_Sector_01_Range 500;
BA_REL_ "GenSigTimeoutTime" BU_SG_REL_ ADV SG_ 963 RSradar_FSP_Sector_02_Range 500;
BA_REL_ "GenSigTimeoutTime" BU_SG_REL_ ADV SG_ 963 RSradar_FSP_Sector_03_Range 500;
BA_REL_ "GenSigTimeoutTime" BU_SG_REL_ ADV SG_ 963 RSradar_FSP_Sector_04_Range 500;
BA_REL_ "GenSigTimeoutTime" BU_SG_REL_ ADV SG_ 963 RSradar_FSP_Sector_05_Range 500;
BA_REL_ "GenSigTimeoutTime" BU_SG_REL_ ADV SG_ 963 RSradar_FSP_Sector_06_Range 500;
BA_REL_ "GenSigTimeoutTime" BU_SG_REL_ ADV SG_ 963 LiveCounter_RSradar_Free_1 500;
BA_REL_ "GenSigTimeoutTime" BU_SG_REL_ ADV SG_ 965 Checksum_RSradar_Free_2 500;
BA_REL_ "GenSigTimeoutTime" BU_SG_REL_ ADV SG_ 965 RSradar_FSP_Sector_07_Range 500;
BA_REL_ "GenSigTimeoutTime" BU_SG_REL_ ADV SG_ 965 RSradar_FSP_Sector_08_Range 500;
BA_REL_ "GenSigTimeoutTime" BU_SG_REL_ ADV SG_ 965 RSradar_FSP_Sector_09_Range 500;
BA_REL_ "GenSigTimeoutTime" BU_SG_REL_ ADV SG_ 965 RSradar_FSP_Sector_10_Range 500;
BA_REL_ "GenSigTimeoutTime" BU_SG_REL_ ADV SG_ 965 RSradar_FSP_Sector_11_Range 500;
BA_REL_ "GenSigTimeoutTime" BU_SG_REL_ ADV SG_ 965 RSradar_FSP_Sector_12_Range 500;
BA_REL_ "GenSigTimeoutTime" BU_SG_REL_ ADV SG_ 965 LiveCounter_RSradar_Free_2 500;
BA_REL_ "GenSigTimeoutTime" BU_SG_REL_ ADV SG_ 975 Checksum_RSradar_Free_3 500;
BA_REL_ "GenSigTimeoutTime" BU_SG_REL_ ADV SG_ 975 RSradar_FSP_Sector_13_Range 500;
BA_REL_ "GenSigTimeoutTime" BU_SG_REL_ ADV SG_ 975 RSradar_FSP_Sector_14_Range 500;
BA_REL_ "GenSigTimeoutTime" BU_SG_REL_ ADV SG_ 975 RSradar_FSP_Sector_15_Range 500;
BA_REL_ "GenSigTimeoutTime" BU_SG_REL_ ADV SG_ 975 RSradar_FSP_Sector_16_Range 500;
BA_REL_ "GenSigTimeoutTime" BU_SG_REL_ ADV SG_ 975 RSradar_FSP_Sector_17_Range 500;
BA_REL_ "GenSigTimeoutTime" BU_SG_REL_ ADV SG_ 975 RSradar_FSP_Sector_18_Range 500;
BA_REL_ "GenSigTimeoutTime" BU_SG_REL_ ADV SG_ 975 LiveCounter_RSradar_Free_3 500;
BA_REL_ "GenSigTimeoutTime" BU_SG_REL_ ADV SG_ 969 Checksum_RSradar_Free_4 500;
BA_REL_ "GenSigTimeoutTime" BU_SG_REL_ ADV SG_ 969 RSradar_FSP_Sector_19_Range 500;
BA_REL_ "GenSigTimeoutTime" BU_SG_REL_ ADV SG_ 969 RSradar_FSP_Sector_20_Range 500;
BA_REL_ "GenSigTimeoutTime" BU_SG_REL_ ADV SG_ 969 RSradar_FSP_Sector_21_Range 500;
BA_REL_ "GenSigTimeoutTime" BU_SG_REL_ ADV SG_ 969 RSradar_FSP_Sector_22_Range 500;
BA_REL_ "GenSigTimeoutTime" BU_SG_REL_ ADV SG_ 969 RSradar_FSP_Sector_23_Range 500;
BA_REL_ "GenSigTimeoutTime" BU_SG_REL_ ADV SG_ 969 RSradar_FSP_Sector_24_Range 500;
BA_REL_ "GenSigTimeoutTime" BU_SG_REL_ ADV SG_ 969 LiveCounter_RSradar_Free_4 500;
BA_REL_ "GenSigTimeoutTime" BU_SG_REL_ ADV SG_ 971 Checksum_RSradar_Free_5 500;
BA_REL_ "GenSigTimeoutTime" BU_SG_REL_ ADV SG_ 971 RSradar_FSP_Sector_25_Range 500;
BA_REL_ "GenSigTimeoutTime" BU_SG_REL_ ADV SG_ 971 RSradar_FSP_Sector_26_Range 500;
BA_REL_ "GenSigTimeoutTime" BU_SG_REL_ ADV SG_ 971 RSradar_FSP_Sector_27_Range 500;
BA_REL_ "GenSigTimeoutTime" BU_SG_REL_ ADV SG_ 971 RSradar_FSP_Sector_28_Range 500;
BA_REL_ "GenSigTimeoutTime" BU_SG_REL_ ADV SG_ 971 RSradar_FSP_Sector_29_Range 500;
BA_REL_ "GenSigTimeoutTime" BU_SG_REL_ ADV SG_ 971 RSradar_FSP_Sector_30_Range 500;
BA_REL_ "GenSigTimeoutTime" BU_SG_REL_ ADV SG_ 971 LiveCounter_RSradar_Free_5 500;
BA_REL_ "GenSigTimeoutTime" BU_SG_REL_ ADV SG_ 973 Checksum_RSradar_Free_6 500;
BA_REL_ "GenSigTimeoutTime" BU_SG_REL_ ADV SG_ 973 RSradar_FSP_Sector_31_Range 500;
BA_REL_ "GenSigTimeoutTime" BU_SG_REL_ ADV SG_ 973 RSradar_FSP_Sector_32_Range 500;
BA_REL_ "GenSigTimeoutTime" BU_SG_REL_ ADV SG_ 973 RSradar_FSP_Sector_33_Range 500;
BA_REL_ "GenSigTimeoutTime" BU_SG_REL_ ADV SG_ 973 RSradar_FSP_Sector_34_Range 500;
BA_REL_ "GenSigTimeoutTime" BU_SG_REL_ ADV SG_ 973 RSradar_FSP_Sector_35_Range 500;
BA_REL_ "GenSigTimeoutTime" BU_SG_REL_ ADV SG_ 973 LiveCounter_RSradar_Free_6 500;
BA_REL_ "GenSigTimeoutTime" BU_SG_REL_ Gateway SG_ 602 Checksum_HAD_7 1000;
BA_REL_ "GenSigTimeoutTime" BU_SG_REL_ Gateway SG_ 602 HAD_SetMaxVehcleSpeedFunSt 1000;
BA_REL_ "GenSigTimeoutTime" BU_SG_REL_ Gateway SG_ 602 HAD_MaxVehcleSpeedSetted 1000;
BA_REL_ "GenSigTimeoutTime" BU_SG_REL_ Gateway SG_ 602 HAD_ChangeLaneAuto_Feedback 1000;
BA_REL_ "GenSigTimeoutTime" BU_SG_REL_ Gateway SG_ 602 HAD_RampSt_FR 1000;
BA_REL_ "GenSigTimeoutTime" BU_SG_REL_ Gateway SG_ 602 HAD_RampSt_FL 1000;
BA_REL_ "GenSigTimeoutTime" BU_SG_REL_ Gateway SG_ 602 HAD_GeoFenceAway 1000;
BA_REL_ "GenSigTimeoutTime" BU_SG_REL_ Gateway SG_ 602 HAD_TunnelSt_Ahead 1000;
BA_REL_ "GenSigTimeoutTime" BU_SG_REL_ Gateway SG_ 602 HAD_TollGateSt_Ahead 1000;
BA_REL_ "GenSigTimeoutTime" BU_SG_REL_ Gateway SG_ 602 HAD_RoadEnd_Ahead 1000;
BA_REL_ "GenSigTimeoutTime" BU_SG_REL_ Gateway SG_ 602 HAD_LaneEnd_Ahead 1000;
BA_REL_ "GenSigTimeoutTime" BU_SG_REL_ Gateway SG_ 602 HAD_Merge_Ahead 1000;
BA_REL_ "GenSigTimeoutTime" BU_SG_REL_ Gateway SG_ 602 HAD_AccidentsPotencial_Ahead 1000;
BA_REL_ "GenSigTimeoutTime" BU_SG_REL_ Gateway SG_ 602 HAD_RoadWork_Ahead 1000;
BA_REL_ "GenSigTimeoutTime" BU_SG_REL_ Gateway SG_ 602 HAD_LaneLineFade_Ahead 1000;
BA_REL_ "GenSigTimeoutTime" BU_SG_REL_ Gateway SG_ 602 HAD_RockfallPotencial_Ahead 1000;
BA_REL_ "GenSigTimeoutTime" BU_SG_REL_ Gateway SG_ 602 HAD_LaneLineCaptured_LL 1000;
BA_REL_ "GenSigTimeoutTime" BU_SG_REL_ Gateway SG_ 602 HAD_LaneLineCaptured_L 1000;
BA_REL_ "GenSigTimeoutTime" BU_SG_REL_ Gateway SG_ 602 HAD_LaneLineCaptured_RR 1000;
BA_REL_ "GenSigTimeoutTime" BU_SG_REL_ Gateway SG_ 602 HAD_LaneLineCaptured_R 1000;
BA_REL_ "GenSigTimeoutTime" BU_SG_REL_ Gateway SG_ 602 HAD_LaneLineType_LL 1000;
BA_REL_ "GenSigTimeoutTime" BU_SG_REL_ Gateway SG_ 602 HAD_LaneLineType_L 1000;
BA_REL_ "GenSigTimeoutTime" BU_SG_REL_ Gateway SG_ 602 HAD_LaneLineType_RR 1000;
BA_REL_ "GenSigTimeoutTime" BU_SG_REL_ Gateway SG_ 602 HAD_LaneLineType_R 1000;
BA_REL_ "GenSigTimeoutTime" BU_SG_REL_ Gateway SG_ 602 HAD_VehcleStatus_Ego 1000;
BA_REL_ "GenSigTimeoutTime" BU_SG_REL_ Gateway SG_ 602 LiveCounter_HAD_7 1000;
BA_REL_ "GenSigTimeoutTime" BU_SG_REL_ Gateway SG_ 603 Checksum_HAD_8 1000;
BA_REL_ "GenSigTimeoutTime" BU_SG_REL_ Gateway SG_ 603 HAD_VehcleStatus_Front 1000;
BA_REL_ "GenSigTimeoutTime" BU_SG_REL_ Gateway SG_ 603 HAD_VehcleStatus_Left 1000;
BA_REL_ "GenSigTimeoutTime" BU_SG_REL_ Gateway SG_ 603 HAD_VehcleStatus_Right 1000;
BA_REL_ "GenSigTimeoutTime" BU_SG_REL_ Gateway SG_ 603 HAD_VehcleStatus_FR 1000;
BA_REL_ "GenSigTimeoutTime" BU_SG_REL_ Gateway SG_ 603 HAD_VehcleStatus_FL 1000;
BA_REL_ "GenSigTimeoutTime" BU_SG_REL_ Gateway SG_ 603 HAD_VehcleStatus_RR 1000;
BA_REL_ "GenSigTimeoutTime" BU_SG_REL_ Gateway SG_ 603 HAD_VRU_FL 1000;
BA_REL_ "GenSigTimeoutTime" BU_SG_REL_ Gateway SG_ 603 HAD_VehcleStatus_RL 1000;
BA_REL_ "GenSigTimeoutTime" BU_SG_REL_ Gateway SG_ 603 HAD_LateralPosition_FrontVehcle 1000;
BA_REL_ "GenSigTimeoutTime" BU_SG_REL_ Gateway SG_ 603 HAD_VRU_FR 1000;
BA_REL_ "GenSigTimeoutTime" BU_SG_REL_ Gateway SG_ 603 HAD_LongitudinalPosition_FrontVe 1000;
BA_REL_ "GenSigTimeoutTime" BU_SG_REL_ Gateway SG_ 603 HAD_LateralPosition_FRVehcle 1000;
BA_REL_ "GenSigTimeoutTime" BU_SG_REL_ Gateway SG_ 603 HAD_VRU_Front 1000;
BA_REL_ "GenSigTimeoutTime" BU_SG_REL_ Gateway SG_ 603 HAD_LateralPosition_FLVehcle 1000;
BA_REL_ "GenSigTimeoutTime" BU_SG_REL_ Gateway SG_ 603 HAD_LateralPosition_LeftVehcle 1000;
BA_REL_ "GenSigTimeoutTime" BU_SG_REL_ Gateway SG_ 603 HAD_LateralPosition_RightVehcle 1000;
BA_REL_ "GenSigTimeoutTime" BU_SG_REL_ Gateway SG_ 603 LiveCounter_HAD_8 1000;
BA_REL_ "GenSigTimeoutTime" BU_SG_REL_ Gateway SG_ 606 Checksum_HAD_9 1000;
BA_REL_ "GenSigTimeoutTime" BU_SG_REL_ Gateway SG_ 606 HAD_LateralPosition_RLVehcle 1000;
BA_REL_ "GenSigTimeoutTime" BU_SG_REL_ Gateway SG_ 606 HAD_LateralPosition_RRVehcle 1000;
BA_REL_ "GenSigTimeoutTime" BU_SG_REL_ Gateway SG_ 606 HAD_FrontVehcle_CIPV 1000;
BA_REL_ "GenSigTimeoutTime" BU_SG_REL_ Gateway SG_ 606 HAD_FRVehcle_CIPV 1000;
BA_REL_ "GenSigTimeoutTime" BU_SG_REL_ Gateway SG_ 606 HAD_FLVehcle_CIPV 1000;
BA_REL_ "GenSigTimeoutTime" BU_SG_REL_ Gateway SG_ 606 HAD_LeftVehcle_CIPV 1000;
BA_REL_ "GenSigTimeoutTime" BU_SG_REL_ Gateway SG_ 606 HAD_RightVehcle_CIPV 1000;
BA_REL_ "GenSigTimeoutTime" BU_SG_REL_ Gateway SG_ 606 HAD_RRVehcle_CIPV 1000;
BA_REL_ "GenSigTimeoutTime" BU_SG_REL_ Gateway SG_ 606 HAD_RLVehcle_CIPV 1000;
BA_REL_ "GenSigTimeoutTime" BU_SG_REL_ Gateway SG_ 606 HAD_ErrorSt 1000;
BA_REL_ "GenSigTimeoutTime" BU_SG_REL_ Gateway SG_ 606 HAD_BrakeLightCtrlCmd 1000;
BA_REL_ "GenSigTimeoutTime" BU_SG_REL_ Gateway SG_ 606 HAD_LaneShap_Ego 1000;
BA_REL_ "GenSigTimeoutTime" BU_SG_REL_ Gateway SG_ 606 HAD_LaneShap_Left 1000;
BA_REL_ "GenSigTimeoutTime" BU_SG_REL_ Gateway SG_ 606 HAD_LowBeamReq 1000;
BA_REL_ "GenSigTimeoutTime" BU_SG_REL_ Gateway SG_ 606 HAD_LaneShap_Right 1000;
BA_REL_ "GenSigTimeoutTime" BU_SG_REL_ Gateway SG_ 606 HAD_LaneWidth_Ego 1000;
BA_REL_ "GenSigTimeoutTime" BU_SG_REL_ Gateway SG_ 606 HAD_HighBeamReq 1000;
BA_REL_ "GenSigTimeoutTime" BU_SG_REL_ Gateway SG_ 606 HAD_LaneWidth_Left 1000;
BA_REL_ "GenSigTimeoutTime" BU_SG_REL_ Gateway SG_ 606 HAD_LaneWidth_Right 1000;
BA_REL_ "GenSigTimeoutTime" BU_SG_REL_ Gateway SG_ 606 HAD_AbnormalRoadAttention 1000;
BA_REL_ "GenSigTimeoutTime" BU_SG_REL_ Gateway SG_ 606 HAD_KeepHandsOnTip 1000;
BA_REL_ "GenSigTimeoutTime" BU_SG_REL_ Gateway SG_ 606 HAD_ChangeLaneFunctionForbidden 1000;
BA_REL_ "GenSigTimeoutTime" BU_SG_REL_ Gateway SG_ 606 HAD_ChangeLaneAuto_ConfirmFuncSt 1000;
BA_REL_ "GenSigTimeoutTime" BU_SG_REL_ Gateway SG_ 606 HAD_DriverViewStatus_L3 1000;
BA_REL_ "GenSigTimeoutTime" BU_SG_REL_ Gateway SG_ 606 HAD_DriverHandsOnTip_L3 1000;
BA_REL_ "GenSigTimeoutTime" BU_SG_REL_ Gateway SG_ 606 HAD_AccelerationPedalApplied 1000;
BA_REL_ "GenSigTimeoutTime" BU_SG_REL_ Gateway SG_ 606 LiveCounter_HAD_9 1000;
BA_REL_ "GenSigTimeoutTime" BU_SG_REL_ CDS1 SG_ 667 Checksum_HU_10 1000;
BA_REL_ "GenSigTimeoutTime" BU_SG_REL_ ADV SG_ 667 Checksum_HU_10 1000;
BA_REL_ "GenSigTimeoutTime" BU_SG_REL_ PDC SG_ 667 Checksum_HU_10 1000;
BA_REL_ "GenSigTimeoutTime" BU_SG_REL_ LCDA1 SG_ 667 Checksum_HU_10 1000;
BA_REL_ "GenSigTimeoutTime" BU_SG_REL_ LCDA2 SG_ 667 Checksum_HU_10 1000;
BA_REL_ "GenSigTimeoutTime" BU_SG_REL_ CDS1 SG_ 667 HU_HWPTJPReq 1000;
BA_REL_ "GenSigTimeoutTime" BU_SG_REL_ CDS1 SG_ 667 HU_AVPFunctionReq 1000;
BA_REL_ "GenSigTimeoutTime" BU_SG_REL_ CDS1 SG_ 667 HU_ChangeLaneAuto_ConfirmFuncReq 1000;
BA_REL_ "GenSigTimeoutTime" BU_SG_REL_ CDS1 SG_ 667 FCWModeSet 1000;
BA_REL_ "GenSigTimeoutTime" BU_SG_REL_ CDS2 SG_ 667 FCWModeSet 1000;
BA_REL_ "GenSigTimeoutTime" BU_SG_REL_ CDS1 SG_ 667 HU_ChangeLaneManualFuncReq 1000;
BA_REL_ "GenSigTimeoutTime" BU_SG_REL_ CDS1 SG_ 667 HU_ChangeLaneAutoFuncReq 1000;
BA_REL_ "GenSigTimeoutTime" BU_SG_REL_ CDS1 SG_ 667 HU_SetMaxVehcleSpeedFuncReq 1000;
BA_REL_ "GenSigTimeoutTime" BU_SG_REL_ PDC SG_ 667 HU_PDCBuzzerReq 1000;
BA_REL_ "GenSigTimeoutTime" BU_SG_REL_ CDS1 SG_ 667 HU_MaxVehcleSpeed_Set 1000;
BA_REL_ "GenSigTimeoutTime" BU_SG_REL_ CDS1 SG_ 667 HU_LCDAFunctionReq 1000;
BA_REL_ "GenSigTimeoutTime" BU_SG_REL_ ADV SG_ 667 HU_LCDAFunctionReq 1000;
BA_REL_ "GenSigTimeoutTime" BU_SG_REL_ LCDA1 SG_ 667 HU_LCDAFunctionReq 1000;
BA_REL_ "GenSigTimeoutTime" BU_SG_REL_ LCDA2 SG_ 667 HU_LCDAFunctionReq 1000;
BA_REL_ "GenSigTimeoutTime" BU_SG_REL_ CDS1 SG_ 667 HU_RCWFunctionReq 1000;
BA_REL_ "GenSigTimeoutTime" BU_SG_REL_ ADV SG_ 667 HU_RCWFunctionReq 1000;
BA_REL_ "GenSigTimeoutTime" BU_SG_REL_ LCDA1 SG_ 667 HU_RCWFunctionReq 1000;
BA_REL_ "GenSigTimeoutTime" BU_SG_REL_ LCDA2 SG_ 667 HU_RCWFunctionReq 1000;
BA_REL_ "GenSigTimeoutTime" BU_SG_REL_ CDS1 SG_ 667 HU_FCTAFunctionReq 1000;
BA_REL_ "GenSigTimeoutTime" BU_SG_REL_ CDS1 SG_ 667 HU_RCTAFunctionReq 1000;
BA_REL_ "GenSigTimeoutTime" BU_SG_REL_ ADV SG_ 667 HU_RCTAFunctionReq 1000;
BA_REL_ "GenSigTimeoutTime" BU_SG_REL_ LCDA1 SG_ 667 HU_RCTAFunctionReq 1000;
BA_REL_ "GenSigTimeoutTime" BU_SG_REL_ LCDA2 SG_ 667 HU_RCTAFunctionReq 1000;
BA_REL_ "GenSigTimeoutTime" BU_SG_REL_ CDS1 SG_ 667 HU_RCTABuzzerWarningFunReq 1000;
BA_REL_ "GenSigTimeoutTime" BU_SG_REL_ ADV SG_ 667 HU_RCTABuzzerWarningFunReq 1000;
BA_REL_ "GenSigTimeoutTime" BU_SG_REL_ LCDA1 SG_ 667 HU_RCTABuzzerWarningFunReq 1000;
BA_REL_ "GenSigTimeoutTime" BU_SG_REL_ CDS1 SG_ 667 HU_DOWFunctionReq 1000;
BA_REL_ "GenSigTimeoutTime" BU_SG_REL_ ADV SG_ 667 HU_DOWFunctionReq 1000;
BA_REL_ "GenSigTimeoutTime" BU_SG_REL_ LCDA1 SG_ 667 HU_DOWFunctionReq 1000;
BA_REL_ "GenSigTimeoutTime" BU_SG_REL_ LCDA2 SG_ 667 HU_DOWFunctionReq 1000;
BA_REL_ "GenSigTimeoutTime" BU_SG_REL_ CDS1 SG_ 667 HU_FCTBFunctionReq 1000;
BA_REL_ "GenSigTimeoutTime" BU_SG_REL_ CDS1 SG_ 667 HU_RCTBFunctionReq 1000;
BA_REL_ "GenSigTimeoutTime" BU_SG_REL_ ADV SG_ 667 HU_RCTBFunctionReq 1000;
BA_REL_ "GenSigTimeoutTime" BU_SG_REL_ LCDA1 SG_ 667 HU_RCTBFunctionReq 1000;
BA_REL_ "GenSigTimeoutTime" BU_SG_REL_ LCDA2 SG_ 667 HU_RCTBFunctionReq 1000;
BA_REL_ "GenSigTimeoutTime" BU_SG_REL_ CDS1 SG_ 667 HU_DestinationtipReq 1000;
BA_REL_ "GenSigTimeoutTime" BU_SG_REL_ CDS1 SG_ 667 HU_AEBSensitivitySet 1000;
BA_REL_ "GenSigTimeoutTime" BU_SG_REL_ CDS2 SG_ 667 HU_AEBSensitivitySet 1000;
BA_REL_ "GenSigTimeoutTime" BU_SG_REL_ CDS1 SG_ 667 HU_SetDestinationFunReq 1000;
BA_REL_ "GenSigTimeoutTime" BU_SG_REL_ CDS1 SG_ 667 Livecounter_HU_10 1000;
BA_REL_ "GenSigTimeoutTime" BU_SG_REL_ ADV SG_ 667 Livecounter_HU_10 1000;
BA_REL_ "GenSigTimeoutTime" BU_SG_REL_ PDC SG_ 667 Livecounter_HU_10 1000;
BA_REL_ "GenSigTimeoutTime" BU_SG_REL_ LCDA1 SG_ 667 Livecounter_HU_10 1000;
BA_REL_ "GenSigTimeoutTime" BU_SG_REL_ LCDA2 SG_ 667 Livecounter_HU_10 1000;
BA_REL_ "GenSigTimeoutTime" BU_SG_REL_ CDS1 SG_ 576 PositionLightSt_RL 1000;
BA_REL_ "GenSigTimeoutTime" BU_SG_REL_ IRC SG_ 576 PositionLightSt_RL 1000;
BA_REL_ "GenSigTimeoutTime" BU_SG_REL_ CDS1 SG_ 576 PositionLightSt_RR 1000;
BA_REL_ "GenSigTimeoutTime" BU_SG_REL_ IRC SG_ 576 PositionLightSt_RR 1000;
BA_REL_ "GenSigTimeoutTime" BU_SG_REL_ CDS1 SG_ 576 FogLightSt_Rear 1000;
BA_REL_ "GenSigTimeoutTime" BU_SG_REL_ IRC SG_ 576 FogLightSt_Rear 1000;
BA_REL_ "GenSigTimeoutTime" BU_SG_REL_ CDS1 SG_ 576 FogLightSt_RL 1000;
BA_REL_ "GenSigTimeoutTime" BU_SG_REL_ IRC SG_ 576 FogLightSt_RL 1000;
BA_REL_ "GenSigTimeoutTime" BU_SG_REL_ CDS1 SG_ 576 FogLightSt_RR 1000;
BA_REL_ "GenSigTimeoutTime" BU_SG_REL_ IRC SG_ 576 FogLightSt_RR 1000;
BA_REL_ "GenSigTimeoutTime" BU_SG_REL_ CDS1 SG_ 576 FoglightFaultSt_Rear 1000;
BA_REL_ "GenSigTimeoutTime" BU_SG_REL_ IRC SG_ 576 FoglightFaultSt_Rear 1000;
BA_REL_ "GenSigTimeoutTime" BU_SG_REL_ IRC SG_ 576 ReverseLightSt 1000;
BA_REL_ "GenSigTimeoutTime" BU_SG_REL_ IRC SG_ 576 ReverseLightFaultSt 1000;
BA_REL_ "GenSigTimeoutTime" BU_SG_REL_ IRC SG_ 576 LicenseLightSt 1000;
BA_REL_ "GenSigTimeoutTime" BU_SG_REL_ IRC SG_ 576 LicenseLightFaultSt 1000;
BA_REL_ "GenSigTimeoutTime" BU_SG_REL_ IRC SG_ 576 BrakeLightFaultSt_RL 1000;
BA_REL_ "GenSigTimeoutTime" BU_SG_REL_ IRC SG_ 576 BrakeLightFaultSt_RR 1000;
BA_REL_ "GenSigTimeoutTime" BU_SG_REL_ CDS1 SG_ 576 TurnLightFaultSt_RL 1000;
BA_REL_ "GenSigTimeoutTime" BU_SG_REL_ IRC SG_ 576 TurnLightFaultSt_RL 1000;
BA_REL_ "GenSigTimeoutTime" BU_SG_REL_ CDS1 SG_ 576 TurnLightFaultSt_RR 1000;
BA_REL_ "GenSigTimeoutTime" BU_SG_REL_ IRC SG_ 576 TurnLightFaultSt_RR 1000;
BA_REL_ "GenSigTimeoutTime" BU_SG_REL_ CDS1 SG_ 576 WiperSt_Rear 1000;
BA_REL_ "GenSigTimeoutTime" BU_SG_REL_ IRC SG_ 576 WiperSt_Rear 1000;
BA_REL_ "GenSigTimeoutTime" BU_SG_REL_ CDS1 SG_ 576 PositionLightFaultSt_Rear 1000;
BA_REL_ "GenSigTimeoutTime" BU_SG_REL_ IRC SG_ 576 PositionLightFaultSt_Rear 1000;
BA_REL_ "GenSigTimeoutTime" BU_SG_REL_ CDS1 SG_ 576 BrakeLightSt_RL 1000;
BA_REL_ "GenSigTimeoutTime" BU_SG_REL_ IRC SG_ 576 BrakeLightSt_RL 1000;
BA_REL_ "GenSigTimeoutTime" BU_SG_REL_ CDS1 SG_ 576 BrakeLightSt_RR 1000;
BA_REL_ "GenSigTimeoutTime" BU_SG_REL_ IRC SG_ 576 BrakeLightSt_RR 1000;
BA_REL_ "GenSigTimeoutTime" BU_SG_REL_ AVP SG_ 737 FCP_AVSFunctionReq 1000;
BA_REL_ "GenSigTimeoutTime" BU_SG_REL_ AVM SG_ 737 FCP_AVSFunctionReq 1000;
BA_REL_ "GenSigTimeoutTime" BU_SG_REL_ PDC SG_ 737 FCP_PDCFunctionReq 1000;
BA_REL_ "GenSigTimeoutTime" BU_SG_REL_ ADV SG_ 737 FCP_APAFunctionReq 1000;
BA_REL_ "GenSigTimeoutTime" BU_SG_REL_ ADV SG_ 737 FCP_AVPFunctionReq 1000;
BA_REL_ "GenSigTimeoutTime" BU_SG_REL_ Gateway SG_ 434 Checksum_IFC_7 1000;
BA_REL_ "GenSigTimeoutTime" BU_SG_REL_ Gateway SG_ 434 RelDstFrtCarXb 1000;
BA_REL_ "GenSigTimeoutTime" BU_SG_REL_ Gateway SG_ 434 RelDstFrtCarYb 1000;
BA_REL_ "GenSigTimeoutTime" BU_SG_REL_ Gateway SG_ 434 RelSpdFrtCar 1000;
BA_REL_ "GenSigTimeoutTime" BU_SG_REL_ Gateway SG_ 434 HeiFrtCar 1000;
BA_REL_ "GenSigTimeoutTime" BU_SG_REL_ Gateway SG_ 434 LaneChangeSt 1000;
BA_REL_ "GenSigTimeoutTime" BU_SG_REL_ Gateway SG_ 434 TargetVehicleChangeSt 1000;
BA_REL_ "GenSigTimeoutTime" BU_SG_REL_ Gateway SG_ 434 TypeFrtCar 1000;
BA_REL_ "GenSigTimeoutTime" BU_SG_REL_ Gateway SG_ 434 LiveCounter_IFC_7 1000;
BA_REL_ "GenSigTimeoutTime" BU_SG_REL_ Gateway SG_ 435 Checksum_IFC_8 1000;
BA_REL_ "GenSigTimeoutTime" BU_SG_REL_ Gateway SG_ 435 RelDstFLCarXb 1000;
BA_REL_ "GenSigTimeoutTime" BU_SG_REL_ Gateway SG_ 435 RelSpdFLCar 1000;
BA_REL_ "GenSigTimeoutTime" BU_SG_REL_ Gateway SG_ 435 RelDstFLCarYb 1000;
BA_REL_ "GenSigTimeoutTime" BU_SG_REL_ Gateway SG_ 435 LiveCounter_IFC_8 1000;
BA_REL_ "GenSigTimeoutTime" BU_SG_REL_ Gateway SG_ 436 Checksum_IFC_9 1000;
BA_REL_ "GenSigTimeoutTime" BU_SG_REL_ Gateway SG_ 436 RelDstFRCarXb 1000;
BA_REL_ "GenSigTimeoutTime" BU_SG_REL_ Gateway SG_ 436 RelSpdFRCar 1000;
BA_REL_ "GenSigTimeoutTime" BU_SG_REL_ Gateway SG_ 436 RelDstFRCarYb 1000;
BA_REL_ "GenSigTimeoutTime" BU_SG_REL_ Gateway SG_ 436 LiveCounter_IFC_9 1000;
BA_REL_ "GenSigTimeoutTime" BU_SG_REL_ Gateway SG_ 437 Checksum_IFC_10 1000;
BA_REL_ "GenSigTimeoutTime" BU_SG_REL_ Gateway SG_ 437 RelDstLttCarXd 1000;
BA_REL_ "GenSigTimeoutTime" BU_SG_REL_ Gateway SG_ 437 RelSpdLttCar 1000;
BA_REL_ "GenSigTimeoutTime" BU_SG_REL_ Gateway SG_ 437 RelDstLttCarYd 1000;
BA_REL_ "GenSigTimeoutTime" BU_SG_REL_ Gateway SG_ 437 LiveCounter_IFC_10 1000;
BA_REL_ "GenSigTimeoutTime" BU_SG_REL_ Gateway SG_ 601 Checksum_HAD_12 1000;
BA_REL_ "GenSigTimeoutTime" BU_SG_REL_ AVP SG_ 601 Checksum_HAD_12 1000;
BA_REL_ "GenSigTimeoutTime" BU_SG_REL_ DSM SG_ 601 Checksum_HAD_12 1000;
BA_REL_ "GenSigTimeoutTime" BU_SG_REL_ Gateway SG_ 601 HAD_DataRecordReq_HWPTJP_DVR 1000;
BA_REL_ "GenSigTimeoutTime" BU_SG_REL_ Gateway SG_ 601 HAD_DataRecordReq_AVP_DVR 1000;
BA_REL_ "GenSigTimeoutTime" BU_SG_REL_ Gateway SG_ 601 HAD_DataRecordReq_HWPTJP_GW 1000;
BA_REL_ "GenSigTimeoutTime" BU_SG_REL_ Gateway SG_ 601 HAD_DataRecordReq_AVP_GW 1000;
BA_REL_ "GenSigTimeoutTime" BU_SG_REL_ AVP SG_ 601 HAD_DataRecordReq_HWPTJP_AVS 1000;
BA_REL_ "GenSigTimeoutTime" BU_SG_REL_ AVP SG_ 601 HAD_DataRecordReq_AVP_AVS 1000;
BA_REL_ "GenSigTimeoutTime" BU_SG_REL_ DSM SG_ 601 HAD_DataRecordReq_HWPTJP_DSM 1000;
BA_REL_ "GenSigTimeoutTime" BU_SG_REL_ Gateway SG_ 601 HAD_DataRecordTriggerEvent 1000;
BA_REL_ "GenSigTimeoutTime" BU_SG_REL_ AVP SG_ 601 HAD_DataRecordTriggerEvent 1000;
BA_REL_ "GenSigTimeoutTime" BU_SG_REL_ DSM SG_ 601 HAD_DataRecordTriggerEvent 1000;
BA_REL_ "GenSigTimeoutTime" BU_SG_REL_ Gateway SG_ 601 HAD_DataRecordConfiguration 1000;
BA_REL_ "GenSigTimeoutTime" BU_SG_REL_ Gateway SG_ 601 HAD_DataRecordCounter 1000;
BA_REL_ "GenSigTimeoutTime" BU_SG_REL_ AVP SG_ 601 HAD_DataRecordCounter 1000;
BA_REL_ "GenSigTimeoutTime" BU_SG_REL_ DSM SG_ 601 HAD_DataRecordCounter 1000;
BA_REL_ "GenSigTimeoutTime" BU_SG_REL_ Gateway SG_ 601 LiveCounter_HAD_12 1000;
BA_REL_ "GenSigTimeoutTime" BU_SG_REL_ AVP SG_ 601 LiveCounter_HAD_12 1000;
BA_REL_ "GenSigTimeoutTime" BU_SG_REL_ DSM SG_ 601 LiveCounter_HAD_12 1000;
BA_REL_ "GenSigTimeoutTime" BU_SG_REL_ CDS1 SG_ 422 CruiseMainSwitch 500;
BA_REL_ "GenSigTimeoutTime" BU_SG_REL_ CDS2 SG_ 422 CruiseMainSwitch 500;
BA_REL_ "GenSigTimeoutTime" BU_SG_REL_ ADV SG_ 422 CruiseMainSwitch 500;
BA_REL_ "GenSigTimeoutTime" BU_SG_REL_ CDS1 SG_ 422 CruiseCancelSwitch 500;
BA_REL_ "GenSigTimeoutTime" BU_SG_REL_ CDS2 SG_ 422 CruiseCancelSwitch 500;
BA_REL_ "GenSigTimeoutTime" BU_SG_REL_ ADV SG_ 422 CruiseCancelSwitch 500;
BA_REL_ "GenSigTimeoutTime" BU_SG_REL_ CDS1 SG_ 422 SetOrDecreaseSpeedSwitch 500;
BA_REL_ "GenSigTimeoutTime" BU_SG_REL_ CDS2 SG_ 422 SetOrDecreaseSpeedSwitch 500;
BA_REL_ "GenSigTimeoutTime" BU_SG_REL_ ADV SG_ 422 SetOrDecreaseSpeedSwitch 500;
BA_REL_ "GenSigTimeoutTime" BU_SG_REL_ CDS1 SG_ 422 ResumeOIncreaseSpeedSwitch 500;
BA_REL_ "GenSigTimeoutTime" BU_SG_REL_ CDS2 SG_ 422 ResumeOIncreaseSpeedSwitch 500;
BA_REL_ "GenSigTimeoutTime" BU_SG_REL_ ADV SG_ 422 ResumeOIncreaseSpeedSwitch 500;
BA_REL_ "GenSigTimeoutTime" BU_SG_REL_ CDS1 SG_ 422 IncreaseDistanceSwitch 500;
BA_REL_ "GenSigTimeoutTime" BU_SG_REL_ CDS2 SG_ 422 IncreaseDistanceSwitch 500;
BA_REL_ "GenSigTimeoutTime" BU_SG_REL_ ADV SG_ 422 IncreaseDistanceSwitch 500;
BA_REL_ "GenSigTimeoutTime" BU_SG_REL_ CDS1 SG_ 422 DecreaseDistanceSwitch 500;
BA_REL_ "GenSigTimeoutTime" BU_SG_REL_ CDS2 SG_ 422 DecreaseDistanceSwitch 500;
BA_REL_ "GenSigTimeoutTime" BU_SG_REL_ ADV SG_ 422 DecreaseDistanceSwitch 500;
BA_REL_ "GenSigTimeoutTime" BU_SG_REL_ CDS1 SG_ 422 CruiseSwitchErrorSt 500;
BA_REL_ "GenSigTimeoutTime" BU_SG_REL_ CDS2 SG_ 422 CruiseSwitchErrorSt 500;
BA_REL_ "GenSigTimeoutTime" BU_SG_REL_ ADV SG_ 422 CruiseSwitchErrorSt 500;
BA_REL_ "GenSigTimeoutTime" BU_SG_REL_ CDS1 SG_ 520 HCU_BatteryPackSOC 1000;
BA_REL_ "GenSigTimeoutTime" BU_SG_REL_ ADV SG_ 755 BLEKeyLocation 1000;
BA_REL_ "GenSigTimeoutTime" BU_SG_REL_ ADV SG_ 755 Livecounter_BLE_1 1000;
BA_REL_ "GenSigTimeoutTime" BU_SG_REL_ AVP SG_ 672 CheckSum_TBOX_1 1000;
BA_REL_ "GenSigTimeoutTime" BU_SG_REL_ AVM SG_ 672 CheckSum_TBOX_1 1000;
BA_REL_ "GenSigTimeoutTime" BU_SG_REL_ AVP SG_ 672 RemoteMonitoringReq 1000;
BA_REL_ "GenSigTimeoutTime" BU_SG_REL_ AVM SG_ 672 RemoteMonitoringReq 1000;
BA_REL_ "GenSigTimeoutTime" BU_SG_REL_ AVP SG_ 672 VehicleDraggingAlert 1000;
BA_REL_ "GenSigTimeoutTime" BU_SG_REL_ AVP SG_ 672 RemoteAVSSharpnessReq 1000;
BA_REL_ "GenSigTimeoutTime" BU_SG_REL_ AVM SG_ 672 RemoteAVSSharpnessReq 1000;
BA_REL_ "GenSigTimeoutTime" BU_SG_REL_ AVP SG_ 672 RemoteAVSViewModeReq 1000;
BA_REL_ "GenSigTimeoutTime" BU_SG_REL_ AVM SG_ 672 RemoteAVSViewModeReq 1000;
BA_REL_ "GenSigTimeoutTime" BU_SG_REL_ AVP SG_ 672 LiveCounter_TBOX_1 1000;
BA_REL_ "GenSigTimeoutTime" BU_SG_REL_ AVM SG_ 672 LiveCounter_TBOX_1 1000;
BA_REL_ "GenSigTimeoutTime" BU_SG_REL_ CDS1 SG_ 519 HCU_WOBCEnquiry 1000;
BA_REL_ "GenSigTimeoutTime" BU_SG_REL_ ADV SG_ 519 HCU_WOBCEnquiry 1000;
BA_REL_ "GenSigTimeoutTime" BU_SG_REL_ CDS1 SG_ 519 HCU_WOBCChargerStatus 1000;
BA_REL_ "GenSigTimeoutTime" BU_SG_REL_ ADV SG_ 519 HCU_WOBCChargerStatus 1000;
BA_REL_ "GenSigTimeoutTime" BU_SG_REL_ PDC SG_ 519 HCU_WOBCChargerStatus 1000;
BA_REL_ "GenSigTimeoutTime" BU_SG_REL_ CDS1 SG_ 519 HCU_ChargerStatus 1000;
BA_REL_ "GenSigTimeoutTime" BU_SG_REL_ ADV SG_ 519 HCU_ChargerStatus 1000;
BA_REL_ "GenSigTimeoutTime" BU_SG_REL_ CDS1 SG_ 519 HCU_ChargeConnectStatus 1000;
BA_REL_ "GenSigTimeoutTime" BU_SG_REL_ ADV SG_ 519 HCU_ChargeConnectStatus 1000;
BA_REL_ "GenSigTimeoutTime" BU_SG_REL_ CDS1 SG_ 519 HCU_Status 1000;
BA_REL_ "GenSigTimeoutTime" BU_SG_REL_ ADV SG_ 519 HCU_Status 1000;
BA_REL_ "GenSigTimeoutTime" BU_SG_REL_ ADV SG_ 733 Checksum_WOBC_2 1000;
BA_REL_ "GenSigTimeoutTime" BU_SG_REL_ ADV SG_ 733 WOBC_ContrapositionPosition_X 1000;
BA_REL_ "GenSigTimeoutTime" BU_SG_REL_ ADV SG_ 733 WOBC_ContrapositionPosition_Y 1000;
BA_REL_ "GenSigTimeoutTime" BU_SG_REL_ ADV SG_ 733 WOBC_ContrapositionAngle 1000;
BA_REL_ "GenSigTimeoutTime" BU_SG_REL_ ADV SG_ 733 LiveCounter_WOBC_2 1000;
BA_REL_ "GenSigTimeoutTime" BU_SG_REL_ ADV SG_ 732 Checksum_WOBC_1 1000;
BA_REL_ "GenSigTimeoutTime" BU_SG_REL_ AVP SG_ 732 WOBC_WorkingStatus 1000;
BA_REL_ "GenSigTimeoutTime" BU_SG_REL_ AVM SG_ 732 WOBC_WorkingStatus 1000;
BA_REL_ "GenSigTimeoutTime" BU_SG_REL_ ADV SG_ 732 WOBC_ContrapositionStatus 1000;
BA_REL_ "GenSigTimeoutTime" BU_SG_REL_ ADV SG_ 732 LiveCounter_WOBC_1 1000;
BA_REL_ "GenSigTimeoutTime" BU_SG_REL_ ADB1 SG_ 566 CeremonyModeInd 1000;
BA_REL_ "GenSigTimeoutTime" BU_SG_REL_ ADB2 SG_ 566 CeremonyModeInd 1000;
BA_REL_ "GenSigTimeoutTime" BU_SG_REL_ DSM SG_ 644 AccountID_IVI 1000;
BA_REL_ "GenSigTimeoutTime" BU_SG_REL_ DSM SG_ 644 AccountBindFaceReq 1000;
BA_REL_ "GenSigTimeoutTime" BU_SG_REL_ ADV SG_ 657 DisplayTheme 1000;
BA_REL_ "GenSigTimeoutTime" BU_SG_REL_ AVP SG_ 657 DisplayTheme 1000;
BA_REL_ "GenSigTimeoutTime" BU_SG_REL_ AVM SG_ 657 DisplayTheme 1000;
BA_REL_ "GenSigTimeoutTime" BU_SG_REL_ CDS1 SG_ 587 Checksum_BCM1_17 1000;
BA_REL_ "GenSigTimeoutTime" BU_SG_REL_ ADV SG_ 587 Checksum_BCM1_17 1000;
BA_REL_ "GenSigTimeoutTime" BU_SG_REL_ CDS1 SG_ 587 BCM_RemoteParkoutReq_AVP 1000;
BA_REL_ "GenSigTimeoutTime" BU_SG_REL_ ADV SG_ 587 BCM_RemoteParkoutReq_AVP 1000;
BA_REL_ "GenSigTimeoutTime" BU_SG_REL_ CDS1 SG_ 587 BCM_RemoteParkoutReq_HPA 1000;
BA_REL_ "GenSigTimeoutTime" BU_SG_REL_ ADV SG_ 587 BCM_RemoteParkoutReq_HPA 1000;
BA_REL_ "GenSigTimeoutTime" BU_SG_REL_ CDS1 SG_ 587 BCM_RemoteParkoutReq_RPA 1000;
BA_REL_ "GenSigTimeoutTime" BU_SG_REL_ ADV SG_ 587 BCM_RemoteParkoutReq_RPA 1000;
BA_REL_ "GenSigTimeoutTime" BU_SG_REL_ CDS1 SG_ 587 BCM_RemoteParkMonitorModeSt 1000;
BA_REL_ "GenSigTimeoutTime" BU_SG_REL_ ADV SG_ 587 BCM_RemoteParkMonitorModeSt 1000;
BA_REL_ "GenSigTimeoutTime" BU_SG_REL_ CDS1 SG_ 587 BCM_IGIndication_RemotePark 1000;
BA_REL_ "GenSigTimeoutTime" BU_SG_REL_ ADV SG_ 587 BCM_IGIndication_RemotePark 1000;
BA_REL_ "GenSigTimeoutTime" BU_SG_REL_ CDS1 SG_ 587 BCM1_HODError 1000;
BA_REL_ "GenSigTimeoutTime" BU_SG_REL_ CDS2 SG_ 587 BCM1_HODError 1000;
BA_REL_ "GenSigTimeoutTime" BU_SG_REL_ CDS1 SG_ 587 BCM1_HandOffDetected_Left 1000;
BA_REL_ "GenSigTimeoutTime" BU_SG_REL_ CDS2 SG_ 587 BCM1_HandOffDetected_Left 1000;
BA_REL_ "GenSigTimeoutTime" BU_SG_REL_ CDS1 SG_ 587 BCM1_HandOffDetected_Right 1000;
BA_REL_ "GenSigTimeoutTime" BU_SG_REL_ CDS2 SG_ 587 BCM1_HandOffDetected_Right 1000;
BA_REL_ "GenSigTimeoutTime" BU_SG_REL_ CDS1 SG_ 587 BCM1_HandOffDetected_Back 1000;
BA_REL_ "GenSigTimeoutTime" BU_SG_REL_ CDS2 SG_ 587 BCM1_HandOffDetected_Back 1000;
BA_REL_ "GenSigTimeoutTime" BU_SG_REL_ CDS1 SG_ 587 LiveCounter_BCM1_17 1000;
BA_REL_ "GenSigTimeoutTime" BU_SG_REL_ ADV SG_ 587 LiveCounter_BCM1_17 1000;
BA_REL_ "GenSigTimeoutTime" BU_SG_REL_ AVP SG_ 686 TBOXTime_Hour 1000;
BA_REL_ "GenSigTimeoutTime" BU_SG_REL_ DSM SG_ 686 TBOXTime_Hour 1000;
BA_REL_ "GenSigTimeoutTime" BU_SG_REL_ AVP SG_ 686 TBOXTime_Minute 1000;
BA_REL_ "GenSigTimeoutTime" BU_SG_REL_ DSM SG_ 686 TBOXTime_Minute 1000;
BA_REL_ "GenSigTimeoutTime" BU_SG_REL_ AVP SG_ 686 TBOXTime_Second 1000;
BA_REL_ "GenSigTimeoutTime" BU_SG_REL_ DSM SG_ 686 TBOXTime_Second 1000;
BA_REL_ "GenSigTimeoutTime" BU_SG_REL_ AVP SG_ 686 TBOXTime_Year 1000;
BA_REL_ "GenSigTimeoutTime" BU_SG_REL_ DSM SG_ 686 TBOXTime_Year 1000;
BA_REL_ "GenSigTimeoutTime" BU_SG_REL_ AVP SG_ 686 TBOXTime_Month 1000;
BA_REL_ "GenSigTimeoutTime" BU_SG_REL_ DSM SG_ 686 TBOXTime_Month 1000;
BA_REL_ "GenSigTimeoutTime" BU_SG_REL_ AVP SG_ 686 TBOXTime_Day 1000;
BA_REL_ "GenSigTimeoutTime" BU_SG_REL_ DSM SG_ 686 TBOXTime_Day 1000;
BA_REL_ "GenSigTimeoutTime" BU_SG_REL_ AVP SG_ 686 TBOXTime_Millisecond 1000;
BA_REL_ "GenSigTimeoutTime" BU_SG_REL_ DSM SG_ 686 TBOXTime_Millisecond 1000;
VAL_ 617 LCDAS_ErrorSt_LCDAS 1 "Error" 0 "No error" ;
VAL_ 617 LCDAS_WarningCmd_LCDAS_Left 3 "Reserved" 2 "Warning level 2" 1 "Warning level 1" 0 "Inactive" ;
VAL_ 617 LCDAS_WarningCmd_RCTA_left 3 "Reserved" 2 "Warning level 2" 1 "Warning level 1" 0 "Inactive" ;
VAL_ 617 LCDAS_WorkingSt_LCWBSD 3 "Failure" 2 "Active" 1 "Passive" 0 "Off" ;
VAL_ 617 LCDAS_WorkingSt_RCTA 3 "Failure" 2 "Active" 1 "Passive" 0 "Off" ;
VAL_ 617 LCDAS_WorkingSt_RCW 3 "Failure" 2 "Active" 1 "Passive" 0 "Off" ;
VAL_ 617 LCDAS_WarningCmd_DOW_FL 3 "Reserved" 2 "Warning level 2" 1 "Warning level 1" 0 "Inactive" ;
VAL_ 617 LCDAS_WarningCmd_DOW_RL 3 "Reserved" 2 "Warning level 2" 1 "Warning level 1" 0 "Inactive" ;
VAL_ 617 LCDAS_WorkingSt_DOW 3 "Failure" 2 "Active" 1 "Passive" 0 "Off" ;
VAL_ 617 LCDAS_WarningCmd_RCW 3 "Reserved" 2 "Warning level 2" 1 "Warning level 1" 0 "Inactive" ;
VAL_ 617 LCDAS_Blockage_RL 1 "Blockage" 0 "No Blockage" ;
VAL_ 617 LCDAS__BrakeReq_RCTB 1 "Brake Request" 0 "No Request" ;
VAL_ 617 LCDAS_WorkingSt_RCTB 3 "Failure" 2 "Active" 1 "Passive" 0 "Off" ;
VAL_ 617 LCDAS_MisAlign_status 3 "Reserved" 2 "sensor misalignment detected " 1 "sensor calibrated" 0 "sensor not calibrated" ;
VAL_ 620 Fradar_failure_status 1 "Error" 0 "No Error" ;
VAL_ 620 Fradar_Blockage_status 1 "Blockage" 0 "No blockage" ;
VAL_ 620 Fradar_MisAlign_status 3 "Reserved" 2 "sensor misalignment detected " 1 "sensor calibrated" 0 "sensor not calibrated" ;
VAL_ 870 RMradar_Timestamp_Obj1_1 65535 "SNA" ;
VAL_ 864 RMradar_Obj1_Heading 255 "SNA" ;
VAL_ 864 RMradar_Obj1_YSpeedRelative 511 "SNA" ;
VAL_ 864 RMradar_Obj1_ValidFlag 1 "Valid" 0 "Invalid" ;
VAL_ 864 RMradar_Obj1_MotionPattern 3 "Moving" 2 "Stopped" 1 "Stationary" 0 "Unknown" ;
VAL_ 864 RMradar_Obj1_Type 7 "Reserved" 6 "Reserved" 5 "Truck" 4 "Car" 3 "Pedestrian" 2 "2 wheeler" 1 "4 wheeler" 0 "Unknown" ;
VAL_ 864 RMradar_Obj1_ExstProb 31 "SNA" ;
VAL_ 864 RMradar_Obj1_Elev_Quality 3 "High Quality" 2 "Medium Quality" 1 "Low Quality" 0 "No Quality" ;
VAL_ 864 RMradar_Obj1_Classify_Quality 31 "SNA" ;
VAL_ 864 RMradar_Obj1_CrossFlag 1 "Cross" 0 "No Cross" ;
VAL_ 864 RMradar_Obj1_MeasureSt 3 "Reserved" 2 "Speculative" 1 "Measure Object" 0 "Unknown" ;
VAL_ 864 RMradar_Obj1_ElevClass 3 "Relevant" 2 "Overridable" 1 "Underrunnable" 0 "Unknown" ;
VAL_ 866 RMradar_Obj1_XAccRelative 255 "SNA" ;
VAL_ 866 RMradar_Obj1_YAccRelative 255 "SNA" ;
VAL_ 866 RMradar_Obj1_YPos_Near 4095 "SNA" ;
VAL_ 866 RMradar_Obj1_YPos_Left 4095 "SNA" ;
VAL_ 866 RMradar_Obj1_YPos_Right 4095 "SNA" ;
VAL_ 868 RMradar_Obj1_XSpeedRelative 1023 "SNA" ;
VAL_ 868 RMradar_Obj1_XPos_Near 4095 "SNA" ;
VAL_ 868 RMradar_Obj1_XPos_Left 4095 "SNA" ;
VAL_ 868 RMradar_Obj1_XPos_Right 4095 "SNA" ;
VAL_ 871 RSradar_Timestamp_Obj1_1 65535 "SNA" ;
VAL_ 865 RSradar_Obj1_Heading 255 "SNA" ;
VAL_ 865 RSradar_Obj1_YSpeedRelative 511 "SNA" ;
VAL_ 865 RSradar_Obj1_ValidFlag 1 "Valid" 0 "Invalid" ;
VAL_ 865 RSradar_Obj1_MotionPattern 3 "Moving" 2 "Stopped" 1 "Stationary" 0 "Unknown" ;
VAL_ 865 RSradar_Obj1_Type 7 "Reserved" 6 "Reserved" 5 "Truck" 4 "Car" 3 "Pedestrian" 2 "2 wheeler" 1 "4 wheeler" 0 "Unknown" ;
VAL_ 865 RSradar_Obj1_ExstProb 31 "SNA" ;
VAL_ 865 RSradar_Obj1_Elev_Quality 3 "High Quality" 2 "Medium Quality" 1 "Low Quality" 0 "No Quality" ;
VAL_ 865 RSradar_Obj1_Classify_Quality 31 "SNA" ;
VAL_ 865 RSradar_Obj1_CrossFlag 1 "Cross" 0 "No Cross" ;
VAL_ 865 RSradar_Obj1_MeasureSt 3 "Reserved" 2 "Speculative" 1 "Measure Object" 0 "Unknown" ;
VAL_ 865 RSradar_Obj1_ElevClass 3 "Relevant" 2 "Overridable" 1 "Underrunnable" 0 "Unknown" ;
VAL_ 867 RSradar_Obj1_XAccRelative 255 "SNA" ;
VAL_ 867 RSradar_Obj1_YAccRelative 255 "SNA" ;
VAL_ 867 RSradar_Obj1_YPos_Near 4095 "SNA" ;
VAL_ 867 RSradar_Obj1_YPos_Left 4095 "SNA" ;
VAL_ 867 RSradar_Obj1_YPos_Right 4095 "SNA" ;
VAL_ 869 RSradar_Obj1_XSpeedRelative 1023 "SNA" ;
VAL_ 869 RSradar_Obj1_XPos_Near 4095 "SNA" ;
VAL_ 869 RSradar_Obj1_XPos_Left 4095 "SNA" ;
VAL_ 869 RSradar_Obj1_XPos_Right 4095 "SNA" ;
VAL_ 962 RMradar_FSP_Sector_01_Range 255 "SNA" ;
VAL_ 962 RMradar_FSP_Sector_02_Range 255 "SNA" ;
VAL_ 962 RMradar_FSP_Sector_03_Range 255 "SNA" ;
VAL_ 962 RMradar_FSP_Sector_04_Range 255 "SNA" ;
VAL_ 962 RMradar_FSP_Sector_05_Range 255 "SNA" ;
VAL_ 962 RMradar_FSP_Sector_06_Range 255 "SNA" ;
VAL_ 964 RMradar_FSP_Sector_07_Range 255 "SNA" ;
VAL_ 964 RMradar_FSP_Sector_08_Range 255 "SNA" ;
VAL_ 964 RMradar_FSP_Sector_09_Range 255 "SNA" ;
VAL_ 964 RMradar_FSP_Sector_10_Range 255 "SNA" ;
VAL_ 964 RMradar_FSP_Sector_11_Range 255 "SNA" ;
VAL_ 964 RMradar_FSP_Sector_12_Range 255 "SNA" ;
VAL_ 966 RMradar_FSP_Sector_13_Range 255 "SNA" ;
VAL_ 966 RMradar_FSP_Sector_14_Range 255 "SNA" ;
VAL_ 966 RMradar_FSP_Sector_15_Range 255 "SNA" ;
VAL_ 966 RMradar_FSP_Sector_16_Range 255 "SNA" ;
VAL_ 966 RMradar_FSP_Sector_17_Range 255 "SNA" ;
VAL_ 966 RMradar_FSP_Sector_18_Range 255 "SNA" ;
VAL_ 968 RMradar_FSP_Sector_19_Range 255 "SNA" ;
VAL_ 968 RMradar_FSP_Sector_20_Range 255 "SNA" ;
VAL_ 968 RMradar_FSP_Sector_21_Range 255 "SNA" ;
VAL_ 968 RMradar_FSP_Sector_22_Range 255 "SNA" ;
VAL_ 968 RMradar_FSP_Sector_23_Range 255 "SNA" ;
VAL_ 968 RMradar_FSP_Sector_24_Range 255 "SNA" ;
VAL_ 970 RMradar_FSP_Sector_25_Range 255 "SNA" ;
VAL_ 970 RMradar_FSP_Sector_26_Range 255 "SNA" ;
VAL_ 970 RMradar_FSP_Sector_27_Range 255 "SNA" ;
VAL_ 970 RMradar_FSP_Sector_28_Range 255 "SNA" ;
VAL_ 970 RMradar_FSP_Sector_29_Range 255 "SNA" ;
VAL_ 970 RMradar_FSP_Sector_30_Range 255 "SNA" ;
VAL_ 972 RMradar_FSP_Sector_31_Range 255 "SNA" ;
VAL_ 972 RMradar_FSP_Sector_32_Range 255 "SNA" ;
VAL_ 972 RMradar_FSP_Sector_33_Range 255 "SNA" ;
VAL_ 972 RMradar_FSP_Sector_34_Range 255 "SNA" ;
VAL_ 972 RMradar_FSP_Sector_35_Range 255 "SNA" ;
VAL_ 963 RSradar_FSP_Sector_01_Range 255 "SNA" ;
VAL_ 963 RSradar_FSP_Sector_02_Range 255 "SNA" ;
VAL_ 963 RSradar_FSP_Sector_03_Range 255 "SNA" ;
VAL_ 963 RSradar_FSP_Sector_04_Range 255 "SNA" ;
VAL_ 963 RSradar_FSP_Sector_05_Range 255 "SNA" ;
VAL_ 963 RSradar_FSP_Sector_06_Range 255 "SNA" ;
VAL_ 965 RSradar_FSP_Sector_07_Range 255 "SNA" ;
VAL_ 965 RSradar_FSP_Sector_08_Range 255 "SNA" ;
VAL_ 965 RSradar_FSP_Sector_09_Range 255 "SNA" ;
VAL_ 965 RSradar_FSP_Sector_10_Range 255 "SNA" ;
VAL_ 965 RSradar_FSP_Sector_11_Range 255 "SNA" ;
VAL_ 965 RSradar_FSP_Sector_12_Range 255 "SNA" ;
VAL_ 975 RSradar_FSP_Sector_13_Range 255 "SNA" ;
VAL_ 975 RSradar_FSP_Sector_14_Range 255 "SNA" ;
VAL_ 975 RSradar_FSP_Sector_15_Range 255 "SNA" ;
VAL_ 975 RSradar_FSP_Sector_16_Range 255 "SNA" ;
VAL_ 975 RSradar_FSP_Sector_17_Range 255 "SNA" ;
VAL_ 975 RSradar_FSP_Sector_18_Range 255 "SNA" ;
VAL_ 969 RSradar_FSP_Sector_19_Range 255 "SNA" ;
VAL_ 969 RSradar_FSP_Sector_20_Range 255 "SNA" ;
VAL_ 969 RSradar_FSP_Sector_21_Range 255 "SNA" ;
VAL_ 969 RSradar_FSP_Sector_22_Range 255 "SNA" ;
VAL_ 969 RSradar_FSP_Sector_23_Range 255 "SNA" ;
VAL_ 969 RSradar_FSP_Sector_24_Range 255 "SNA" ;
VAL_ 971 RSradar_FSP_Sector_25_Range 255 "SNA" ;
VAL_ 971 RSradar_FSP_Sector_26_Range 255 "SNA" ;
VAL_ 971 RSradar_FSP_Sector_27_Range 255 "SNA" ;
VAL_ 971 RSradar_FSP_Sector_28_Range 255 "SNA" ;
VAL_ 971 RSradar_FSP_Sector_29_Range 255 "SNA" ;
VAL_ 971 RSradar_FSP_Sector_30_Range 255 "SNA" ;
VAL_ 973 RSradar_FSP_Sector_31_Range 255 "SNA" ;
VAL_ 973 RSradar_FSP_Sector_32_Range 255 "SNA" ;
VAL_ 973 RSradar_FSP_Sector_33_Range 255 "SNA" ;
VAL_ 973 RSradar_FSP_Sector_34_Range 255 "SNA" ;
VAL_ 973 RSradar_FSP_Sector_35_Range 255 "SNA" ;
VAL_ 602 HAD_SetMaxVehcleSpeedFunSt 1 "ON" 0 "OFF" ;
VAL_ 602 HAD_MaxVehcleSpeedSetted 31 "SNA" ;
VAL_ 602 HAD_ChangeLaneAuto_Feedback 7 "Reserved" 6 "Reserved" 5 "Reserved" 4 "Right lane change has been canceled for some reason" 3 "Left lane change has been canceled for some reason" 2 "The car is changing to rightt lane" 1 "The car is changing to left lane" 0 "Inactive" ;
VAL_ 602 HAD_RampSt_FR 1 "Exist" 0 "Not Exist" ;
VAL_ 602 HAD_RampSt_FL 1 "Exist" 0 "Not Exist" ;
VAL_ 602 HAD_GeoFenceAway 1 "The car will drive away the Geographical fence" 0 "Inactive" ;
VAL_ 602 HAD_TunnelSt_Ahead 1 "Exist" 0 "Not Exist" ;
VAL_ 602 HAD_TollGateSt_Ahead 1 "Exist" 0 "Not Exist" ;
VAL_ 602 HAD_RoadEnd_Ahead 1 "Road is end ahead " 0 "Inactive" ;
VAL_ 602 HAD_LaneEnd_Ahead 1 "Ego lane is end ahead " 0 "Inactive" ;
VAL_ 602 HAD_Merge_Ahead 1 "Merging point is ahead " 0 "Inactive" ;
VAL_ 602 HAD_AccidentsPotencial_Ahead 1 "Accidents potencial road section" 0 "Inactive" ;
VAL_ 602 HAD_RoadWork_Ahead 1 "Road work ahead" 0 "Inactive" ;
VAL_ 602 HAD_LaneLineFade_Ahead 1 "Lne line fade" 0 "Inactive" ;
VAL_ 602 HAD_RockfallPotencial_Ahead 1 "Rockfall potencial road section" 0 "Inactive" ;
VAL_ 602 HAD_LaneLineCaptured_LL 1 "Captured" 0 "Not captured" ;
VAL_ 602 HAD_LaneLineCaptured_L 1 "Captured" 0 "Not captured" ;
VAL_ 602 HAD_LaneLineCaptured_RR 1 "Captured" 0 "Not captured" ;
VAL_ 602 HAD_LaneLineCaptured_R 1 "Captured" 0 "Not captured" ;
VAL_ 602 HAD_LaneLineType_LL 7 "Reserved" 6 "Shoulder edge" 5 "Median" 4 "Double imaginary line " 3 "Double full line" 2 "Single imaginary line " 1 "Single full line" 0 "Inactive" ;
VAL_ 602 HAD_LaneLineType_L 7 "Reserved" 6 "Shoulder edge" 5 "Median" 4 "Double imaginary line " 3 "Double full line" 2 "Single imaginary line " 1 "Single full line" 0 "Inactive" ;
VAL_ 602 HAD_LaneLineType_RR 7 "Reserved" 6 "Shoulder edge" 5 "Median" 4 "Double imaginary line " 3 "Double full line" 2 "Single imaginary line " 1 "Single full line" 0 "Inactive" ;
VAL_ 602 HAD_LaneLineType_R 7 "Reserved" 6 "Shoulder edge" 5 "Median" 4 "Double imaginary line " 3 "Double full line" 2 "Single imaginary line " 1 "Single full line" 0 "Inactive" ;
VAL_ 602 HAD_VehcleStatus_Ego 15 "Reserved" 14 "Reserved" 13 "Reserved" 12 "Reserved" 11 "Standstill" 10 "Right hidden" 9 "Left hidden" 8 "Lost stability" 7 "Avoidance" 6 "Lane change failed" 5 "Changing lane" 4 "EPB autohold" 3 "Emergency deceleration" 2 "Normal driving" 1 "Drive off" 0 "Inactive" ;
VAL_ 603 HAD_VehcleStatus_Front 7 "Other" 6 "Motorbike" 5 "Bus" 4 "Truck(JieFang)" 3 "Truck" 2 "Car(HongQi)" 1 "Car" 0 "No Vehcle" ;
VAL_ 603 HAD_VehcleStatus_Left 7 "Other" 6 "Motorbike" 5 "Bus" 4 "Truck(JieFang)" 3 "Truck" 2 "Car(HongQi)" 1 "Car" 0 "No Vehcle" ;
VAL_ 603 HAD_VehcleStatus_Right 7 "Other" 6 "Motorbike" 5 "Bus" 4 "Truck(JieFang)" 3 "Truck" 2 "Car(HongQi)" 1 "Car" 0 "No Vehcle" ;
VAL_ 603 HAD_VehcleStatus_FR 7 "Other" 6 "Motorbike" 5 "Bus" 4 "Truck(JieFang)" 3 "Truck" 2 "Car(HongQi)" 1 "Car" 0 "No Vehcle" ;
VAL_ 603 HAD_VehcleStatus_FL 7 "Other" 6 "Motorbike" 5 "Bus" 4 "Truck(JieFang)" 3 "Truck" 2 "Car(HongQi)" 1 "Car" 0 "No Vehcle" ;
VAL_ 603 HAD_VehcleStatus_RR 7 "Other" 6 "Motorbike" 5 "Bus" 4 "Truck(JieFang)" 3 "Truck" 2 "Car(HongQi)" 1 "Car" 0 "No Vehcle" ;
VAL_ 603 HAD_VRU_FL 3 "Reserved" 2 "Bicycle" 1 "Pedestrian" 0 "No VRU" ;
VAL_ 603 HAD_VehcleStatus_RL 7 "Other" 6 "Motorbike" 5 "Bus" 4 "Truck(JieFang)" 3 "Truck" 2 "Car(HongQi)" 1 "Car" 0 "No Vehcle" ;
VAL_ 603 HAD_LateralPosition_FrontVehcle 7 "Reserved" 6 "Reserved" 5 "Position5" 4 "Position4" 3 "Position3" 2 "Position2" 1 "Position1" 0 "Inactive" ;
VAL_ 603 HAD_VRU_FR 3 "Reserved" 2 "Bicycle" 1 "Pedestrian" 0 "No VRU" ;
VAL_ 603 HAD_LongitudinalPosition_FrontVe 7 "Reserved" 6 "Reserved" 5 "Reserved" 4 "Position4" 3 "Position3" 2 "Position2" 1 "Position1" 0 "Inactive" ;
VAL_ 603 HAD_LateralPosition_FRVehcle 7 "Reserved" 6 "Reserved" 5 "Position5" 4 "Position4" 3 "Position3" 2 "Position2" 1 "Position1" 0 "Inactive" ;
VAL_ 603 HAD_VRU_Front 3 "Reserved" 2 "Bicycle" 1 "Pedestrian" 0 "No VRU" ;
VAL_ 603 HAD_LateralPosition_FLVehcle 7 "Reserved" 6 "Reserved" 5 "Position5" 4 "Position4" 3 "Position3" 2 "Position2" 1 "Position1" 0 "Inactive" ;
VAL_ 603 HAD_LateralPosition_LeftVehcle 7 "Reserved" 6 "Reserved" 5 "Position5" 4 "Position4" 3 "Position3" 2 "Position2" 1 "Position1" 0 "Inactive" ;
VAL_ 603 HAD_LateralPosition_RightVehcle 7 "Reserved" 6 "Reserved" 5 "Position5" 4 "Position4" 3 "Position3" 2 "Position2" 1 "Position1" 0 "Inactive" ;
VAL_ 606 HAD_LateralPosition_RLVehcle 7 "Reserved" 6 "Reserved" 5 "Position5" 4 "Position4" 3 "Position3" 2 "Position2" 1 "Position1" 0 "Inactive" ;
VAL_ 606 HAD_LateralPosition_RRVehcle 7 "Reserved" 6 "Reserved" 5 "Position5" 4 "Position4" 3 "Position3" 2 "Position2" 1 "Position1" 0 "Inactive" ;
VAL_ 606 HAD_FrontVehcle_CIPV 1 "Yes" 0 "No" ;
VAL_ 606 HAD_FRVehcle_CIPV 1 "Yes" 0 "No" ;
VAL_ 606 HAD_FLVehcle_CIPV 1 "Yes" 0 "No" ;
VAL_ 606 HAD_LeftVehcle_CIPV 1 "Yes" 0 "No" ;
VAL_ 606 HAD_RightVehcle_CIPV 1 "Yes" 0 "No" ;
VAL_ 606 HAD_RRVehcle_CIPV 1 "Yes" 0 "No" ;
VAL_ 606 HAD_RLVehcle_CIPV 1 "Yes" 0 "No" ;
VAL_ 606 HAD_ErrorSt 1 "Error" 0 "No error" ;
VAL_ 606 HAD_BrakeLightCtrlCmd 1 "Illuminate" 0 "Not illuminate" ;
VAL_ 606 HAD_LaneShap_Ego 7 "Reserved" 6 "Reserved" 5 "Reserved" 4 "Big curve_Right" 3 "Big curve_Left" 2 "Normal curve_Right" 1 "Normal curve_Left" 0 "Straight" ;
VAL_ 606 HAD_LaneShap_Left 7 "Reserved" 6 "Reserved" 5 "Reserved" 4 "Big curve_Right" 3 "Big curve_Left" 2 "Normal curve_Right" 1 "Normal curve_Left" 0 "Straight" ;
VAL_ 606 HAD_LowBeamReq 3 "Reserved" 2 "On" 1 "Off" 0 "No Request" ;
VAL_ 606 HAD_LaneShap_Right 7 "Reserved" 6 "Reserved" 5 "Reserved" 4 "Big curve_Right" 3 "Big curve_Left" 2 "Normal curve_Right" 1 "Normal curve_Left" 0 "Straight" ;
VAL_ 606 HAD_LaneWidth_Ego 7 "Reserved" 6 "Reserved" 5 "Reserved" 4 "Narrow down_Right" 3 "Narrow down_Left" 2 "Wider_Right" 1 "Wider_Left" 0 "Normal" ;
VAL_ 606 HAD_HighBeamReq 3 "Reserved" 2 "On" 1 "Off" 0 "No Request" ;
VAL_ 606 HAD_LaneWidth_Left 7 "Reserved" 6 "Reserved" 5 "Reserved" 4 "Narrow down_Right" 3 "Narrow down_Left" 2 "Wider_Right" 1 "Wider_Left" 0 "Normal" ;
VAL_ 606 HAD_LaneWidth_Right 7 "Reserved" 6 "Reserved" 5 "Reserved" 4 "Narrow down_Right" 3 "Narrow down_Left" 2 "Wider_Right" 1 "Wider_Left" 0 "Normal" ;
VAL_ 606 HAD_AbnormalRoadAttention 15 "Please pay attention to the road condition" 14 "Reserved" 13 "Reserved" 12 "Reserved" 11 "Reserved" 10 "Please pay attention to the road condition" 9 "Forward confluence" 8 "Forward fork" 7 "Animal infestation section" 6 "Rockfall-prone section" 5 "Accident-prone section" 4 "Non-closed road " 3 "Tunnel ahead" 2 "On the ramp ahead" 1 "Consolidation point ahead" 0 "Inactive" ;
VAL_ 606 HAD_KeepHandsOnTip 7 "Reserved" 6 "Reserved" 5 "Reserved" 4 "Reserved" 3 "Reserved" 2 "Visual field is not clear,hold the steering wheel please" 1 "Approaching the tuunel,hold the steering wheel please" 0 "Inactive" ;
VAL_ 606 HAD_ChangeLaneFunctionForbidden 1 "Active" 0 "Inactive" ;
VAL_ 606 HAD_ChangeLaneAuto_ConfirmFuncSt 1 "ON" 0 "Off" ;
VAL_ 606 HAD_DriverViewStatus_L3 1 "Abnormal" 0 "Normal" ;
VAL_ 606 HAD_DriverHandsOnTip_L3 1 "Hands on" 0 "Hands off" ;
VAL_ 606 HAD_AccelerationPedalApplied 1 "Applied" 0 "Not applied" ;
VAL_ 667 HU_HWPTJPReq 3 "Reserved" 2 "On" 1 "Off" 0 "Inactive" ;
VAL_ 667 HU_AVPFunctionReq 3 "Reserved" 2 "On" 1 "Off" 0 "Inactive" ;
VAL_ 667 HU_ChangeLaneAuto_ConfirmFuncReq 3 "Reserved" 2 "On" 1 "Off" 0 "Inactive" ;
VAL_ 667 FCWModeSet 3 "FCW+AEB" 2 "Reserved" 1 "FCW only" 0 "Inactive" ;
VAL_ 667 HU_ChangeLaneManualFuncReq 3 "Reserved" 2 "On" 1 "Off" 0 "Inactive" ;
VAL_ 667 HU_ChangeLaneAutoFuncReq 3 "Reserved" 2 "On" 1 "Off" 0 "Inactive" ;
VAL_ 667 HU_SetMaxVehcleSpeedFuncReq 3 "Reserved" 2 "On" 1 "Off" 0 "Inactive" ;
VAL_ 667 HU_PDCBuzzerReq 3 "Reserved" 2 "On" 1 "Off" 0 "Inactive" ;
VAL_ 667 HU_MaxVehcleSpeed_Set 31 "SNA" ;
VAL_ 667 HU_LCDAFunctionReq 3 "Reserved" 2 "On" 1 "Off" 0 "Inactive" ;
VAL_ 667 HU_RCWFunctionReq 3 "Reserved" 2 "On" 1 "Off" 0 "Inactive" ;
VAL_ 667 HU_FCTAFunctionReq 3 "Reserved" 2 "On" 1 "Off" 0 "Inactive" ;
VAL_ 667 HU_RCTAFunctionReq 3 "Reserved" 2 "On" 1 "Off" 0 "Inactive" ;
VAL_ 667 HU_RCTABuzzerWarningFunReq 3 "Reserved" 2 "On" 1 "Off" 0 "Inactive" ;
VAL_ 667 HU_DOWFunctionReq 3 "Reserved" 2 "On" 1 "Off" 0 "Inactive" ;
VAL_ 667 HU_FCTBFunctionReq 3 "Reserved" 2 "On" 1 "Off" 0 "Inactive" ;
VAL_ 667 HU_RCTBFunctionReq 3 "Reserved" 2 "On" 1 "Off" 0 "Inactive" ;
VAL_ 667 HU_DestinationtipReq 3 "Reserved" 2 "On" 1 "Off" 0 "Inactive" ;
VAL_ 667 HU_AEBSensitivitySet 3 "High" 2 "Normal" 1 "Low" 0 "Inactive" ;
VAL_ 667 HU_SetDestinationFunReq 3 "Reserved" 2 "On" 1 "Off" 0 "Inactive" ;
VAL_ 576 PositionLightSt_RL 1 "On" 0 "Off" ;
VAL_ 576 PositionLightSt_RR 1 "On" 0 "Off" ;
VAL_ 576 FogLightSt_Rear 1 "On" 0 "Off" ;
VAL_ 576 FogLightSt_RL 1 "On" 0 "Off" ;
VAL_ 576 FogLightSt_RR 1 "On" 0 "Off" ;
VAL_ 576 FoglightFaultSt_Rear 1 "Fault" 0 "No fault" ;
VAL_ 576 ReverseLightSt 1 "On" 0 "Off" ;
VAL_ 576 ReverseLightFaultSt 1 "Fault" 0 "No fault" ;
VAL_ 576 LicenseLightSt 1 "On" 0 "Off" ;
VAL_ 576 LicenseLightFaultSt 1 "Fault" 0 "No fault" ;
VAL_ 576 BrakeLightFaultSt_RL 1 "Fault" 0 "No fault" ;
VAL_ 576 BrakeLightFaultSt_RR 1 "Fault" 0 "No fault" ;
VAL_ 576 TurnLightFaultSt_RL 1 "Fault" 0 "No fault" ;
VAL_ 576 TurnLightFaultSt_RR 1 "Fault" 0 "No fault" ;
VAL_ 576 WashSysSt_Rear 1 "On" 0 "Off" ;
VAL_ 576 RearWindowHeatingStatus 1 "Active" 0 "Inactive" ;
VAL_ 576 WiperSt_Rear 1 "On" 0 "Off" ;
VAL_ 576 PositionLightFaultSt_Rear 1 "Fault" 0 "No fault" ;
VAL_ 576 BrakeLightSt_RL 1 "On" 0 "Off" ;
VAL_ 576 BrakeLightSt_RR 1 "On" 0 "Off" ;
VAL_ 737 FCP_AVSFunctionReq 3 "Reserved" 2 "On" 1 "Off" 0 "Inactive" ;
VAL_ 737 FCP_PDCFunctionReq 3 "Reserved" 2 "On" 1 "Off" 0 "Inactive" ;
VAL_ 737 FCP_APAFunctionReq 3 "Reserved" 2 "On" 1 "Off" 0 "Inactive" ;
VAL_ 737 FCP_AVPFunctionReq 3 "Reserved" 2 "On" 1 "Off" 0 "Inactive" ;
VAL_ 434 LaneChangeSt 1 "Lane Change" 0 "No Lane Change" ;
VAL_ 434 TargetVehicleChangeSt 1 "Traget Vehicle Change" 0 "No Traget Vehicle Change" ;
VAL_ 434 TypeFrtCar 15 "Reserved" 14 "Reserved" 13 "Reserved" 12 "Reserved" 11 "Reserved" 10 "Reserved" 9 "Reserved" 8 "Uncertain Vehicle" 7 "Animal" 6 "General Object" 5 "Pedestrian" 4 "Bicycle" 3 "Motorbike" 2 "Truck" 1 "Car" 0 "Invalid" ;
VAL_ 601 HAD_DataRecordReq_HWPTJP_DVR 3 "Reserved" 2 "On" 1 "Off" 0 "No Request" ;
VAL_ 601 HAD_DataRecordReq_AVP_DVR 3 "Reserved" 2 "On" 1 "Off" 0 "No Request" ;
VAL_ 601 HAD_DataRecordReq_HWPTJP_GW 3 "Reserved" 2 "On" 1 "Off" 0 "No Request" ;
VAL_ 601 HAD_DataRecordReq_AVP_GW 3 "Reserved" 2 "On" 1 "Off" 0 "No Request" ;
VAL_ 601 HAD_DataRecordReq_HWPTJP_AVS 3 "Reserved" 2 "On" 1 "Off" 0 "No Request" ;
VAL_ 601 HAD_DataRecordReq_AVP_AVS 3 "Reserved" 2 "On" 1 "Off" 0 "No Request" ;
VAL_ 601 HAD_DataRecordReq_HWPTJP_DSM 3 "Reserved" 2 "On" 1 "Off" 0 "No Request" ;
VAL_ 601 HAD_DataRecordTriggerEvent 7 "Reserved" 6 "Reserved" 5 "HWP/TJP emergency brake" 4 "HWP/TJP takeover tip" 3 "HWP/TJP longitudinal override" 2 "HWP/TJP lateral override" 1 "AVP parking" 0 "Inactive" ;
VAL_ 601 HAD_DataRecordConfiguration 7 "Reserved" 6 "Reserved" 5 "Reserved" 4 "No Video" 3 "No AVP Video" 2 "No DSM Video" 1 "Only Chassis2 and ADAS CAN" 0 "All" ;
VAL_ 422 CruiseMainSwitch 1 "Pressed" 0 "Not pressed" ;
VAL_ 422 CruiseCancelSwitch 1 "Pressed" 0 "Not pressed" ;
VAL_ 422 SetOrDecreaseSpeedSwitch 1 "Pressed" 0 "Not pressed" ;
VAL_ 422 ResumeOIncreaseSpeedSwitch 1 "Pressed" 0 "Not pressed" ;
VAL_ 422 IncreaseDistanceSwitch 1 "Pressed" 0 "Not pressed" ;
VAL_ 422 DecreaseDistanceSwitch 1 "Pressed" 0 "Not pressed" ;
VAL_ 422 CruiseSwitchErrorSt 1 "Error" 0 "No Error" ;
VAL_ 520 HCU_BatteryPackSOC 255 "SNA" ;
VAL_ 755 BLEKeyLocation 15 "Reserved" 14 "Reserved" 13 "Reserved" 12 "Reserved" 11 "Reserved" 10 "Reserved" 9 "Reserved" 8 "Auto unlock area" 7 "Auto lock area" 6 "Inside car" 5 "Rear welcome unlock area" 4 "RightFront welcome unlock area" 3 "LeftFront welcome unlock area" 2 "Welcome light on area" 1 "Welcome invalid area" 0 "No BLE Key" ;
VAL_ 685 DVR_AutoDriveDataRecordStatus 3 "Error" 2 "Active" 1 "Standby" 0 "Off" ;
VAL_ 685 DVR_SystemSt 1 "Fault" 0 "No Fault" ;
VAL_ 685 DVR_AutoDriveDataRecordAvailable 1 "Available" 0 "Not available" ;
VAL_ 672 RemoteMonitoringReq 3 "Reserved" 2 "On" 1 "Off" 0 "No Request" ;
VAL_ 672 VehicleDraggingAlert 1 "Active" 0 "Inactive" ;
VAL_ 672 RemoteAVSSharpnessReq 3 "Reserved" 2 "HD" 1 "SD" 0 "No Request" ;
VAL_ 672 RemoteAVSViewModeReq 15 "Reserved" 14 "Reserved" 13 "Reserved" 12 "Reserved" 11 "Screen Dragged 3D View" 10 "Rear Rim view" 9 "Front Rim view" 8 "Reserved" 7 "Rear Wide View" 6 "Front Wide View" 5 "Top View and Right View" 4 "Top View and Left View" 3 "Top View and Rear View" 2 "Top View and Front View" 1 "All Top View" 0 "Inactive" ;
VAL_ 519 HCU_WOBCEnquiry 1 "WOBC station detected,If start charging" 0 "Inactive" ;
VAL_ 519 HCU_WOBCChargerStatus 15 "WOBC Charge Fault" 14 "Reserved" 13 "Reserved" 12 "Reserved" 11 "Reserved" 10 "WOBC charge heating" 9 "WOBC timing charge waiting" 8 "WOBC charge finish" 7 "WOBC charge suspend" 6 "WOBC charging" 5 "WOBC starting" 4 "ECAS adjusting,don°Øt open the door" 3 "WOBC alignment success" 2 "WOBC Aligning" 1 "WOBC Wifi connected" 0 "Idle" ;
VAL_ 519 HCU_ChargerStatus 15 "Charge Fault" 14 "Reserved" 13 "Reserved" 12 "Reserved" 11 "Reserved" 10 "Reserved" 9 "Charge heating" 8 "AC discharge" 7 "Tip:Connect the charger" 6 "Charge timing" 5 "Charge finish" 4 "Charge suspend" 3 "AC charging" 2 "DC charging" 1 "Charge Preparing" 0 "Idle" ;
VAL_ 519 HCU_ChargeConnectStatus 15 "Reserved" 14 "Unusual connect" 13 "Reserved" 12 "Reserved" 11 "Reserved" 10 "Reserved" 9 "Reserved" 8 "Reserved" 7 "Reserved" 6 "AC discharge" 5 "63A AC Connect" 4 "DC connect" 3 "10A AC connect" 2 "16A AC connect" 1 "32A AC connect" 0 "Disconnect" ;
VAL_ 519 HCU_Status 3 "Reserved" 2 "Reserved" 1 "Error" 0 "No error" ;
VAL_ 733 WOBC_ContrapositionPosition_X 1023 "SNA" ;
VAL_ 733 WOBC_ContrapositionPosition_Y 1023 "SNA" ;
VAL_ 733 WOBC_ContrapositionAngle 511 "SNA" ;
VAL_ 732 WOBC_WorkingStatus 7 "Error" 6 "Reserved" 5 "Power Transfer" 4 "Idle" 3 "Awaitin Alignment" 2 "Service initiated" 1 "Standby" 0 "Off" ;
VAL_ 732 WOBC_ContrapositionStatus 15 "Error" 14 "Initial" 13 "Contraposition Overtime" 12 "Contraposition Success" 11 "Reserved" 10 "Reserved" 9 "Reserved" 8 "Reserved" 7 "Reserved" 6 "Reserved" 5 "Reserved" 4 "Right" 3 "Left" 2 "Rear" 1 "Front" 0 "Idle" ;
VAL_ 566 CeremonyModeInd 7 "Reserved" 6 "Reserved" 5 "Mode 5" 4 "Mode 4" 3 "Mode 3" 2 "Mode 2" 1 "Mode 1" 0 "Off" ;
VAL_ 644 AccountID_IVI 15 "SNA" ;
VAL_ 644 AccountBindFaceReq 3 "Reserved" 2 "Unbind" 1 "Bind" 0 "No request" ;
VAL_ 657 DisplayTheme 7 "Reserved" 6 "Reserved" 5 "Reserved" 4 "Reserved" 3 "Theme 3" 2 "Theme 2" 1 "Theme 1" 0 "Inactive" ;
VAL_ 657 HU_ValetModeFuncSet 3 "Reserved" 2 "On" 1 "Off" 0 "Inactive" ;
VAL_ 587 BCM_RemoteParkoutReq_AVP 1 "Parkout request" 0 "No request" ;
VAL_ 587 BCM_RemoteParkoutReq_HPA 1 "Parkout request" 0 "No request" ;
VAL_ 587 BCM_RemoteParkoutReq_RPA 1 "Parkout request" 0 "No request" ;
VAL_ 587 BCM_RemoteParkMonitorModeSt 1 "Active" 0 "Inactive" ;
VAL_ 587 BCM_IGIndication_RemotePark 3 "Reserved" 2 "Ignition on" 1 "Ignition off" 0 "Inactive" ;
VAL_ 587 BCM1_HODError 1 "Error" 0 "No Error" ;
VAL_ 587 BCM1_HandOffDetected_Left 3 "Invalid" 2 "Reserved" 1 "Hands On" 0 "Hands Off" ;
VAL_ 587 BCM1_HandOffDetected_Right 3 "Invalid" 2 "Reserved" 1 "Hands On" 0 "Hands Off" ;
VAL_ 587 BCM1_HandOffDetected_Back 3 "Invalid" 2 "Reserved" 1 "Hands On" 0 "Hands Off" ;
VAL_ 686 TBOXTime_Hour 31 "SNA" ;
VAL_ 686 TBOXTime_Minute 63 "SNA" ;
VAL_ 686 TBOXTime_Second 63 "SNA" ;
VAL_ 686 TBOXTime_Year 127 "SNA" ;
VAL_ 686 TBOXTime_Month 15 "SNA" ;
VAL_ 686 TBOXTime_Day 127 "SNA" ;
VAL_ 686 TBOXTime_Millisecond 1023 "SNA" ;
